BU_:  Airbag BAP_Tester ICAS1_Gateway ICAS1_KommunikationsServer LE1 LE2 Motor_BEV Schaltbetaetigung

BU_:  Airbag BAP_Tester ICAS1_Gateway ICAS1_KommunikationsServer LE1 LE2 Motor_BEV Schaltbetaetigung

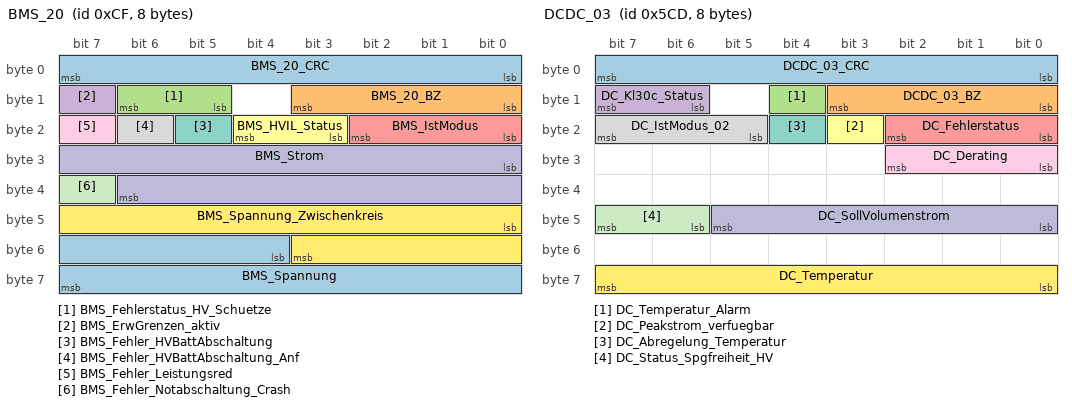
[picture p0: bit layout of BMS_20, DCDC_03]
BO_ 207 BMS_20: 8 ICAS1_Gateway
 SG_ BMS_20_CRC  : 0|8@1+ (1.000000,0.000000) [0.000000|255.000000] "" Motor_BEV
 SG_ BMS_20_BZ  : 8|4@1+ (1.000000,0.000000) [0.000000|15.000000] "" Motor_BEV
 SG_ BMS_Fehlerstatus_HV_Schuetze  : 13|2@1+ (1.000000,0.000000) [0.000000|3.000000] "" Motor_BEV
 SG_ BMS_ErwGrenzen_aktiv  : 15|1@1+ (1.000000,0.000000) [0.000000|1.000000] "" Motor_BEV
 SG_ BMS_IstModus  : 16|3@1+ (1.000000,0.000000) [0.000000|7.000000] "" LE1 LE2 Motor_BEV
 SG_ BMS_HVIL_Status  : 19|2@1+ (1.000000,0.000000) [0.000000|3.000000] "" Motor_BEV
 SG_ BMS_Fehler_HVBattAbschaltung  : 21|1@1+ (1.000000,0.000000) [0.000000|1.000000] "" Motor_BEV
 SG_ BMS_Fehler_HVBattAbschaltung_Anf  : 22|1@1+ (1.000000,0.000000) [0.000000|1.000000] "" Motor_BEV
 SG_ BMS_Fehler_Leistungsred  : 23|1@1+ (1.000000,0.000000) [0.000000|1.000000] "" Motor_BEV
 SG_ BMS_Strom  : 24|15@1+ (0.100000,-1630.000000) [-1630.000000|1630.000000] "Unit_Amper" Motor_BEV
 SG_ BMS_Fehler_Notabschaltung_Crash  : 39|1@1+ (1.000000,0.000000) [0.000000|1.000000] "" Vector__XXX
 SG_ BMS_Spannung_Zwischenkreis  : 40|12@1+ (0.500000,-1000.000000) [-1000.000000|1000.000000] "Unit_Volt" Motor_BEV
 SG_ BMS_Spannung  : 52|12@1+ (0.250000,0.000000) [0.000000|1000.000000] "Unit_Volt" Motor_BEV

BO_ 2463978704 BMS_21: 8 ICAS1_Gateway
 SG_ BMS_Max_Entladestrom  : 12|13@1+ (0.200000,0.000000) [0.000000|1630.000000] "Unit_Amper" Motor_BEV
 SG_ BMS_Max_Ladestrom  : 25|13@1+ (0.200000,0.000000) [0.000000|1630.000000] "Unit_Amper" Motor_BEV
 SG_ BMS_Max_Entladeleistung  : 38|13@1+ (100.000000,0.000000) [0.000000|818000.000000] "Unit_Watt" Motor_BEV
 SG_ BMS_Max_Ladeleistung  : 51|13@1+ (100.000000,0.000000) [0.000000|818000.000000] "Unit_Watt" Motor_BEV

BO_ 2463978705 BMS_22: 8 ICAS1_Gateway
 SG_ BMS_Status_EoHVL_Heizer  : 15|2@1+ (1.000000,0.000000) [0.000000|3.000000] "" Motor_BEV
 SG_ BMS_Ladezustand  : 17|11@1+ (0.050000,0.000000) [0.000000|100.000000] "Unit_PerCent" Motor_BEV
 SG_ BMS_PerfInd_Entladen  : 28|10@1+ (0.200000,0.000000) [0.000000|200.000000] "Unit_PerCent" Motor_BEV
 SG_ BMS_PerfInd_Laden  : 38|10@1+ (0.200000,0.000000) [0.000000|200.000000] "Unit_PerCent" Motor_BEV
 SG_ BMS_Nutzbare_EntladeEnergie  : 48|16@1+ (5.000000,0.000000) [0.000000|327400.000000] "Unit_WattHour" Motor_BEV

BO_ 2589283664 BMS_24: 8 ICAS1_Gateway
 SG_ BMS_Balancing_Aktiv  : 14|2@1+ (1.000000,0.000000) [0.000000|3.000000] "" Vector__XXX
 SG_ BMS_Ladevorgang_aktiv  : 16|1@1+ (1.000000,0.000000) [0.000000|1.000000] "" Vector__XXX
 SG_ BMS_RIso_Ext  : 17|12@1+ (5.000000,0.000000) [0.000000|20465.000000] "Unit_KiloOhm" Motor_BEV
 SG_ BMS_Min_Ladezustand  : 29|11@1+ (0.050000,0.000000) [0.000000|100.000000] "Unit_PerCent" Motor_BEV
 SG_ BMS_Max_Energie  : 40|13@1+ (40.000000,0.000000) [0.000000|327400.000000] "Unit_WattHour" Motor_BEV
 SG_ BMS_Max_Ladezustand  : 53|11@1+ (0.050000,0.000000) [0.000000|100.000000] "Unit_PerCent" Motor_BEV

BO_ 2589283665 BMS_25: 8 ICAS1_Gateway
 SG_ BMS_BattHeizung_VerbautStatus  : 13|1@1+ (1.000000,0.000000) [0.000000|1.000000] "" Motor_BEV
 SG_ BMS_Fehler_NTKreis  : 14|1@1+ (1.000000,0.000000) [0.000000|1.000000] "" Vector__XXX
 SG_ BMS_Temperierung_Anf  : 15|3@1+ (1.000000,0.000000) [0.000000|7.000000] "" Motor_BEV
 SG_ BMS_Status_Ventil1  : 18|3@1+ (1.000000,0.000000) [0.000000|7.000000] "" Motor_BEV
 SG_ BMS_Status_Ventil2  : 21|3@1+ (1.000000,0.000000) [0.000000|7.000000] "" Motor_BEV
 SG_ BMS_Pumpe1_Ansteuerung  : 24|4@1+ (10.000000,0.000000) [0.000000|100.000000] "Unit_PerCent" Motor_BEV
 SG_ BMS_Pumpe2_Ansteuerung  : 28|4@1+ (10.000000,0.000000) [0.000000|100.000000] "Unit_PerCent" Motor_BEV
 SG_ BMS_VorlaufTemperatur  : 32|8@1+ (0.500000,-40.000000) [-40.000000|86.000000] "Unit_DegreCelsi" Motor_BEV
 SG_ BMS_Temperatur  : 40|8@1+ (0.500000,-40.000000) [-40.000000|86.500000] "Unit_DegreCelsi" Motor_BEV
 SG_ BMS_SollVorlauftemperatur  : 48|8@1+ (0.500000,-40.000000) [-40.000000|86.500000] "Unit_DegreCelsi" Motor_BEV
 SG_ BMS_RuecklaufTemperatur  : 56|8@1+ (0.500000,-40.000000) [-40.000000|86.000000] "Unit_DegreCelsi" Motor_BEV

BO_ 2589283760 BMS_26: 8 ICAS1_Gateway
 SG_ BMS_Max_Spannung  : 20|10@1+ (1.000000,0.000000) [0.000000|1000.000000] "Unit_Volt" Motor_BEV
 SG_ BMS_Min_Spannung  : 30|10@1+ (1.000000,0.000000) [0.000000|1000.000000] "Unit_Volt" Motor_BEV
 SG_ BMS_Dauer_Entladeleistung  : 40|12@1+ (200.000000,0.000000) [0.000000|818000.000000] "Unit_Watt" Motor_BEV
 SG_ BMS_Dauer_Ladeleistung  : 52|12@1+ (200.000000,0.000000) [0.000000|818000.000000] "Unit_Watt" Motor_BEV

BO_ 2463978646 Charisma_11: 24 ICAS1_Gateway
 SG_ CHA_Ziel_FahrPr_AGA  : 0|4@1+ (1.000000,0.000000) [0.000000|15.000000] "" Vector__XXX
 SG_ CHA_Ziel_FahrPr_ESP  : 4|4@1+ (1.000000,0.000000) [0.000000|15.000000] "" Motor_BEV
 SG_ CHA_Ziel_FahrPr_Freilauf  : 8|4@1+ (1.000000,0.000000) [0.000000|15.000000] "" Vector__XXX
 SG_ CHA_Fahrer_Umschaltung  : 14|1@1+ (1.000000,0.000000) [0.000000|1.000000] "" Motor_BEV
 SG_ CHA_Fahrer_Umschaltung_BMA  : 15|1@1+ (1.000000,0.000000) [0.000000|1.000000] "" Vector__XXX
 SG_ CHA_Ziel_FahrPr_MO  : 16|4@1+ (1.000000,0.000000) [0.000000|15.000000] "" Motor_BEV
 SG_ CHA_Ziel_FahrPr_GE  : 20|4@1+ (1.000000,0.000000) [0.000000|15.000000] "" Vector__XXX
 SG_ CHA_Ziel_FahrPr_ALR  : 24|4@1+ (1.000000,0.000000) [0.000000|15.000000] "" Motor_BEV
 SG_ CHA_Ziel_FahrPr_MO_BZS  : 28|4@1+ (1.000000,0.000000) [0.000000|15.000000] "" Vector__XXX
 SG_ CHA_Ziel_FahrPr_DR  : 32|4@1+ (1.000000,0.000000) [0.000000|15.000000] "" Vector__XXX
 SG_ CHA_Ziel_FahrPr_VAQ  : 36|4@1+ (1.000000,0.000000) [0.000000|15.000000] "" Vector__XXX
 SG_ CHA_Ziel_FahrPr_AFS  : 40|4@1+ (1.000000,0.000000) [0.000000|15.000000] "" Vector__XXX
 SG_ CHA_Ziel_FahrPr_PreCrash  : 44|4@1+ (1.000000,0.000000) [0.000000|15.000000] "" Airbag
 SG_ CHA_Ziel_FahrPr_EPS  : 48|4@1+ (1.000000,0.000000) [0.000000|15.000000] "" Vector__XXX
 SG_ CHA_Ziel_FahrPr_ACC  : 52|4@1+ (1.000000,0.000000) [0.000000|15.000000] "" Vector__XXX
 SG_ CHA_Ziel_FahrPr_SAK  : 56|4@1+ (1.000000,0.000000) [0.000000|15.000000] "" Vector__XXX
 SG_ CHA_Ziel_FahrPr_MO_StSt  : 60|4@1+ (1.000000,0.000000) [0.000000|15.000000] "" Vector__XXX
 SG_ CHA_Ziel_FahrPr_EBKV  : 64|4@1+ (1.000000,0.000000) [0.000000|15.000000] "" Vector__XXX
 SG_ CHA_Ziel_FahrPr_IL  : 68|4@1+ (1.000000,0.000000) [0.000000|15.000000] "" Vector__XXX
 SG_ CHA_Current_Mode  : 72|4@1+ (1.000000,0.000000) [0.000000|15.000000] "" Vector__XXX
 SG_ CHA_Ziel_FahrPr_QS  : 80|4@1+ (1.000000,0.000000) [0.000000|15.000000] "" Vector__XXX
 SG_ CHA_Ziel_FahrPr_SCU  : 84|4@1+ (1.000000,0.000000) [0.000000|15.000000] "" Vector__XXX
 SG_ CHA_Ziel_FahrPr_HAL  : 88|4@1+ (1.000000,0.000000) [0.000000|15.000000] "" Vector__XXX
 SG_ CHA_Ziel_FahrPr_NR  : 92|4@1+ (1.000000,0.000000) [0.000000|15.000000] "" Vector__XXX
 SG_ CHA_Ziel_FahrPr_AV  : 96|4@1+ (1.000000,0.000000) [0.000000|15.000000] "" Vector__XXX
 SG_ CHA_Ziel_FahrPr_MXB  : 100|4@1+ (1.000000,0.000000) [0.000000|15.000000] "" Vector__XXX
 SG_ CHA_Ziel_FahrPr_AFR  : 104|4@1+ (1.000000,0.000000) [0.000000|15.000000] "" Vector__XXX
 SG_ CHA_Ziel_FahrPr_HDC  : 108|4@1+ (1.000000,0.000000) [0.000000|15.000000] "" Vector__XXX
 SG_ CHA_Ziel_FahrPr_EAR  : 112|4@1+ (1.000000,0.000000) [0.000000|15.000000] "" Vector__XXX
 SG_ CHA_Ziel_FahrPr_AEB  : 116|4@1+ (1.000000,0.000000) [0.000000|15.000000] "" Vector__XXX
 SG_ CHA_Ziel_FahrPr_FCWO  : 120|4@1+ (1.000000,0.000000) [0.000000|15.000000] "" Vector__XXX
 SG_ CHA_Ziel_FahrPr_FCWP  : 124|4@1+ (1.000000,0.000000) [0.000000|15.000000] "" Vector__XXX
 SG_ CHA_Ziel_FahrPr_ToS_laengs  : 144|4@1+ (1.000000,0.000000) [0.000000|15.000000] "" Vector__XXX
 SG_ CHA_Ziel_FahrPr_ToS_quer  : 148|4@1+ (1.000000,0.000000) [0.000000|15.000000] "" Vector__XXX
 SG_ CHA_Ziel_FahrPr_mFDR  : 152|4@1+ (1.000000,0.000000) [0.000000|15.000000] "" Vector__XXX
 SG_ CHA_Ziel_FahrPr_Reku_ZwGas  : 156|4@1+ (1.000000,0.000000) [0.000000|15.000000] "" Vector__XXX
 SG_ CHA_Ziel_FahrPr_MO_Freilauf  : 160|4@1+ (1.000000,0.000000) [0.000000|15.000000] "" Vector__XXX
 SG_ CHA_Ziel_FahrPr_BMS  : 164|4@1+ (1.000000,0.000000) [0.000000|15.000000] "" Vector__XXX
 SG_ CHA_Current_Mode_BMA  : 168|4@1+ (1.000000,0.000000) [0.000000|15.000000] "" Vector__XXX
 SG_ CHA_Ziel_FahrPr_PDC  : 172|4@1+ (1.000000,0.000000) [0.000000|15.000000] "" Vector__XXX
 SG_ CHA_Ziel_FahrPr_HHC  : 176|4@1+ (1.000000,0.000000) [0.000000|15.000000] "" Vector__XXX
 SG_ CHA_Ziel_FahrPr_EDS  : 180|4@1+ (1.000000,0.000000) [0.000000|15.000000] "" Vector__XXX
 SG_ CHA_Ziel_FahrPr_PACC  : 184|4@1+ (1.000000,0.000000) [0.000000|15.000000] "" Vector__XXX
 SG_ CHA_Ziel_FahrPr_AGK  : 188|4@1+ (1.000000,0.000000) [0.000000|15.000000] "" Vector__XXX

BO_ 514 Daempfer_03: 32 ICAS1_Gateway
 SG_ DR_Aufbaubeschleunigung_HR  : 12|10@1+ (0.032700,-15.696000) [-15.696000|15.696000] "Unit_MeterPerSeconSquar" Motor_BEV
 SG_ DR_Aufbaubeschleunigung_VR  : 22|10@1+ (0.032700,-15.696000) [-15.696000|15.696000] "Unit_MeterPerSeconSquar" Motor_BEV
 SG_ DR_Aufbaubeschleunigung_VL  : 32|10@1+ (0.032700,-15.696000) [-15.696000|15.696000] "Unit_MeterPerSeconSquar" Motor_BEV
 SG_ DR_Aufbaubeschleunigung_HL  : 42|10@1+ (0.032700,-15.696000) [-15.696000|15.696000] "Unit_MeterPerSeconSquar" Motor_BEV
 SG_ DR_Funktionsstatus  : 52|2@1+ (1.000000,0.000000) [0.000000|3.000000] "" Vector__XXX
 SG_ DR_Drehwinkelsensortausch_VL  : 72|2@1+ (1.000000,0.000000) [1.000000|3.000000] "" Vector__XXX
 SG_ DR_Drehwinkelsensortausch_VR  : 74|2@1+ (1.000000,0.000000) [1.000000|3.000000] "" Vector__XXX
 SG_ DR_Drehwinkelsensortausch_HL  : 76|2@1+ (1.000000,0.000000) [1.000000|3.000000] "" Vector__XXX
 SG_ DR_Drehwinkelsensortausch_HR  : 78|2@1+ (1.000000,0.000000) [1.000000|3.000000] "" Vector__XXX
 SG_ DR_Drehwinkel_VL  : 80|12@1+ (0.088000,0.000000) [0.000000|359.920000] "" Vector__XXX
 SG_ DR_Drehwinkel_VR  : 92|12@1+ (0.088000,0.000000) [0.000000|359.920000] "" Vector__XXX
 SG_ DR_Drehwinkel_HL  : 104|12@1+ (0.088000,0.000000) [0.000000|359.920000] "" Vector__XXX
 SG_ DR_Drehwinkel_HR  : 116|12@1+ (0.088000,0.000000) [0.000000|359.920000] "" Vector__XXX

BO_ 1485 DCDC_03: 8 ICAS1_Gateway
 SG_ DCDC_03_CRC  : 0|8@1+ (1.000000,0.000000) [0.000000|255.000000] "" Motor_BEV
 SG_ DCDC_03_BZ  : 8|4@1+ (1.000000,0.000000) [0.000000|15.000000] "" Motor_BEV
 SG_ DC_Temperatur_Alarm  : 12|1@1+ (1.000000,0.000000) [0.000000|1.000000] "" Vector__XXX
 SG_ DC_Kl30c_Status  : 14|2@1+ (1.000000,0.000000) [0.000000|3.000000] "" Motor_BEV
 SG_ DC_Fehlerstatus  : 16|3@1+ (1.000000,0.000000) [0.000000|7.000000] "" Vector__XXX
 SG_ DC_Peakstrom_verfuegbar  : 19|1@1+ (1.000000,0.000000) [0.000000|1.000000] "" Vector__XXX
 SG_ DC_Abregelung_Temperatur  : 20|1@1+ (1.000000,0.000000) [0.000000|1.000000] "" Vector__XXX
 SG_ DC_IstModus_02  : 21|3@1+ (1.000000,0.000000) [0.000000|7.000000] "" Vector__XXX
 SG_ DC_Derating  : 24|3@1+ (1.000000,0.000000) [0.000000|7.000000] "" Vector__XXX
 SG_ DC_SollVolumenstrom  : 40|6@1+ (0.500000,0.000000) [0.000000|30.500000] "Unit_LiterPerMinut" Motor_BEV
 SG_ DC_Status_Spgfreiheit_HV  : 46|2@1+ (1.000000,0.000000) [0.000000|3.000000] "" Vector__XXX
 SG_ DC_Temperatur  : 56|8@1+ (1.000000,-40.000000) [-40.000000|213.000000] "Unit_DegreCelsi" Motor_BEV

BO_ 247 DCDC_04: 8 ICAS1_Gateway
 SG_ DCDC_04_CRC  : 0|8@1+ (1.000000,0.000000) [0.000000|255.000000] "" Vector__XXX
 SG_ DCDC_04_BZ  : 8|4@1+ (1.000000,0.000000) [0.000000|15.000000] "" Vector__XXX
 SG_ DC_Vorladung_Status  : 34|1@1+ (1.000000,0.000000) [0.000000|1.000000] "" Motor_BEV
 SG_ DC_Fehler_extern  : 35|1@1+ (1.000000,0.000000) [0.000000|1.000000] "" Motor_BEV
 SG_ DC_Fehler_intern  : 36|1@1+ (1.000000,0.000000) [0.000000|1.000000] "" Motor_BEV
 SG_ DC_Status_Spgfreiheit  : 37|2@1+ (1.000000,0.000000) [0.000000|3.000000] "" Motor_BEV
 SG_ DC_Status_EoHVL  : 39|2@1+ (1.000000,0.000000) [0.000000|3.000000] "" Motor_BEV
 SG_ DC_IstModus_02  : 41|3@1+ (1.000000,0.000000) [0.000000|7.000000] "" Motor_BEV
 SG_ DC_IstStrom_HV  : 44|10@1+ (0.100000,-51.100000) [-51.100000|51.000000] "Unit_Amper" Motor_BEV
 SG_ DC_IstLeistung_HV  : 54|10@1+ (10.000000,-4000.000000) [-4000.000000|6210.000000] "Unit_Watt" Motor_BEV

BO_ 2617027088 DEV_Airbag_ASM_01: 8 Airbag
 SG_ DEV_Airbag_ASM_01_Data  : 0|64@1+ (1.000000,0.000000) [0.000000|18446744073709551616.000000] "" Vector__XXX

BO_ 2617027072 DEV_Airbag_Resp_00: 8 Airbag
 SG_ DEV_Airbag_Resp_00_Data  : 0|64@1+ (1.000000,0.000000) [0.000000|18446744073709551616.000000] "" Vector__XXX

BO_ 2617027073 DEV_Airbag_Resp_01: 8 Airbag
 SG_ DEV_Airbag_Resp_01_Data  : 0|64@1+ (1.000000,0.000000) [0.000000|18446744073709551616.000000] "" Vector__XXX

BO_ 2617027074 DEV_Airbag_Resp_02: 8 Airbag
 SG_ DEV_Airbag_Resp_02_Data  : 0|64@1+ (1.000000,0.000000) [0.000000|18446744073709551616.000000] "" Vector__XXX

BO_ 2617027075 DEV_Airbag_Resp_03: 8 Airbag
 SG_ DEV_Airbag_Resp_03_Data  : 0|64@1+ (1.000000,0.000000) [0.000000|18446744073709551616.000000] "" Vector__XXX

BO_ 2617027076 DEV_Airbag_Resp_04: 8 Airbag
 SG_ DEV_Airbag_Resp_04_Data  : 0|64@1+ (1.000000,0.000000) [0.000000|18446744073709551616.000000] "" Vector__XXX

BO_ 2617027077 DEV_Airbag_Resp_05: 8 Airbag
 SG_ DEV_Airbag_Resp_05_Data  : 0|64@1+ (1.000000,0.000000) [0.000000|18446744073709551616.000000] "" Vector__XXX

BO_ 2617027078 DEV_Airbag_Resp_06: 8 Airbag
 SG_ DEV_Airbag_Resp_06_Data  : 0|64@1+ (1.000000,0.000000) [0.000000|18446744073709551616.000000] "" Vector__XXX

BO_ 2617027079 DEV_Airbag_Resp_07: 8 Airbag
 SG_ DEV_Airbag_Resp_07_Data  : 0|64@1+ (1.000000,0.000000) [0.000000|18446744073709551616.000000] "" Vector__XXX

BO_ 2617027080 DEV_Airbag_Resp_08: 8 Airbag
 SG_ DEV_Airbag_Resp_08_Data  : 0|64@1+ (1.000000,0.000000) [0.000000|18446744073709551616.000000] "" Vector__XXX

BO_ 2617027081 DEV_Airbag_Resp_09: 8 Airbag
 SG_ DEV_Airbag_Resp_09_Data  : 0|64@1+ (1.000000,0.000000) [0.000000|18446744073709551616.000000] "" Vector__XXX

BO_ 2617027082 DEV_Airbag_Resp_10: 8 Airbag
 SG_ DEV_Airbag_Resp_10_Data  : 0|64@1+ (1.000000,0.000000) [0.000000|18446744073709551616.000000] "" Vector__XXX

BO_ 2617027083 DEV_Airbag_Resp_11: 8 Airbag
 SG_ DEV_Airbag_Resp_11_Data  : 0|64@1+ (1.000000,0.000000) [0.000000|18446744073709551616.000000] "" Vector__XXX

BO_ 2617154048 DEV_Waehlhebel_Resp_00: 8 Schaltbetaetigung
 SG_ DEV_Waehlhebel_Resp_00_Data  : 0|64@1+ (1.000000,0.000000) [0.000000|18446744073709551616.000000] "" Vector__XXX

BO_ 2617154049 DEV_Waehlhebel_Resp_01: 8 Schaltbetaetigung
 SG_ DEV_Waehlhebel_Resp_01_Data  : 0|64@1+ (1.000000,0.000000) [0.000000|18446744073709551616.000000] "" Vector__XXX

BO_ 2617154050 DEV_Waehlhebel_Resp_02: 8 Schaltbetaetigung
 SG_ DEV_Waehlhebel_Resp_02_Data  : 0|64@1+ (1.000000,0.000000) [0.000000|18446744073709551616.000000] "" Vector__XXX

BO_ 2617154051 DEV_Waehlhebel_Resp_03: 8 Schaltbetaetigung
 SG_ DEV_Waehlhebel_Resp_03_Data  : 0|64@1+ (1.000000,0.000000) [0.000000|18446744073709551616.000000] "" Vector__XXX

BO_ 2617154052 DEV_Waehlhebel_Resp_04: 8 Schaltbetaetigung
 SG_ DEV_Waehlhebel_Resp_04_Data  : 0|64@1+ (1.000000,0.000000) [0.000000|18446744073709551616.000000] "" Vector__XXX

BO_ 2617154053 DEV_Waehlhebel_Resp_05: 8 Schaltbetaetigung
 SG_ DEV_Waehlhebel_Resp_05_Data  : 0|64@1+ (1.000000,0.000000) [0.000000|18446744073709551616.000000] "" Vector__XXX

BO_ 2549876269 Diag_Waehlhebel_Req: 8 Motor_BEV
 SG_ Diag_Waehlhebel_Req_Data  : 0|64@1+ (1.000000,0.000000) [0.000000|18446744073709551616.000000] "" Schaltbetaetigung

BO_ 2550007341 Diag_Waehlhebel_Resp: 8 Schaltbetaetigung
 SG_ Diag_Waehlhebel_Resp_Data  : 0|64@1+ (1.000000,0.000000) [0.000000|18446744073709551616.000000] "" Motor_BEV

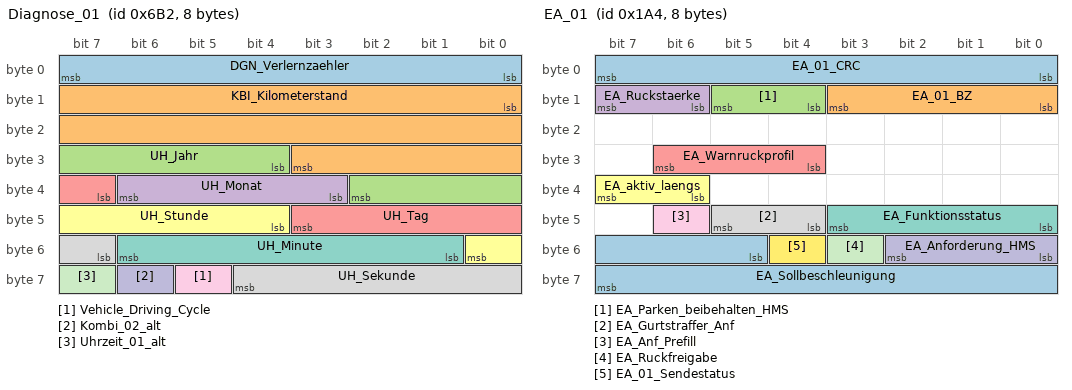
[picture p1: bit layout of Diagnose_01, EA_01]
BO_ 1714 Diagnose_01: 8 ICAS1_Gateway
 SG_ DGN_Verlernzaehler  : 0|8@1+ (1.000000,0.000000) [0.000000|254.000000] "" Airbag LE1 LE2 Motor_BEV
 SG_ KBI_Kilometerstand  : 8|20@1+ (1.000000,0.000000) [0.000000|1048573.000000] "Unit_KiloMeter" Airbag LE1 LE2 Motor_BEV
 SG_ UH_Jahr  : 28|7@1+ (1.000000,2000.000000) [2000.000000|2127.000000] "Unit_Year" Airbag LE1 LE2 Motor_BEV
 SG_ UH_Monat  : 35|4@1+ (1.000000,0.000000) [1.000000|12.000000] "Unit_Month" Airbag LE1 LE2 Motor_BEV
 SG_ UH_Tag  : 39|5@1+ (1.000000,0.000000) [1.000000|31.000000] "Unit_Day" Airbag LE1 LE2 Motor_BEV
 SG_ UH_Stunde  : 44|5@1+ (1.000000,0.000000) [0.000000|23.000000] "Unit_Hours" Airbag LE1 LE2 Motor_BEV
 SG_ UH_Minute  : 49|6@1+ (1.000000,0.000000) [0.000000|59.000000] "Unit_Minut" Airbag LE1 LE2 Motor_BEV
 SG_ UH_Sekunde  : 55|6@1+ (1.000000,0.000000) [0.000000|59.000000] "Unit_Secon" Airbag LE1 LE2 Motor_BEV
 SG_ Vehicle_Driving_Cycle  : 61|1@1+ (1.000000,0.000000) [0.000000|1.000000] "" Airbag
 SG_ Kombi_02_alt  : 62|1@1+ (1.000000,0.000000) [0.000000|1.000000] "" Vector__XXX
 SG_ Uhrzeit_01_alt  : 63|1@1+ (1.000000,0.000000) [0.000000|1.000000] "" Vector__XXX

BO_ 851 DiETa_01: 8 ICAS1_Gateway
 SG_ DiETas_01_CRC  : 0|8@1+ (1.000000,0.000000) [0.000000|255.000000] "" Airbag
 SG_ DiETas_01_BZ  : 8|4@1+ (1.000000,0.000000) [0.000000|15.000000] "" Airbag
 SG_ DiETa_Reserve_Byte2_4  : 12|1@1+ (1.000000,0.000000) [0.000000|1.000000] "" Vector__XXX
 SG_ DiETa_Status  : 13|2@1+ (1.000000,0.000000) [0.000000|3.000000] "" Airbag
 SG_ DiETa_ResponseError  : 15|1@1+ (1.000000,0.000000) [0.000000|1.000000] "" Vector__XXX
 SG_ DiETa_Car  : 16|2@1+ (1.000000,0.000000) [0.000000|3.000000] "" Vector__XXX
 SG_ DiETa_Klima  : 18|2@1+ (1.000000,0.000000) [0.000000|3.000000] "" Vector__XXX
 SG_ DiETa_Mode  : 20|2@1+ (1.000000,0.000000) [0.000000|3.000000] "" Vector__XXX
 SG_ DiETa_Parken  : 22|2@1+ (1.000000,0.000000) [0.000000|3.000000] "" Vector__XXX
 SG_ DiETa_FSH_Taste  : 24|2@1+ (1.000000,0.000000) [0.000000|3.000000] "" Vector__XXX
 SG_ DiETa_HSH_Taste  : 26|2@1+ (1.000000,0.000000) [0.000000|3.000000] "" Vector__XXX
 SG_ DiETa_Warnblink_Taste  : 28|2@1+ (1.000000,0.000000) [0.000000|3.000000] "" Vector__XXX
 SG_ DiETa_FAS_Stufe  : 30|2@1+ (1.000000,0.000000) [0.000000|3.000000] "" Vector__XXX
 SG_ DiETa_PAO_ON_Status  : 32|2@1+ (1.000000,0.000000) [0.000000|3.000000] "" Airbag
 SG_ DiETa_PAO_OFF_Status  : 34|2@1+ (1.000000,0.000000) [0.000000|3.000000] "" Airbag
 SG_ DiETa_Defrost_Taste  : 36|2@1+ (1.000000,0.000000) [0.000000|3.000000] "" Vector__XXX
 SG_ DiETa_Reserve_Byte5_6  : 38|2@1+ (1.000000,0.000000) [0.000000|3.000000] "" Vector__XXX
 SG_ DiETa_Lock_Unlock_Taste  : 40|3@1+ (1.000000,0.000000) [0.000000|7.000000] "" Vector__XXX
 SG_ DiETa_Mode_roh  : 43|1@1+ (1.000000,0.000000) [0.000000|1.000000] "" Vector__XXX
 SG_ DiETa_Reserve_Byte6_3  : 44|4@1+ (1.000000,0.000000) [0.000000|15.000000] "" Vector__XXX
 SG_ DiETa_Reserve_Byte7  : 48|8@1+ (1.000000,0.000000) [0.000000|255.000000] "" Vector__XXX
 SG_ DiETa_Reserve_Byte8  : 56|8@1+ (1.000000,0.000000) [0.000000|255.000000] "" Vector__XXX

BO_ 1520 Dimmung_01: 8 ICAS1_Gateway
 SG_ DI_KL_58xd  : 0|8@1+ (1.000000,0.000000) [0.000000|253.000000] "" Airbag Schaltbetaetigung
 SG_ DI_KL_58xs  : 8|7@1+ (1.000000,0.000000) [0.000000|100.000000] "Unit_PerCent" Airbag
 SG_ DI_Display_Nachtdesign  : 15|1@1+ (1.000000,0.000000) [0.000000|1.000000] "" Vector__XXX
 SG_ DI_KL_58xt  : 16|7@1+ (1.000000,0.000000) [0.000000|100.000000] "Unit_PerCent" Airbag Schaltbetaetigung
 SG_ DI_Fotosensor  : 24|16@1+ (1.000000,0.000000) [0.000000|65535.000000] "" Vector__XXX
 SG_ BCM1_Stellgroesse_Kl_58s  : 40|7@1+ (1.000000,0.000000) [0.000000|100.000000] "" Vector__XXX

BO_ 420 EA_01: 8 ICAS1_Gateway
 SG_ EA_01_CRC  : 0|8@1+ (1.000000,0.000000) [0.000000|255.000000] "" Motor_BEV
 SG_ EA_01_BZ  : 8|4@1+ (1.000000,0.000000) [0.000000|15.000000] "" Motor_BEV
 SG_ EA_Parken_beibehalten_HMS  : 12|2@1+ (1.000000,0.000000) [0.000000|3.000000] "" Vector__XXX
 SG_ EA_Ruckstaerke  : 14|2@1+ (1.000000,0.000000) [0.000000|3.000000] "" Vector__XXX
 SG_ EA_Warnruckprofil  : 28|3@1+ (1.000000,0.000000) [0.000000|7.000000] "" Vector__XXX
 SG_ EA_aktiv_laengs  : 38|2@1+ (1.000000,0.000000) [0.000000|3.000000] "" Motor_BEV
 SG_ EA_Funktionsstatus  : 40|4@1+ (1.000000,0.000000) [0.000000|15.000000] "" Motor_BEV
 SG_ EA_Gurtstraffer_Anf  : 44|2@1+ (1.000000,0.000000) [0.000000|3.000000] "" Airbag
 SG_ EA_Anf_Prefill  : 46|1@1+ (1.000000,0.000000) [0.000000|1.000000] "" Vector__XXX
 SG_ EA_Anforderung_HMS  : 48|3@1+ (1.000000,0.000000) [0.000000|7.000000] "" Vector__XXX
 SG_ EA_Ruckfreigabe  : 51|1@1+ (1.000000,0.000000) [0.000000|1.000000] "" Vector__XXX
 SG_ EA_01_Sendestatus  : 52|1@1+ (1.000000,0.000000) [0.000000|1.000000] "" Vector__XXX
 SG_ EA_Sollbeschleunigung  : 53|11@1+ (0.005000,-7.220000) [-7.220000|3.005000] "Unit_MeterPerSeconSquar" Motor_BEV

BO_ 374 EBKV_03: 8 ICAS1_Gateway
 SG_ EBKV_03_CRC  : 0|8@1+ (1.000000,0.000000) [0.000000|255.000000] "" Vector__XXX
 SG_ EBKV_03_BZ  : 8|4@1+ (1.000000,0.000000) [0.000000|15.000000] "" Vector__XXX
 SG_ EBKV_Activate_Fallback_ESP  : 12|1@1+ (1.000000,0.000000) [0.000000|1.000000] "" Vector__XXX
 SG_ EBKV_Restdruckabsenkung  : 13|3@1+ (1.000000,0.000000) [0.000000|7.000000] "" Vector__XXX
 SG_ EBKV_Status_02  : 16|4@1+ (1.000000,0.000000) [0.000000|15.000000] "" Vector__XXX
 SG_ EBKV_Diagnose  : 20|1@1+ (1.000000,0.000000) [0.000000|1.000000] "" Vector__XXX
 SG_ EBKV_Fahrer_bremst  : 21|1@1+ (1.000000,0.000000) [0.000000|1.000000] "" Motor_BEV
 SG_ EBKV_QBit_Fahrer_bremst  : 22|1@1+ (1.000000,0.000000) [0.000000|1.000000] "" Motor_BEV
 SG_ EBKV_Fahrer_bremst_deutlich  : 23|1@1+ (1.000000,0.000000) [0.000000|1.000000] "" Vector__XXX
 SG_ EBKV_OBD_Status  : 24|1@1+ (1.000000,0.000000) [0.000000|1.000000] "" Motor_BEV
 SG_ EBKV_VMM_Sek_Notstopp_Status  : 25|3@1+ (1.000000,0.000000) [0.000000|7.000000] "" Vector__XXX
 SG_ EBKV_Anforderung_HMS  : 28|3@1+ (1.000000,0.000000) [0.000000|7.000000] "" Vector__XXX
 SG_ SBS_Anforderung_GE  : 31|1@1+ (1.000000,0.000000) [0.000000|1.000000] "" Vector__XXX
 SG_ EPB_Status_ext  : 32|3@1+ (1.000000,0.000000) [0.000000|7.000000] "" Motor_BEV
 SG_ EBKV_Bremspedalweg  : 40|8@1+ (0.400000,-0.400000) [0.000000|101.200000] "Unit_PerCent" Motor_BEV
 SG_ EBKV_Kraftblending_Reserve  : 48|8@1+ (0.500000,0.000000) [0.000000|125.000000] "Unit_Bar" Vector__XXX
 SG_ EBKV_Aussteuerdruck  : 56|8@1+ (1.000000,0.000000) [0.000000|250.000000] "Unit_Bar" Vector__XXX

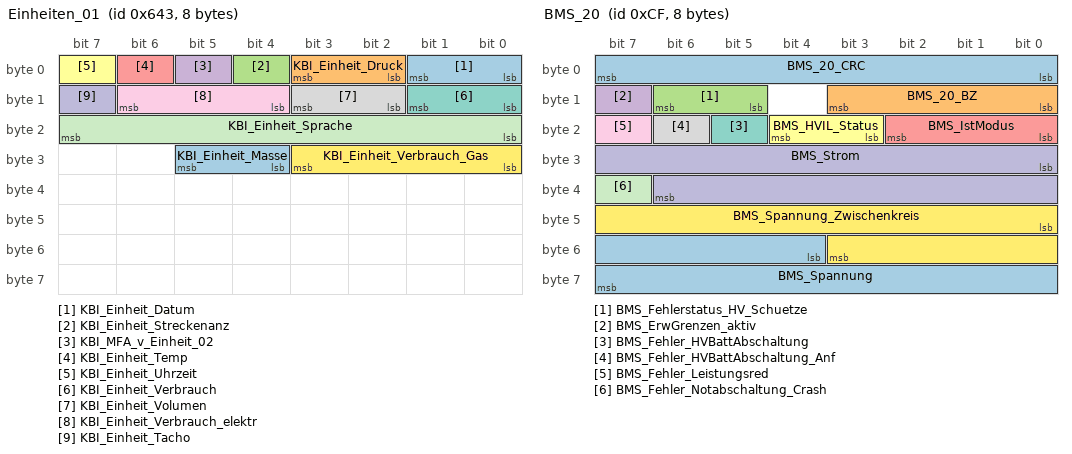
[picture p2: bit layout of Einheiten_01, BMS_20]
BO_ 1603 Einheiten_01: 8 ICAS1_KommunikationsServer
 SG_ KBI_Einheit_Datum  : 0|2@1+ (1.000000,0.000000) [0.000000|3.000000] "" Vector__XXX
 SG_ KBI_Einheit_Druck  : 2|2@1+ (1.000000,0.000000) [0.000000|3.000000] "" Vector__XXX
 SG_ KBI_Einheit_Streckenanz  : 4|1@1+ (1.000000,0.000000) [0.000000|1.000000] "" Vector__XXX
 SG_ KBI_MFA_v_Einheit_02  : 5|1@1+ (1.000000,0.000000) [0.000000|1.000000] "" Motor_BEV
 SG_ KBI_Einheit_Temp  : 6|1@1+ (1.000000,0.000000) [0.000000|1.000000] "" Vector__XXX
 SG_ KBI_Einheit_Uhrzeit  : 7|1@1+ (1.000000,0.000000) [0.000000|1.000000] "" Vector__XXX
 SG_ KBI_Einheit_Verbrauch  : 8|2@1+ (1.000000,0.000000) [0.000000|3.000000] "" Vector__XXX
 SG_ KBI_Einheit_Volumen  : 10|2@1+ (1.000000,0.000000) [0.000000|3.000000] "" Vector__XXX
 SG_ KBI_Einheit_Verbrauch_elektr  : 12|3@1+ (1.000000,0.000000) [0.000000|7.000000] "" Vector__XXX
 SG_ KBI_Einheit_Tacho  : 15|1@1+ (1.000000,0.000000) [0.000000|1.000000] "" Motor_BEV
 SG_ KBI_Einheit_Sprache  : 16|8@1+ (1.000000,0.000000) [0.000000|255.000000] "" Vector__XXX
 SG_ KBI_Einheit_Verbrauch_Gas  : 24|4@1+ (1.000000,0.000000) [0.000000|15.000000] "" Vector__XXX
 SG_ KBI_Einheit_Masse  : 28|2@1+ (1.000000,0.000000) [0.000000|3.000000] "" Vector__XXX

BU_:  Airbag BAP_Tester ICAS1_Gateway ICAS1_KommunikationsServer LE1 LE2 Motor_BEV Schaltbetaetigung

BO_ 207 BMS_20: 8 ICAS1_Gateway
 SG_ BMS_20_CRC  : 0|8@1+ (1.000000,0.000000) [0.000000|255.000000] "" Motor_BEV
 SG_ BMS_20_BZ  : 8|4@1+ (1.000000,0.000000) [0.000000|15.000000] "" Motor_BEV
 SG_ BMS_Fehlerstatus_HV_Schuetze  : 13|2@1+ (1.000000,0.000000) [0.000000|3.000000] "" Motor_BEV
 SG_ BMS_ErwGrenzen_aktiv  : 15|1@1+ (1.000000,0.000000) [0.000000|1.000000] "" Motor_BEV
 SG_ BMS_IstModus  : 16|3@1+ (1.000000,0.000000) [0.000000|7.000000] "" LE1 LE2 Motor_BEV
 SG_ BMS_HVIL_Status  : 19|2@1+ (1.000000,0.000000) [0.000000|3.000000] "" Motor_BEV
 SG_ BMS_Fehler_HVBattAbschaltung  : 21|1@1+ (1.000000,0.000000) [0.000000|1.000000] "" Motor_BEV
 SG_ BMS_Fehler_HVBattAbschaltung_Anf  : 22|1@1+ (1.000000,0.000000) [0.000000|1.000000] "" Motor_BEV
 SG_ BMS_Fehler_Leistungsred  : 23|1@1+ (1.000000,0.000000) [0.000000|1.000000] "" Motor_BEV
 SG_ BMS_Strom  : 24|15@1+ (0.100000,-1630.000000) [-1630.000000|1630.000000] "Unit_Amper" Motor_BEV
 SG_ BMS_Fehler_Notabschaltung_Crash  : 39|1@1+ (1.000000,0.000000) [0.000000|1.000000] "" Vector__XXX
 SG_ BMS_Spannung_Zwischenkreis  : 40|12@1+ (0.500000,-1000.000000) [-1000.000000|1000.000000] "Unit_Volt" Motor_BEV
 SG_ BMS_Spannung  : 52|12@1+ (0.250000,0.000000) [0.000000|1000.000000] "Unit_Volt" Motor_BEV

BO_ 2463978704 BMS_21: 8 ICAS1_Gateway
 SG_ BMS_Max_Entladestrom  : 12|13@1+ (0.200000,0.000000) [0.000000|1630.000000] "Unit_Amper" Motor_BEV
 SG_ BMS_Max_Ladestrom  : 25|13@1+ (0.200000,0.000000) [0.000000|1630.000000] "Unit_Amper" Motor_BEV
 SG_ BMS_Max_Entladeleistung  : 38|13@1+ (100.000000,0.000000) [0.000000|818000.000000] "Unit_Watt" Motor_BEV
 SG_ BMS_Max_Ladeleistung  : 51|13@1+ (100.000000,0.000000) [0.000000|818000.000000] "Unit_Watt" Motor_BEV

BO_ 2463978705 BMS_22: 8 ICAS1_Gateway
 SG_ BMS_Status_EoHVL_Heizer  : 15|2@1+ (1.000000,0.000000) [0.000000|3.000000] "" Motor_BEV
 SG_ BMS_Ladezustand  : 17|11@1+ (0.050000,0.000000) [0.000000|100.000000] "Unit_PerCent" Motor_BEV
 SG_ BMS_PerfInd_Entladen  : 28|10@1+ (0.200000,0.000000) [0.000000|200.000000] "Unit_PerCent" Motor_BEV
 SG_ BMS_PerfInd_Laden  : 38|10@1+ (0.200000,0.000000) [0.000000|200.000000] "Unit_PerCent" Motor_BEV
 SG_ BMS_Nutzbare_EntladeEnergie  : 48|16@1+ (5.000000,0.000000) [0.000000|327400.000000] "Unit_WattHour" Motor_BEV

BO_ 2589283664 BMS_24: 8 ICAS1_Gateway
 SG_ BMS_Balancing_Aktiv  : 14|2@1+ (1.000000,0.000000) [0.000000|3.000000] "" Vector__XXX
 SG_ BMS_Ladevorgang_aktiv  : 16|1@1+ (1.000000,0.000000) [0.000000|1.000000] "" Vector__XXX
 SG_ BMS_RIso_Ext  : 17|12@1+ (5.000000,0.000000) [0.000000|20465.000000] "Unit_KiloOhm" Motor_BEV
 SG_ BMS_Min_Ladezustand  : 29|11@1+ (0.050000,0.000000) [0.000000|100.000000] "Unit_PerCent" Motor_BEV
 SG_ BMS_Max_Energie  : 40|13@1+ (40.000000,0.000000) [0.000000|327400.000000] "Unit_WattHour" Motor_BEV
 SG_ BMS_Max_Ladezustand  : 53|11@1+ (0.050000,0.000000) [0.000000|100.000000] "Unit_PerCent" Motor_BEV

BO_ 2589283665 BMS_25: 8 ICAS1_Gateway
 SG_ BMS_BattHeizung_VerbautStatus  : 13|1@1+ (1.000000,0.000000) [0.000000|1.000000] "" Motor_BEV
 SG_ BMS_Fehler_NTKreis  : 14|1@1+ (1.000000,0.000000) [0.000000|1.000000] "" Vector__XXX
 SG_ BMS_Temperierung_Anf  : 15|3@1+ (1.000000,0.000000) [0.000000|7.000000] "" Motor_BEV
 SG_ BMS_Status_Ventil1  : 18|3@1+ (1.000000,0.000000) [0.000000|7.000000] "" Motor_BEV
 SG_ BMS_Status_Ventil2  : 21|3@1+ (1.000000,0.000000) [0.000000|7.000000] "" Motor_BEV
 SG_ BMS_Pumpe1_Ansteuerung  : 24|4@1+ (10.000000,0.000000) [0.000000|100.000000] "Unit_PerCent" Motor_BEV
 SG_ BMS_Pumpe2_Ansteuerung  : 28|4@1+ (10.000000,0.000000) [0.000000|100.000000] "Unit_PerCent" Motor_BEV
 SG_ BMS_VorlaufTemperatur  : 32|8@1+ (0.500000,-40.000000) [-40.000000|86.000000] "Unit_DegreCelsi" Motor_BEV
 SG_ BMS_Temperatur  : 40|8@1+ (0.500000,-40.000000) [-40.000000|86.500000] "Unit_DegreCelsi" Motor_BEV
 SG_ BMS_SollVorlauftemperatur  : 48|8@1+ (0.500000,-40.000000) [-40.000000|86.500000] "Unit_DegreCelsi" Motor_BEV
 SG_ BMS_RuecklaufTemperatur  : 56|8@1+ (0.500000,-40.000000) [-40.000000|86.000000] "Unit_DegreCelsi" Motor_BEV

BO_ 2589283760 BMS_26: 8 ICAS1_Gateway
 SG_ BMS_Max_Spannung  : 20|10@1+ (1.000000,0.000000) [0.000000|1000.000000] "Unit_Volt" Motor_BEV
 SG_ BMS_Min_Spannung  : 30|10@1+ (1.000000,0.000000) [0.000000|1000.000000] "Unit_Volt" Motor_BEV
 SG_ BMS_Dauer_Entladeleistung  : 40|12@1+ (200.000000,0.000000) [0.000000|818000.000000] "Unit_Watt" Motor_BEV
 SG_ BMS_Dauer_Ladeleistung  : 52|12@1+ (200.000000,0.000000) [0.000000|818000.000000] "Unit_Watt" Motor_BEV

BO_ 2463978646 Charisma_11: 24 ICAS1_Gateway
 SG_ CHA_Ziel_FahrPr_AGA  : 0|4@1+ (1.000000,0.000000) [0.000000|15.000000] "" Vector__XXX
 SG_ CHA_Ziel_FahrPr_ESP  : 4|4@1+ (1.000000,0.000000) [0.000000|15.000000] "" Motor_BEV
 SG_ CHA_Ziel_FahrPr_Freilauf  : 8|4@1+ (1.000000,0.000000) [0.000000|15.000000] "" Vector__XXX
 SG_ CHA_Fahrer_Umschaltung  : 14|1@1+ (1.000000,0.000000) [0.000000|1.000000] "" Motor_BEV
 SG_ CHA_Fahrer_Umschaltung_BMA  : 15|1@1+ (1.000000,0.000000) [0.000000|1.000000] "" Vector__XXX
 SG_ CHA_Ziel_FahrPr_MO  : 16|4@1+ (1.000000,0.000000) [0.000000|15.000000] "" Motor_BEV
 SG_ CHA_Ziel_FahrPr_GE  : 20|4@1+ (1.000000,0.000000) [0.000000|15.000000] "" Vector__XXX
 SG_ CHA_Ziel_FahrPr_ALR  : 24|4@1+ (1.000000,0.000000) [0.000000|15.000000] "" Motor_BEV
 SG_ CHA_Ziel_FahrPr_MO_BZS  : 28|4@1+ (1.000000,0.000000) [0.000000|15.000000] "" Vector__XXX
 SG_ CHA_Ziel_FahrPr_DR  : 32|4@1+ (1.000000,0.000000) [0.000000|15.000000] "" Vector__XXX
 SG_ CHA_Ziel_FahrPr_VAQ  : 36|4@1+ (1.000000,0.000000) [0.000000|15.000000] "" Vector__XXX
 SG_ CHA_Ziel_FahrPr_AFS  : 40|4@1+ (1.000000,0.000000) [0.000000|15.000000] "" Vector__XXX
 SG_ CHA_Ziel_FahrPr_PreCrash  : 44|4@1+ (1.000000,0.000000) [0.000000|15.000000] "" Airbag
 SG_ CHA_Ziel_FahrPr_EPS  : 48|4@1+ (1.000000,0.000000) [0.000000|15.000000] "" Vector__XXX
 SG_ CHA_Ziel_FahrPr_ACC  : 52|4@1+ (1.000000,0.000000) [0.000000|15.000000] "" Vector__XXX
 SG_ CHA_Ziel_FahrPr_SAK  : 56|4@1+ (1.000000,0.000000) [0.000000|15.000000] "" Vector__XXX
 SG_ CHA_Ziel_FahrPr_MO_StSt  : 60|4@1+ (1.000000,0.000000) [0.000000|15.000000] "" Vector__XXX
 SG_ CHA_Ziel_FahrPr_EBKV  : 64|4@1+ (1.000000,0.000000) [0.000000|15.000000] "" Vector__XXX
 SG_ CHA_Ziel_FahrPr_IL  : 68|4@1+ (1.000000,0.000000) [0.000000|15.000000] "" Vector__XXX
 SG_ CHA_Current_Mode  : 72|4@1+ (1.000000,0.000000) [0.000000|15.000000] "" Vector__XXX
 SG_ CHA_Ziel_FahrPr_QS  : 80|4@1+ (1.000000,0.000000) [0.000000|15.000000] "" Vector__XXX
 SG_ CHA_Ziel_FahrPr_SCU  : 84|4@1+ (1.000000,0.000000) [0.000000|15.000000] "" Vector__XXX
 SG_ CHA_Ziel_FahrPr_HAL  : 88|4@1+ (1.000000,0.000000) [0.000000|15.000000] "" Vector__XXX
 SG_ CHA_Ziel_FahrPr_NR  : 92|4@1+ (1.000000,0.000000) [0.000000|15.000000] "" Vector__XXX
 SG_ CHA_Ziel_FahrPr_AV  : 96|4@1+ (1.000000,0.000000) [0.000000|15.000000] "" Vector__XXX
 SG_ CHA_Ziel_FahrPr_MXB  : 100|4@1+ (1.000000,0.000000) [0.000000|15.000000] "" Vector__XXX
 SG_ CHA_Ziel_FahrPr_AFR  : 104|4@1+ (1.000000,0.000000) [0.000000|15.000000] "" Vector__XXX
 SG_ CHA_Ziel_FahrPr_HDC  : 108|4@1+ (1.000000,0.000000) [0.000000|15.000000] "" Vector__XXX
 SG_ CHA_Ziel_FahrPr_EAR  : 112|4@1+ (1.000000,0.000000) [0.000000|15.000000] "" Vector__XXX
 SG_ CHA_Ziel_FahrPr_AEB  : 116|4@1+ (1.000000,0.000000) [0.000000|15.000000] "" Vector__XXX
 SG_ CHA_Ziel_FahrPr_FCWO  : 120|4@1+ (1.000000,0.000000) [0.000000|15.000000] "" Vector__XXX
 SG_ CHA_Ziel_FahrPr_FCWP  : 124|4@1+ (1.000000,0.000000) [0.000000|15.000000] "" Vector__XXX
 SG_ CHA_Ziel_FahrPr_ToS_laengs  : 144|4@1+ (1.000000,0.000000) [0.000000|15.000000] "" Vector__XXX
 SG_ CHA_Ziel_FahrPr_ToS_quer  : 148|4@1+ (1.000000,0.000000) [0.000000|15.000000] "" Vector__XXX
 SG_ CHA_Ziel_FahrPr_mFDR  : 152|4@1+ (1.000000,0.000000) [0.000000|15.000000] "" Vector__XXX
 SG_ CHA_Ziel_FahrPr_Reku_ZwGas  : 156|4@1+ (1.000000,0.000000) [0.000000|15.000000] "" Vector__XXX
 SG_ CHA_Ziel_FahrPr_MO_Freilauf  : 160|4@1+ (1.000000,0.000000) [0.000000|15.000000] "" Vector__XXX
 SG_ CHA_Ziel_FahrPr_BMS  : 164|4@1+ (1.000000,0.000000) [0.000000|15.000000] "" Vector__XXX
 SG_ CHA_Current_Mode_BMA  : 168|4@1+ (1.000000,0.000000) [0.000000|15.000000] "" Vector__XXX
 SG_ CHA_Ziel_FahrPr_PDC  : 172|4@1+ (1.000000,0.000000) [0.000000|15.000000] "" Vector__XXX
 SG_ CHA_Ziel_FahrPr_HHC  : 176|4@1+ (1.000000,0.000000) [0.000000|15.000000] "" Vector__XXX
 SG_ CHA_Ziel_FahrPr_EDS  : 180|4@1+ (1.000000,0.000000) [0.000000|15.000000] "" Vector__XXX
 SG_ CHA_Ziel_FahrPr_PACC  : 184|4@1+ (1.000000,0.000000) [0.000000|15.000000] "" Vector__XXX
 SG_ CHA_Ziel_FahrPr_AGK  : 188|4@1+ (1.000000,0.000000) [0.000000|15.000000] "" Vector__XXX

BO_ 514 Daempfer_03: 32 ICAS1_Gateway
 SG_ DR_Aufbaubeschleunigung_HR  : 12|10@1+ (0.032700,-15.696000) [-15.696000|15.696000] "Unit_MeterPerSeconSquar" Motor_BEV
 SG_ DR_Aufbaubeschleunigung_VR  : 22|10@1+ (0.032700,-15.696000) [-15.696000|15.696000] "Unit_MeterPerSeconSquar" Motor_BEV
 SG_ DR_Aufbaubeschleunigung_VL  : 32|10@1+ (0.032700,-15.696000) [-15.696000|15.696000] "Unit_MeterPerSeconSquar" Motor_BEV
 SG_ DR_Aufbaubeschleunigung_HL  : 42|10@1+ (0.032700,-15.696000) [-15.696000|15.696000] "Unit_MeterPerSeconSquar" Motor_BEV
 SG_ DR_Funktionsstatus  : 52|2@1+ (1.000000,0.000000) [0.000000|3.000000] "" Vector__XXX
 SG_ DR_Drehwinkelsensortausch_VL  : 72|2@1+ (1.000000,0.000000) [1.000000|3.000000] "" Vector__XXX
 SG_ DR_Drehwinkelsensortausch_VR  : 74|2@1+ (1.000000,0.000000) [1.000000|3.000000] "" Vector__XXX
 SG_ DR_Drehwinkelsensortausch_HL  : 76|2@1+ (1.000000,0.000000) [1.000000|3.000000] "" Vector__XXX
 SG_ DR_Drehwinkelsensortausch_HR  : 78|2@1+ (1.000000,0.000000) [1.000000|3.000000] "" Vector__XXX
 SG_ DR_Drehwinkel_VL  : 80|12@1+ (0.088000,0.000000) [0.000000|359.920000] "" Vector__XXX
 SG_ DR_Drehwinkel_VR  : 92|12@1+ (0.088000,0.000000) [0.000000|359.920000] "" Vector__XXX
 SG_ DR_Drehwinkel_HL  : 104|12@1+ (0.088000,0.000000) [0.000000|359.920000] "" Vector__XXX
 SG_ DR_Drehwinkel_HR  : 116|12@1+ (0.088000,0.000000) [0.000000|359.920000] "" Vector__XXX

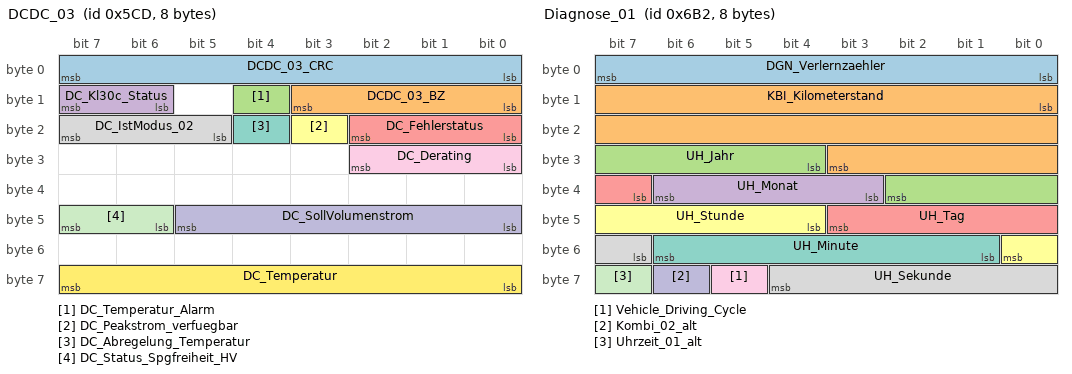
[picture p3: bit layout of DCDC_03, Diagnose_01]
BO_ 1485 DCDC_03: 8 ICAS1_Gateway
 SG_ DCDC_03_CRC  : 0|8@1+ (1.000000,0.000000) [0.000000|255.000000] "" Motor_BEV
 SG_ DCDC_03_BZ  : 8|4@1+ (1.000000,0.000000) [0.000000|15.000000] "" Motor_BEV
 SG_ DC_Temperatur_Alarm  : 12|1@1+ (1.000000,0.000000) [0.000000|1.000000] "" Vector__XXX
 SG_ DC_Kl30c_Status  : 14|2@1+ (1.000000,0.000000) [0.000000|3.000000] "" Motor_BEV
 SG_ DC_Fehlerstatus  : 16|3@1+ (1.000000,0.000000) [0.000000|7.000000] "" Vector__XXX
 SG_ DC_Peakstrom_verfuegbar  : 19|1@1+ (1.000000,0.000000) [0.000000|1.000000] "" Vector__XXX
 SG_ DC_Abregelung_Temperatur  : 20|1@1+ (1.000000,0.000000) [0.000000|1.000000] "" Vector__XXX
 SG_ DC_IstModus_02  : 21|3@1+ (1.000000,0.000000) [0.000000|7.000000] "" Vector__XXX
 SG_ DC_Derating  : 24|3@1+ (1.000000,0.000000) [0.000000|7.000000] "" Vector__XXX
 SG_ DC_SollVolumenstrom  : 40|6@1+ (0.500000,0.000000) [0.000000|30.500000] "Unit_LiterPerMinut" Motor_BEV
 SG_ DC_Status_Spgfreiheit_HV  : 46|2@1+ (1.000000,0.000000) [0.000000|3.000000] "" Vector__XXX
 SG_ DC_Temperatur  : 56|8@1+ (1.000000,-40.000000) [-40.000000|213.000000] "Unit_DegreCelsi" Motor_BEV

BO_ 247 DCDC_04: 8 ICAS1_Gateway
 SG_ DCDC_04_CRC  : 0|8@1+ (1.000000,0.000000) [0.000000|255.000000] "" Vector__XXX
 SG_ DCDC_04_BZ  : 8|4@1+ (1.000000,0.000000) [0.000000|15.000000] "" Vector__XXX
 SG_ DC_Vorladung_Status  : 34|1@1+ (1.000000,0.000000) [0.000000|1.000000] "" Motor_BEV
 SG_ DC_Fehler_extern  : 35|1@1+ (1.000000,0.000000) [0.000000|1.000000] "" Motor_BEV
 SG_ DC_Fehler_intern  : 36|1@1+ (1.000000,0.000000) [0.000000|1.000000] "" Motor_BEV
 SG_ DC_Status_Spgfreiheit  : 37|2@1+ (1.000000,0.000000) [0.000000|3.000000] "" Motor_BEV
 SG_ DC_Status_EoHVL  : 39|2@1+ (1.000000,0.000000) [0.000000|3.000000] "" Motor_BEV
 SG_ DC_IstModus_02  : 41|3@1+ (1.000000,0.000000) [0.000000|7.000000] "" Motor_BEV
 SG_ DC_IstStrom_HV  : 44|10@1+ (0.100000,-51.100000) [-51.100000|51.000000] "Unit_Amper" Motor_BEV
 SG_ DC_IstLeistung_HV  : 54|10@1+ (10.000000,-4000.000000) [-4000.000000|6210.000000] "Unit_Watt" Motor_BEV

BO_ 2617027088 DEV_Airbag_ASM_01: 8 Airbag
 SG_ DEV_Airbag_ASM_01_Data  : 0|64@1+ (1.000000,0.000000) [0.000000|18446744073709551616.000000] "" Vector__XXX

BO_ 2617027072 DEV_Airbag_Resp_00: 8 Airbag
 SG_ DEV_Airbag_Resp_00_Data  : 0|64@1+ (1.000000,0.000000) [0.000000|18446744073709551616.000000] "" Vector__XXX

BO_ 2617027073 DEV_Airbag_Resp_01: 8 Airbag
 SG_ DEV_Airbag_Resp_01_Data  : 0|64@1+ (1.000000,0.000000) [0.000000|18446744073709551616.000000] "" Vector__XXX

BO_ 2617027074 DEV_Airbag_Resp_02: 8 Airbag
 SG_ DEV_Airbag_Resp_02_Data  : 0|64@1+ (1.000000,0.000000) [0.000000|18446744073709551616.000000] "" Vector__XXX

BO_ 2617027075 DEV_Airbag_Resp_03: 8 Airbag
 SG_ DEV_Airbag_Resp_03_Data  : 0|64@1+ (1.000000,0.000000) [0.000000|18446744073709551616.000000] "" Vector__XXX

BO_ 2617027076 DEV_Airbag_Resp_04: 8 Airbag
 SG_ DEV_Airbag_Resp_04_Data  : 0|64@1+ (1.000000,0.000000) [0.000000|18446744073709551616.000000] "" Vector__XXX

BO_ 2617027077 DEV_Airbag_Resp_05: 8 Airbag
 SG_ DEV_Airbag_Resp_05_Data  : 0|64@1+ (1.000000,0.000000) [0.000000|18446744073709551616.000000] "" Vector__XXX

BO_ 2617027078 DEV_Airbag_Resp_06: 8 Airbag
 SG_ DEV_Airbag_Resp_06_Data  : 0|64@1+ (1.000000,0.000000) [0.000000|18446744073709551616.000000] "" Vector__XXX

BO_ 2617027079 DEV_Airbag_Resp_07: 8 Airbag
 SG_ DEV_Airbag_Resp_07_Data  : 0|64@1+ (1.000000,0.000000) [0.000000|18446744073709551616.000000] "" Vector__XXX

BO_ 2617027080 DEV_Airbag_Resp_08: 8 Airbag
 SG_ DEV_Airbag_Resp_08_Data  : 0|64@1+ (1.000000,0.000000) [0.000000|18446744073709551616.000000] "" Vector__XXX

BO_ 2617027081 DEV_Airbag_Resp_09: 8 Airbag
 SG_ DEV_Airbag_Resp_09_Data  : 0|64@1+ (1.000000,0.000000) [0.000000|18446744073709551616.000000] "" Vector__XXX

BO_ 2617027082 DEV_Airbag_Resp_10: 8 Airbag
 SG_ DEV_Airbag_Resp_10_Data  : 0|64@1+ (1.000000,0.000000) [0.000000|18446744073709551616.000000] "" Vector__XXX

BO_ 2617027083 DEV_Airbag_Resp_11: 8 Airbag
 SG_ DEV_Airbag_Resp_11_Data  : 0|64@1+ (1.000000,0.000000) [0.000000|18446744073709551616.000000] "" Vector__XXX

BO_ 2617154048 DEV_Waehlhebel_Resp_00: 8 Schaltbetaetigung
 SG_ DEV_Waehlhebel_Resp_00_Data  : 0|64@1+ (1.000000,0.000000) [0.000000|18446744073709551616.000000] "" Vector__XXX

BO_ 2617154049 DEV_Waehlhebel_Resp_01: 8 Schaltbetaetigung
 SG_ DEV_Waehlhebel_Resp_01_Data  : 0|64@1+ (1.000000,0.000000) [0.000000|18446744073709551616.000000] "" Vector__XXX

BO_ 2617154050 DEV_Waehlhebel_Resp_02: 8 Schaltbetaetigung
 SG_ DEV_Waehlhebel_Resp_02_Data  : 0|64@1+ (1.000000,0.000000) [0.000000|18446744073709551616.000000] "" Vector__XXX

BO_ 2617154051 DEV_Waehlhebel_Resp_03: 8 Schaltbetaetigung
 SG_ DEV_Waehlhebel_Resp_03_Data  : 0|64@1+ (1.000000,0.000000) [0.000000|18446744073709551616.000000] "" Vector__XXX

BO_ 2617154052 DEV_Waehlhebel_Resp_04: 8 Schaltbetaetigung
 SG_ DEV_Waehlhebel_Resp_04_Data  : 0|64@1+ (1.000000,0.000000) [0.000000|18446744073709551616.000000] "" Vector__XXX

BO_ 2617154053 DEV_Waehlhebel_Resp_05: 8 Schaltbetaetigung
 SG_ DEV_Waehlhebel_Resp_05_Data  : 0|64@1+ (1.000000,0.000000) [0.000000|18446744073709551616.000000] "" Vector__XXX

BO_ 2549876269 Diag_Waehlhebel_Req: 8 Motor_BEV
 SG_ Diag_Waehlhebel_Req_Data  : 0|64@1+ (1.000000,0.000000) [0.000000|18446744073709551616.000000] "" Schaltbetaetigung

BO_ 2550007341 Diag_Waehlhebel_Resp: 8 Schaltbetaetigung
 SG_ Diag_Waehlhebel_Resp_Data  : 0|64@1+ (1.000000,0.000000) [0.000000|18446744073709551616.000000] "" Motor_BEV

BO_ 1714 Diagnose_01: 8 ICAS1_Gateway
 SG_ DGN_Verlernzaehler  : 0|8@1+ (1.000000,0.000000) [0.000000|254.000000] "" Airbag LE1 LE2 Motor_BEV
 SG_ KBI_Kilometerstand  : 8|20@1+ (1.000000,0.000000) [0.000000|1048573.000000] "Unit_KiloMeter" Airbag LE1 LE2 Motor_BEV
 SG_ UH_Jahr  : 28|7@1+ (1.000000,2000.000000) [2000.000000|2127.000000] "Unit_Year" Airbag LE1 LE2 Motor_BEV
 SG_ UH_Monat  : 35|4@1+ (1.000000,0.000000) [1.000000|12.000000] "Unit_Month" Airbag LE1 LE2 Motor_BEV
 SG_ UH_Tag  : 39|5@1+ (1.000000,0.000000) [1.000000|31.000000] "Unit_Day" Airbag LE1 LE2 Motor_BEV
 SG_ UH_Stunde  : 44|5@1+ (1.000000,0.000000) [0.000000|23.000000] "Unit_Hours" Airbag LE1 LE2 Motor_BEV
 SG_ UH_Minute  : 49|6@1+ (1.000000,0.000000) [0.000000|59.000000] "Unit_Minut" Airbag LE1 LE2 Motor_BEV
 SG_ UH_Sekunde  : 55|6@1+ (1.000000,0.000000) [0.000000|59.000000] "Unit_Secon" Airbag LE1 LE2 Motor_BEV
 SG_ Vehicle_Driving_Cycle  : 61|1@1+ (1.000000,0.000000) [0.000000|1.000000] "" Airbag
 SG_ Kombi_02_alt  : 62|1@1+ (1.000000,0.000000) [0.000000|1.000000] "" Vector__XXX
 SG_ Uhrzeit_01_alt  : 63|1@1+ (1.000000,0.000000) [0.000000|1.000000] "" Vector__XXX

BO_ 851 DiETa_01: 8 ICAS1_Gateway
 SG_ DiETas_01_CRC  : 0|8@1+ (1.000000,0.000000) [0.000000|255.000000] "" Airbag
 SG_ DiETas_01_BZ  : 8|4@1+ (1.000000,0.000000) [0.000000|15.000000] "" Airbag
 SG_ DiETa_Reserve_Byte2_4  : 12|1@1+ (1.000000,0.000000) [0.000000|1.000000] "" Vector__XXX
 SG_ DiETa_Status  : 13|2@1+ (1.000000,0.000000) [0.000000|3.000000] "" Airbag
 SG_ DiETa_ResponseError  : 15|1@1+ (1.000000,0.000000) [0.000000|1.000000] "" Vector__XXX
 SG_ DiETa_Car  : 16|2@1+ (1.000000,0.000000) [0.000000|3.000000] "" Vector__XXX
 SG_ DiETa_Klima  : 18|2@1+ (1.000000,0.000000) [0.000000|3.000000] "" Vector__XXX
 SG_ DiETa_Mode  : 20|2@1+ (1.000000,0.000000) [0.000000|3.000000] "" Vector__XXX
 SG_ DiETa_Parken  : 22|2@1+ (1.000000,0.000000) [0.000000|3.000000] "" Vector__XXX
 SG_ DiETa_FSH_Taste  : 24|2@1+ (1.000000,0.000000) [0.000000|3.000000] "" Vector__XXX
 SG_ DiETa_HSH_Taste  : 26|2@1+ (1.000000,0.000000) [0.000000|3.000000] "" Vector__XXX
 SG_ DiETa_Warnblink_Taste  : 28|2@1+ (1.000000,0.000000) [0.000000|3.000000] "" Vector__XXX
 SG_ DiETa_FAS_Stufe  : 30|2@1+ (1.000000,0.000000) [0.000000|3.000000] "" Vector__XXX
 SG_ DiETa_PAO_ON_Status  : 32|2@1+ (1.000000,0.000000) [0.000000|3.000000] "" Airbag
 SG_ DiETa_PAO_OFF_Status  : 34|2@1+ (1.000000,0.000000) [0.000000|3.000000] "" Airbag
 SG_ DiETa_Defrost_Taste  : 36|2@1+ (1.000000,0.000000) [0.000000|3.000000] "" Vector__XXX
 SG_ DiETa_Reserve_Byte5_6  : 38|2@1+ (1.000000,0.000000) [0.000000|3.000000] "" Vector__XXX
 SG_ DiETa_Lock_Unlock_Taste  : 40|3@1+ (1.000000,0.000000) [0.000000|7.000000] "" Vector__XXX
 SG_ DiETa_Mode_roh  : 43|1@1+ (1.000000,0.000000) [0.000000|1.000000] "" Vector__XXX
 SG_ DiETa_Reserve_Byte6_3  : 44|4@1+ (1.000000,0.000000) [0.000000|15.000000] "" Vector__XXX
 SG_ DiETa_Reserve_Byte7  : 48|8@1+ (1.000000,0.000000) [0.000000|255.000000] "" Vector__XXX
 SG_ DiETa_Reserve_Byte8  : 56|8@1+ (1.000000,0.000000) [0.000000|255.000000] "" Vector__XXX

BO_ 1520 Dimmung_01: 8 ICAS1_Gateway
 SG_ DI_KL_58xd  : 0|8@1+ (1.000000,0.000000) [0.000000|253.000000] "" Airbag Schaltbetaetigung
 SG_ DI_KL_58xs  : 8|7@1+ (1.000000,0.000000) [0.000000|100.000000] "Unit_PerCent" Airbag
 SG_ DI_Display_Nachtdesign  : 15|1@1+ (1.000000,0.000000) [0.000000|1.000000] "" Vector__XXX
 SG_ DI_KL_58xt  : 16|7@1+ (1.000000,0.000000) [0.000000|100.000000] "Unit_PerCent" Airbag Schaltbetaetigung
 SG_ DI_Fotosensor  : 24|16@1+ (1.000000,0.000000) [0.000000|65535.000000] "" Vector__XXX
 SG_ BCM1_Stellgroesse_Kl_58s  : 40|7@1+ (1.000000,0.000000) [0.000000|100.000000] "" Vector__XXX

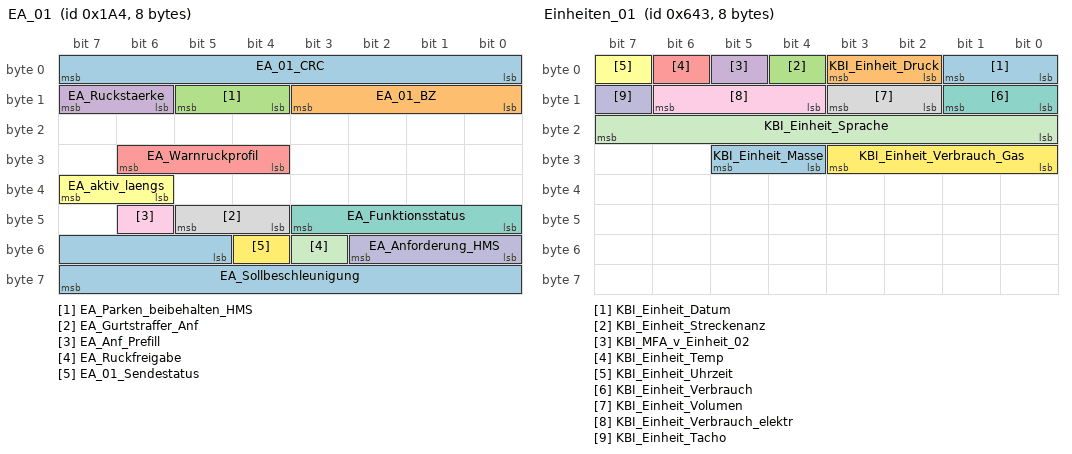
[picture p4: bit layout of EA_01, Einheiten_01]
BO_ 420 EA_01: 8 ICAS1_Gateway
 SG_ EA_01_CRC  : 0|8@1+ (1.000000,0.000000) [0.000000|255.000000] "" Motor_BEV
 SG_ EA_01_BZ  : 8|4@1+ (1.000000,0.000000) [0.000000|15.000000] "" Motor_BEV
 SG_ EA_Parken_beibehalten_HMS  : 12|2@1+ (1.000000,0.000000) [0.000000|3.000000] "" Vector__XXX
 SG_ EA_Ruckstaerke  : 14|2@1+ (1.000000,0.000000) [0.000000|3.000000] "" Vector__XXX
 SG_ EA_Warnruckprofil  : 28|3@1+ (1.000000,0.000000) [0.000000|7.000000] "" Vector__XXX
 SG_ EA_aktiv_laengs  : 38|2@1+ (1.000000,0.000000) [0.000000|3.000000] "" Motor_BEV
 SG_ EA_Funktionsstatus  : 40|4@1+ (1.000000,0.000000) [0.000000|15.000000] "" Motor_BEV
 SG_ EA_Gurtstraffer_Anf  : 44|2@1+ (1.000000,0.000000) [0.000000|3.000000] "" Airbag
 SG_ EA_Anf_Prefill  : 46|1@1+ (1.000000,0.000000) [0.000000|1.000000] "" Vector__XXX
 SG_ EA_Anforderung_HMS  : 48|3@1+ (1.000000,0.000000) [0.000000|7.000000] "" Vector__XXX
 SG_ EA_Ruckfreigabe  : 51|1@1+ (1.000000,0.000000) [0.000000|1.000000] "" Vector__XXX
 SG_ EA_01_Sendestatus  : 52|1@1+ (1.000000,0.000000) [0.000000|1.000000] "" Vector__XXX
 SG_ EA_Sollbeschleunigung  : 53|11@1+ (0.005000,-7.220000) [-7.220000|3.005000] "Unit_MeterPerSeconSquar" Motor_BEV

BO_ 374 EBKV_03: 8 ICAS1_Gateway
 SG_ EBKV_03_CRC  : 0|8@1+ (1.000000,0.000000) [0.000000|255.000000] "" Vector__XXX
 SG_ EBKV_03_BZ  : 8|4@1+ (1.000000,0.000000) [0.000000|15.000000] "" Vector__XXX
 SG_ EBKV_Activate_Fallback_ESP  : 12|1@1+ (1.000000,0.000000) [0.000000|1.000000] "" Vector__XXX
 SG_ EBKV_Restdruckabsenkung  : 13|3@1+ (1.000000,0.000000) [0.000000|7.000000] "" Vector__XXX
 SG_ EBKV_Status_02  : 16|4@1+ (1.000000,0.000000) [0.000000|15.000000] "" Vector__XXX
 SG_ EBKV_Diagnose  : 20|1@1+ (1.000000,0.000000) [0.000000|1.000000] "" Vector__XXX
 SG_ EBKV_Fahrer_bremst  : 21|1@1+ (1.000000,0.000000) [0.000000|1.000000] "" Motor_BEV
 SG_ EBKV_QBit_Fahrer_bremst  : 22|1@1+ (1.000000,0.000000) [0.000000|1.000000] "" Motor_BEV
 SG_ EBKV_Fahrer_bremst_deutlich  : 23|1@1+ (1.000000,0.000000) [0.000000|1.000000] "" Vector__XXX
 SG_ EBKV_OBD_Status  : 24|1@1+ (1.000000,0.000000) [0.000000|1.000000] "" Motor_BEV
 SG_ EBKV_VMM_Sek_Notstopp_Status  : 25|3@1+ (1.000000,0.000000) [0.000000|7.000000] "" Vector__XXX
 SG_ EBKV_Anforderung_HMS  : 28|3@1+ (1.000000,0.000000) [0.000000|7.000000] "" Vector__XXX
 SG_ SBS_Anforderung_GE  : 31|1@1+ (1.000000,0.000000) [0.000000|1.000000] "" Vector__XXX
 SG_ EPB_Status_ext  : 32|3@1+ (1.000000,0.000000) [0.000000|7.000000] "" Motor_BEV
 SG_ EBKV_Bremspedalweg  : 40|8@1+ (0.400000,-0.400000) [0.000000|101.200000] "Unit_PerCent" Motor_BEV
 SG_ EBKV_Kraftblending_Reserve  : 48|8@1+ (0.500000,0.000000) [0.000000|125.000000] "Unit_Bar" Vector__XXX
 SG_ EBKV_Aussteuerdruck  : 56|8@1+ (1.000000,0.000000) [0.000000|250.000000] "Unit_Bar" Vector__XXX

BO_ 1603 Einheiten_01: 8 ICAS1_KommunikationsServer
 SG_ KBI_Einheit_Datum  : 0|2@1+ (1.000000,0.000000) [0.000000|3.000000] "" Vector__XXX
 SG_ KBI_Einheit_Druck  : 2|2@1+ (1.000000,0.000000) [0.000000|3.000000] "" Vector__XXX
 SG_ KBI_Einheit_Streckenanz  : 4|1@1+ (1.000000,0.000000) [0.000000|1.000000] "" Vector__XXX
 SG_ KBI_MFA_v_Einheit_02  : 5|1@1+ (1.000000,0.000000) [0.000000|1.000000] "" Motor_BEV
 SG_ KBI_Einheit_Temp  : 6|1@1+ (1.000000,0.000000) [0.000000|1.000000] "" Vector__XXX
 SG_ KBI_Einheit_Uhrzeit  : 7|1@1+ (1.000000,0.000000) [0.000000|1.000000] "" Vector__XXX
 SG_ KBI_Einheit_Verbrauch  : 8|2@1+ (1.000000,0.000000) [0.000000|3.000000] "" Vector__XXX
 SG_ KBI_Einheit_Volumen  : 10|2@1+ (1.000000,0.000000) [0.000000|3.000000] "" Vector__XXX
 SG_ KBI_Einheit_Verbrauch_elektr  : 12|3@1+ (1.000000,0.000000) [0.000000|7.000000] "" Vector__XXX
 SG_ KBI_Einheit_Tacho  : 15|1@1+ (1.000000,0.000000) [0.000000|1.000000] "" Motor_BEV
 SG_ KBI_Einheit_Sprache  : 16|8@1+ (1.000000,0.000000) [0.000000|255.000000] "" Vector__XXX
 SG_ KBI_Einheit_Verbrauch_Gas  : 24|4@1+ (1.000000,0.000000) [0.000000|15.000000] "" Vector__XXX
 SG_ KBI_Einheit_Masse  : 28|2@1+ (1.000000,0.000000) [0.000000|3.000000] "" Vector__XXX

BU_:  Airbag BAP_Tester ICAS1_Gateway ICAS1_KommunikationsServer LE1 LE2 Motor_BEV Schaltbetaetigung

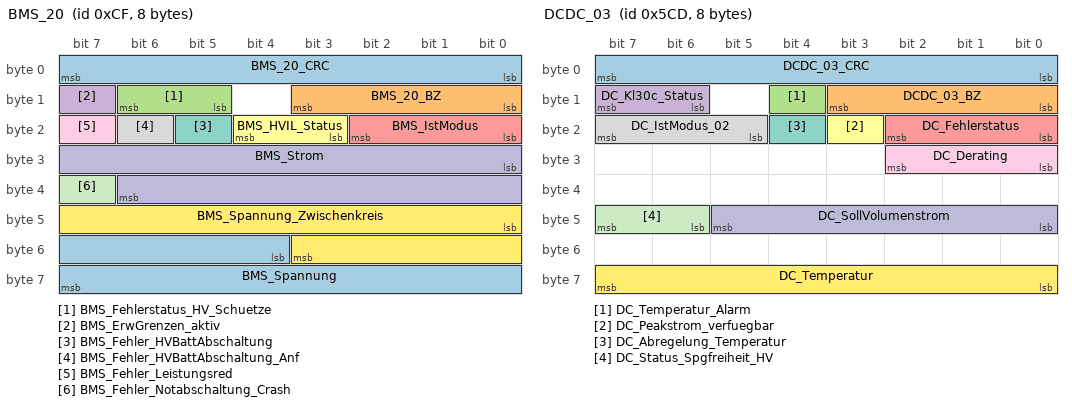
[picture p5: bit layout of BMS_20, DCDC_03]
BO_ 207 BMS_20: 8 ICAS1_Gateway
 SG_ BMS_20_CRC  : 0|8@1+ (1.000000,0.000000) [0.000000|255.000000] "" Motor_BEV
 SG_ BMS_20_BZ  : 8|4@1+ (1.000000,0.000000) [0.000000|15.000000] "" Motor_BEV
 SG_ BMS_Fehlerstatus_HV_Schuetze  : 13|2@1+ (1.000000,0.000000) [0.000000|3.000000] "" Motor_BEV
 SG_ BMS_ErwGrenzen_aktiv  : 15|1@1+ (1.000000,0.000000) [0.000000|1.000000] "" Motor_BEV
 SG_ BMS_IstModus  : 16|3@1+ (1.000000,0.000000) [0.000000|7.000000] "" LE1 LE2 Motor_BEV
 SG_ BMS_HVIL_Status  : 19|2@1+ (1.000000,0.000000) [0.000000|3.000000] "" Motor_BEV
 SG_ BMS_Fehler_HVBattAbschaltung  : 21|1@1+ (1.000000,0.000000) [0.000000|1.000000] "" Motor_BEV
 SG_ BMS_Fehler_HVBattAbschaltung_Anf  : 22|1@1+ (1.000000,0.000000) [0.000000|1.000000] "" Motor_BEV
 SG_ BMS_Fehler_Leistungsred  : 23|1@1+ (1.000000,0.000000) [0.000000|1.000000] "" Motor_BEV
 SG_ BMS_Strom  : 24|15@1+ (0.100000,-1630.000000) [-1630.000000|1630.000000] "Unit_Amper" Motor_BEV
 SG_ BMS_Fehler_Notabschaltung_Crash  : 39|1@1+ (1.000000,0.000000) [0.000000|1.000000] "" Vector__XXX
 SG_ BMS_Spannung_Zwischenkreis  : 40|12@1+ (0.500000,-1000.000000) [-1000.000000|1000.000000] "Unit_Volt" Motor_BEV
 SG_ BMS_Spannung  : 52|12@1+ (0.250000,0.000000) [0.000000|1000.000000] "Unit_Volt" Motor_BEV

BO_ 2463978704 BMS_21: 8 ICAS1_Gateway
 SG_ BMS_Max_Entladestrom  : 12|13@1+ (0.200000,0.000000) [0.000000|1630.000000] "Unit_Amper" Motor_BEV
 SG_ BMS_Max_Ladestrom  : 25|13@1+ (0.200000,0.000000) [0.000000|1630.000000] "Unit_Amper" Motor_BEV
 SG_ BMS_Max_Entladeleistung  : 38|13@1+ (100.000000,0.000000) [0.000000|818000.000000] "Unit_Watt" Motor_BEV
 SG_ BMS_Max_Ladeleistung  : 51|13@1+ (100.000000,0.000000) [0.000000|818000.000000] "Unit_Watt" Motor_BEV

BO_ 2463978705 BMS_22: 8 ICAS1_Gateway
 SG_ BMS_Status_EoHVL_Heizer  : 15|2@1+ (1.000000,0.000000) [0.000000|3.000000] "" Motor_BEV
 SG_ BMS_Ladezustand  : 17|11@1+ (0.050000,0.000000) [0.000000|100.000000] "Unit_PerCent" Motor_BEV
 SG_ BMS_PerfInd_Entladen  : 28|10@1+ (0.200000,0.000000) [0.000000|200.000000] "Unit_PerCent" Motor_BEV
 SG_ BMS_PerfInd_Laden  : 38|10@1+ (0.200000,0.000000) [0.000000|200.000000] "Unit_PerCent" Motor_BEV
 SG_ BMS_Nutzbare_EntladeEnergie  : 48|16@1+ (5.000000,0.000000) [0.000000|327400.000000] "Unit_WattHour" Motor_BEV

BO_ 2589283664 BMS_24: 8 ICAS1_Gateway
 SG_ BMS_Balancing_Aktiv  : 14|2@1+ (1.000000,0.000000) [0.000000|3.000000] "" Vector__XXX
 SG_ BMS_Ladevorgang_aktiv  : 16|1@1+ (1.000000,0.000000) [0.000000|1.000000] "" Vector__XXX
 SG_ BMS_RIso_Ext  : 17|12@1+ (5.000000,0.000000) [0.000000|20465.000000] "Unit_KiloOhm" Motor_BEV
 SG_ BMS_Min_Ladezustand  : 29|11@1+ (0.050000,0.000000) [0.000000|100.000000] "Unit_PerCent" Motor_BEV
 SG_ BMS_Max_Energie  : 40|13@1+ (40.000000,0.000000) [0.000000|327400.000000] "Unit_WattHour" Motor_BEV
 SG_ BMS_Max_Ladezustand  : 53|11@1+ (0.050000,0.000000) [0.000000|100.000000] "Unit_PerCent" Motor_BEV

BO_ 2589283665 BMS_25: 8 ICAS1_Gateway
 SG_ BMS_BattHeizung_VerbautStatus  : 13|1@1+ (1.000000,0.000000) [0.000000|1.000000] "" Motor_BEV
 SG_ BMS_Fehler_NTKreis  : 14|1@1+ (1.000000,0.000000) [0.000000|1.000000] "" Vector__XXX
 SG_ BMS_Temperierung_Anf  : 15|3@1+ (1.000000,0.000000) [0.000000|7.000000] "" Motor_BEV
 SG_ BMS_Status_Ventil1  : 18|3@1+ (1.000000,0.000000) [0.000000|7.000000] "" Motor_BEV
 SG_ BMS_Status_Ventil2  : 21|3@1+ (1.000000,0.000000) [0.000000|7.000000] "" Motor_BEV
 SG_ BMS_Pumpe1_Ansteuerung  : 24|4@1+ (10.000000,0.000000) [0.000000|100.000000] "Unit_PerCent" Motor_BEV
 SG_ BMS_Pumpe2_Ansteuerung  : 28|4@1+ (10.000000,0.000000) [0.000000|100.000000] "Unit_PerCent" Motor_BEV
 SG_ BMS_VorlaufTemperatur  : 32|8@1+ (0.500000,-40.000000) [-40.000000|86.000000] "Unit_DegreCelsi" Motor_BEV
 SG_ BMS_Temperatur  : 40|8@1+ (0.500000,-40.000000) [-40.000000|86.500000] "Unit_DegreCelsi" Motor_BEV
 SG_ BMS_SollVorlauftemperatur  : 48|8@1+ (0.500000,-40.000000) [-40.000000|86.500000] "Unit_DegreCelsi" Motor_BEV
 SG_ BMS_RuecklaufTemperatur  : 56|8@1+ (0.500000,-40.000000) [-40.000000|86.000000] "Unit_DegreCelsi" Motor_BEV

BO_ 2589283760 BMS_26: 8 ICAS1_Gateway
 SG_ BMS_Max_Spannung  : 20|10@1+ (1.000000,0.000000) [0.000000|1000.000000] "Unit_Volt" Motor_BEV
 SG_ BMS_Min_Spannung  : 30|10@1+ (1.000000,0.000000) [0.000000|1000.000000] "Unit_Volt" Motor_BEV
 SG_ BMS_Dauer_Entladeleistung  : 40|12@1+ (200.000000,0.000000) [0.000000|818000.000000] "Unit_Watt" Motor_BEV
 SG_ BMS_Dauer_Ladeleistung  : 52|12@1+ (200.000000,0.000000) [0.000000|818000.000000] "Unit_Watt" Motor_BEV

BO_ 2463978646 Charisma_11: 24 ICAS1_Gateway
 SG_ CHA_Ziel_FahrPr_AGA  : 0|4@1+ (1.000000,0.000000) [0.000000|15.000000] "" Vector__XXX
 SG_ CHA_Ziel_FahrPr_ESP  : 4|4@1+ (1.000000,0.000000) [0.000000|15.000000] "" Motor_BEV
 SG_ CHA_Ziel_FahrPr_Freilauf  : 8|4@1+ (1.000000,0.000000) [0.000000|15.000000] "" Vector__XXX
 SG_ CHA_Fahrer_Umschaltung  : 14|1@1+ (1.000000,0.000000) [0.000000|1.000000] "" Motor_BEV
 SG_ CHA_Fahrer_Umschaltung_BMA  : 15|1@1+ (1.000000,0.000000) [0.000000|1.000000] "" Vector__XXX
 SG_ CHA_Ziel_FahrPr_MO  : 16|4@1+ (1.000000,0.000000) [0.000000|15.000000] "" Motor_BEV
 SG_ CHA_Ziel_FahrPr_GE  : 20|4@1+ (1.000000,0.000000) [0.000000|15.000000] "" Vector__XXX
 SG_ CHA_Ziel_FahrPr_ALR  : 24|4@1+ (1.000000,0.000000) [0.000000|15.000000] "" Motor_BEV
 SG_ CHA_Ziel_FahrPr_MO_BZS  : 28|4@1+ (1.000000,0.000000) [0.000000|15.000000] "" Vector__XXX
 SG_ CHA_Ziel_FahrPr_DR  : 32|4@1+ (1.000000,0.000000) [0.000000|15.000000] "" Vector__XXX
 SG_ CHA_Ziel_FahrPr_VAQ  : 36|4@1+ (1.000000,0.000000) [0.000000|15.000000] "" Vector__XXX
 SG_ CHA_Ziel_FahrPr_AFS  : 40|4@1+ (1.000000,0.000000) [0.000000|15.000000] "" Vector__XXX
 SG_ CHA_Ziel_FahrPr_PreCrash  : 44|4@1+ (1.000000,0.000000) [0.000000|15.000000] "" Airbag
 SG_ CHA_Ziel_FahrPr_EPS  : 48|4@1+ (1.000000,0.000000) [0.000000|15.000000] "" Vector__XXX
 SG_ CHA_Ziel_FahrPr_ACC  : 52|4@1+ (1.000000,0.000000) [0.000000|15.000000] "" Vector__XXX
 SG_ CHA_Ziel_FahrPr_SAK  : 56|4@1+ (1.000000,0.000000) [0.000000|15.000000] "" Vector__XXX
 SG_ CHA_Ziel_FahrPr_MO_StSt  : 60|4@1+ (1.000000,0.000000) [0.000000|15.000000] "" Vector__XXX
 SG_ CHA_Ziel_FahrPr_EBKV  : 64|4@1+ (1.000000,0.000000) [0.000000|15.000000] "" Vector__XXX
 SG_ CHA_Ziel_FahrPr_IL  : 68|4@1+ (1.000000,0.000000) [0.000000|15.000000] "" Vector__XXX
 SG_ CHA_Current_Mode  : 72|4@1+ (1.000000,0.000000) [0.000000|15.000000] "" Vector__XXX
 SG_ CHA_Ziel_FahrPr_QS  : 80|4@1+ (1.000000,0.000000) [0.000000|15.000000] "" Vector__XXX
 SG_ CHA_Ziel_FahrPr_SCU  : 84|4@1+ (1.000000,0.000000) [0.000000|15.000000] "" Vector__XXX
 SG_ CHA_Ziel_FahrPr_HAL  : 88|4@1+ (1.000000,0.000000) [0.000000|15.000000] "" Vector__XXX
 SG_ CHA_Ziel_FahrPr_NR  : 92|4@1+ (1.000000,0.000000) [0.000000|15.000000] "" Vector__XXX
 SG_ CHA_Ziel_FahrPr_AV  : 96|4@1+ (1.000000,0.000000) [0.000000|15.000000] "" Vector__XXX
 SG_ CHA_Ziel_FahrPr_MXB  : 100|4@1+ (1.000000,0.000000) [0.000000|15.000000] "" Vector__XXX
 SG_ CHA_Ziel_FahrPr_AFR  : 104|4@1+ (1.000000,0.000000) [0.000000|15.000000] "" Vector__XXX
 SG_ CHA_Ziel_FahrPr_HDC  : 108|4@1+ (1.000000,0.000000) [0.000000|15.000000] "" Vector__XXX
 SG_ CHA_Ziel_FahrPr_EAR  : 112|4@1+ (1.000000,0.000000) [0.000000|15.000000] "" Vector__XXX
 SG_ CHA_Ziel_FahrPr_AEB  : 116|4@1+ (1.000000,0.000000) [0.000000|15.000000] "" Vector__XXX
 SG_ CHA_Ziel_FahrPr_FCWO  : 120|4@1+ (1.000000,0.000000) [0.000000|15.000000] "" Vector__XXX
 SG_ CHA_Ziel_FahrPr_FCWP  : 124|4@1+ (1.000000,0.000000) [0.000000|15.000000] "" Vector__XXX
 SG_ CHA_Ziel_FahrPr_ToS_laengs  : 144|4@1+ (1.000000,0.000000) [0.000000|15.000000] "" Vector__XXX
 SG_ CHA_Ziel_FahrPr_ToS_quer  : 148|4@1+ (1.000000,0.000000) [0.000000|15.000000] "" Vector__XXX
 SG_ CHA_Ziel_FahrPr_mFDR  : 152|4@1+ (1.000000,0.000000) [0.000000|15.000000] "" Vector__XXX
 SG_ CHA_Ziel_FahrPr_Reku_ZwGas  : 156|4@1+ (1.000000,0.000000) [0.000000|15.000000] "" Vector__XXX
 SG_ CHA_Ziel_FahrPr_MO_Freilauf  : 160|4@1+ (1.000000,0.000000) [0.000000|15.000000] "" Vector__XXX
 SG_ CHA_Ziel_FahrPr_BMS  : 164|4@1+ (1.000000,0.000000) [0.000000|15.000000] "" Vector__XXX
 SG_ CHA_Current_Mode_BMA  : 168|4@1+ (1.000000,0.000000) [0.000000|15.000000] "" Vector__XXX
 SG_ CHA_Ziel_FahrPr_PDC  : 172|4@1+ (1.000000,0.000000) [0.000000|15.000000] "" Vector__XXX
 SG_ CHA_Ziel_FahrPr_HHC  : 176|4@1+ (1.000000,0.000000) [0.000000|15.000000] "" Vector__XXX
 SG_ CHA_Ziel_FahrPr_EDS  : 180|4@1+ (1.000000,0.000000) [0.000000|15.000000] "" Vector__XXX
 SG_ CHA_Ziel_FahrPr_PACC  : 184|4@1+ (1.000000,0.000000) [0.000000|15.000000] "" Vector__XXX
 SG_ CHA_Ziel_FahrPr_AGK  : 188|4@1+ (1.000000,0.000000) [0.000000|15.000000] "" Vector__XXX

BO_ 514 Daempfer_03: 32 ICAS1_Gateway
 SG_ DR_Aufbaubeschleunigung_HR  : 12|10@1+ (0.032700,-15.696000) [-15.696000|15.696000] "Unit_MeterPerSeconSquar" Motor_BEV
 SG_ DR_Aufbaubeschleunigung_VR  : 22|10@1+ (0.032700,-15.696000) [-15.696000|15.696000] "Unit_MeterPerSeconSquar" Motor_BEV
 SG_ DR_Aufbaubeschleunigung_VL  : 32|10@1+ (0.032700,-15.696000) [-15.696000|15.696000] "Unit_MeterPerSeconSquar" Motor_BEV
 SG_ DR_Aufbaubeschleunigung_HL  : 42|10@1+ (0.032700,-15.696000) [-15.696000|15.696000] "Unit_MeterPerSeconSquar" Motor_BEV
 SG_ DR_Funktionsstatus  : 52|2@1+ (1.000000,0.000000) [0.000000|3.000000] "" Vector__XXX
 SG_ DR_Drehwinkelsensortausch_VL  : 72|2@1+ (1.000000,0.000000) [1.000000|3.000000] "" Vector__XXX
 SG_ DR_Drehwinkelsensortausch_VR  : 74|2@1+ (1.000000,0.000000) [1.000000|3.000000] "" Vector__XXX
 SG_ DR_Drehwinkelsensortausch_HL  : 76|2@1+ (1.000000,0.000000) [1.000000|3.000000] "" Vector__XXX
 SG_ DR_Drehwinkelsensortausch_HR  : 78|2@1+ (1.000000,0.000000) [1.000000|3.000000] "" Vector__XXX
 SG_ DR_Drehwinkel_VL  : 80|12@1+ (0.088000,0.000000) [0.000000|359.920000] "" Vector__XXX
 SG_ DR_Drehwinkel_VR  : 92|12@1+ (0.088000,0.000000) [0.000000|359.920000] "" Vector__XXX
 SG_ DR_Drehwinkel_HL  : 104|12@1+ (0.088000,0.000000) [0.000000|359.920000] "" Vector__XXX
 SG_ DR_Drehwinkel_HR  : 116|12@1+ (0.088000,0.000000) [0.000000|359.920000] "" Vector__XXX

BO_ 1485 DCDC_03: 8 ICAS1_Gateway
 SG_ DCDC_03_CRC  : 0|8@1+ (1.000000,0.000000) [0.000000|255.000000] "" Motor_BEV
 SG_ DCDC_03_BZ  : 8|4@1+ (1.000000,0.000000) [0.000000|15.000000] "" Motor_BEV
 SG_ DC_Temperatur_Alarm  : 12|1@1+ (1.000000,0.000000) [0.000000|1.000000] "" Vector__XXX
 SG_ DC_Kl30c_Status  : 14|2@1+ (1.000000,0.000000) [0.000000|3.000000] "" Motor_BEV
 SG_ DC_Fehlerstatus  : 16|3@1+ (1.000000,0.000000) [0.000000|7.000000] "" Vector__XXX
 SG_ DC_Peakstrom_verfuegbar  : 19|1@1+ (1.000000,0.000000) [0.000000|1.000000] "" Vector__XXX
 SG_ DC_Abregelung_Temperatur  : 20|1@1+ (1.000000,0.000000) [0.000000|1.000000] "" Vector__XXX
 SG_ DC_IstModus_02  : 21|3@1+ (1.000000,0.000000) [0.000000|7.000000] "" Vector__XXX
 SG_ DC_Derating  : 24|3@1+ (1.000000,0.000000) [0.000000|7.000000] "" Vector__XXX
 SG_ DC_SollVolumenstrom  : 40|6@1+ (0.500000,0.000000) [0.000000|30.500000] "Unit_LiterPerMinut" Motor_BEV
 SG_ DC_Status_Spgfreiheit_HV  : 46|2@1+ (1.000000,0.000000) [0.000000|3.000000] "" Vector__XXX
 SG_ DC_Temperatur  : 56|8@1+ (1.000000,-40.000000) [-40.000000|213.000000] "Unit_DegreCelsi" Motor_BEV

BO_ 247 DCDC_04: 8 ICAS1_Gateway
 SG_ DCDC_04_CRC  : 0|8@1+ (1.000000,0.000000) [0.000000|255.000000] "" Vector__XXX
 SG_ DCDC_04_BZ  : 8|4@1+ (1.000000,0.000000) [0.000000|15.000000] "" Vector__XXX
 SG_ DC_Vorladung_Status  : 34|1@1+ (1.000000,0.000000) [0.000000|1.000000] "" Motor_BEV
 SG_ DC_Fehler_extern  : 35|1@1+ (1.000000,0.000000) [0.000000|1.000000] "" Motor_BEV
 SG_ DC_Fehler_intern  : 36|1@1+ (1.000000,0.000000) [0.000000|1.000000] "" Motor_BEV
 SG_ DC_Status_Spgfreiheit  : 37|2@1+ (1.000000,0.000000) [0.000000|3.000000] "" Motor_BEV
 SG_ DC_Status_EoHVL  : 39|2@1+ (1.000000,0.000000) [0.000000|3.000000] "" Motor_BEV
 SG_ DC_IstModus_02  : 41|3@1+ (1.000000,0.000000) [0.000000|7.000000] "" Motor_BEV
 SG_ DC_IstStrom_HV  : 44|10@1+ (0.100000,-51.100000) [-51.100000|51.000000] "Unit_Amper" Motor_BEV
 SG_ DC_IstLeistung_HV  : 54|10@1+ (10.000000,-4000.000000) [-4000.000000|6210.000000] "Unit_Watt" Motor_BEV

BO_ 2617027088 DEV_Airbag_ASM_01: 8 Airbag
 SG_ DEV_Airbag_ASM_01_Data  : 0|64@1+ (1.000000,0.000000) [0.000000|18446744073709551616.000000] "" Vector__XXX

BO_ 2617027072 DEV_Airbag_Resp_00: 8 Airbag
 SG_ DEV_Airbag_Resp_00_Data  : 0|64@1+ (1.000000,0.000000) [0.000000|18446744073709551616.000000] "" Vector__XXX

BO_ 2617027073 DEV_Airbag_Resp_01: 8 Airbag
 SG_ DEV_Airbag_Resp_01_Data  : 0|64@1+ (1.000000,0.000000) [0.000000|18446744073709551616.000000] "" Vector__XXX

BO_ 2617027074 DEV_Airbag_Resp_02: 8 Airbag
 SG_ DEV_Airbag_Resp_02_Data  : 0|64@1+ (1.000000,0.000000) [0.000000|18446744073709551616.000000] "" Vector__XXX

BO_ 2617027075 DEV_Airbag_Resp_03: 8 Airbag
 SG_ DEV_Airbag_Resp_03_Data  : 0|64@1+ (1.000000,0.000000) [0.000000|18446744073709551616.000000] "" Vector__XXX

BO_ 2617027076 DEV_Airbag_Resp_04: 8 Airbag
 SG_ DEV_Airbag_Resp_04_Data  : 0|64@1+ (1.000000,0.000000) [0.000000|18446744073709551616.000000] "" Vector__XXX

BO_ 2617027077 DEV_Airbag_Resp_05: 8 Airbag
 SG_ DEV_Airbag_Resp_05_Data  : 0|64@1+ (1.000000,0.000000) [0.000000|18446744073709551616.000000] "" Vector__XXX

BO_ 2617027078 DEV_Airbag_Resp_06: 8 Airbag
 SG_ DEV_Airbag_Resp_06_Data  : 0|64@1+ (1.000000,0.000000) [0.000000|18446744073709551616.000000] "" Vector__XXX

BO_ 2617027079 DEV_Airbag_Resp_07: 8 Airbag
 SG_ DEV_Airbag_Resp_07_Data  : 0|64@1+ (1.000000,0.000000) [0.000000|18446744073709551616.000000] "" Vector__XXX

BO_ 2617027080 DEV_Airbag_Resp_08: 8 Airbag
 SG_ DEV_Airbag_Resp_08_Data  : 0|64@1+ (1.000000,0.000000) [0.000000|18446744073709551616.000000] "" Vector__XXX

BO_ 2617027081 DEV_Airbag_Resp_09: 8 Airbag
 SG_ DEV_Airbag_Resp_09_Data  : 0|64@1+ (1.000000,0.000000) [0.000000|18446744073709551616.000000] "" Vector__XXX

BO_ 2617027082 DEV_Airbag_Resp_10: 8 Airbag
 SG_ DEV_Airbag_Resp_10_Data  : 0|64@1+ (1.000000,0.000000) [0.000000|18446744073709551616.000000] "" Vector__XXX

BO_ 2617027083 DEV_Airbag_Resp_11: 8 Airbag
 SG_ DEV_Airbag_Resp_11_Data  : 0|64@1+ (1.000000,0.000000) [0.000000|18446744073709551616.000000] "" Vector__XXX

BO_ 2617154048 DEV_Waehlhebel_Resp_00: 8 Schaltbetaetigung
 SG_ DEV_Waehlhebel_Resp_00_Data  : 0|64@1+ (1.000000,0.000000) [0.000000|18446744073709551616.000000] "" Vector__XXX

BO_ 2617154049 DEV_Waehlhebel_Resp_01: 8 Schaltbetaetigung
 SG_ DEV_Waehlhebel_Resp_01_Data  : 0|64@1+ (1.000000,0.000000) [0.000000|18446744073709551616.000000] "" Vector__XXX

BO_ 2617154050 DEV_Waehlhebel_Resp_02: 8 Schaltbetaetigung
 SG_ DEV_Waehlhebel_Resp_02_Data  : 0|64@1+ (1.000000,0.000000) [0.000000|18446744073709551616.000000] "" Vector__XXX

BO_ 2617154051 DEV_Waehlhebel_Resp_03: 8 Schaltbetaetigung
 SG_ DEV_Waehlhebel_Resp_03_Data  : 0|64@1+ (1.000000,0.000000) [0.000000|18446744073709551616.000000] "" Vector__XXX

BO_ 2617154052 DEV_Waehlhebel_Resp_04: 8 Schaltbetaetigung
 SG_ DEV_Waehlhebel_Resp_04_Data  : 0|64@1+ (1.000000,0.000000) [0.000000|18446744073709551616.000000] "" Vector__XXX

BO_ 2617154053 DEV_Waehlhebel_Resp_05: 8 Schaltbetaetigung
 SG_ DEV_Waehlhebel_Resp_05_Data  : 0|64@1+ (1.000000,0.000000) [0.000000|18446744073709551616.000000] "" Vector__XXX

BO_ 2549876269 Diag_Waehlhebel_Req: 8 Motor_BEV
 SG_ Diag_Waehlhebel_Req_Data  : 0|64@1+ (1.000000,0.000000) [0.000000|18446744073709551616.000000] "" Schaltbetaetigung

BO_ 2550007341 Diag_Waehlhebel_Resp: 8 Schaltbetaetigung
 SG_ Diag_Waehlhebel_Resp_Data  : 0|64@1+ (1.000000,0.000000) [0.000000|18446744073709551616.000000] "" Motor_BEV

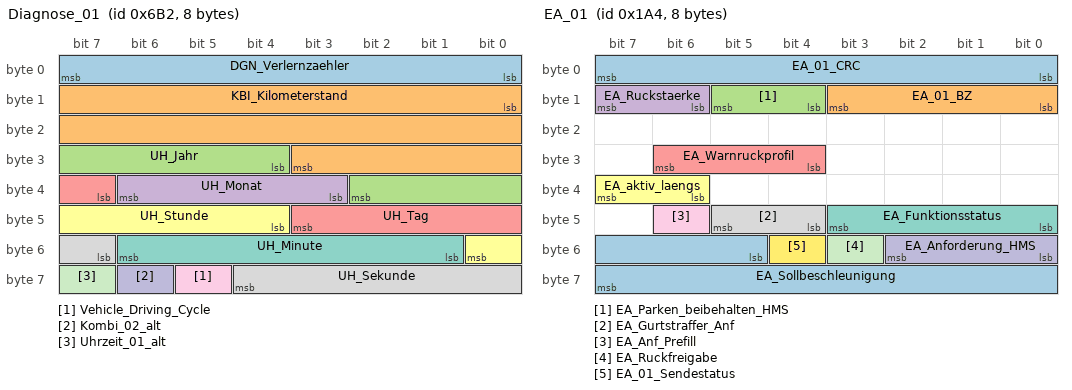
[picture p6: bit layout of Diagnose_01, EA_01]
BO_ 1714 Diagnose_01: 8 ICAS1_Gateway
 SG_ DGN_Verlernzaehler  : 0|8@1+ (1.000000,0.000000) [0.000000|254.000000] "" Airbag LE1 LE2 Motor_BEV
 SG_ KBI_Kilometerstand  : 8|20@1+ (1.000000,0.000000) [0.000000|1048573.000000] "Unit_KiloMeter" Airbag LE1 LE2 Motor_BEV
 SG_ UH_Jahr  : 28|7@1+ (1.000000,2000.000000) [2000.000000|2127.000000] "Unit_Year" Airbag LE1 LE2 Motor_BEV
 SG_ UH_Monat  : 35|4@1+ (1.000000,0.000000) [1.000000|12.000000] "Unit_Month" Airbag LE1 LE2 Motor_BEV
 SG_ UH_Tag  : 39|5@1+ (1.000000,0.000000) [1.000000|31.000000] "Unit_Day" Airbag LE1 LE2 Motor_BEV
 SG_ UH_Stunde  : 44|5@1+ (1.000000,0.000000) [0.000000|23.000000] "Unit_Hours" Airbag LE1 LE2 Motor_BEV
 SG_ UH_Minute  : 49|6@1+ (1.000000,0.000000) [0.000000|59.000000] "Unit_Minut" Airbag LE1 LE2 Motor_BEV
 SG_ UH_Sekunde  : 55|6@1+ (1.000000,0.000000) [0.000000|59.000000] "Unit_Secon" Airbag LE1 LE2 Motor_BEV
 SG_ Vehicle_Driving_Cycle  : 61|1@1+ (1.000000,0.000000) [0.000000|1.000000] "" Airbag
 SG_ Kombi_02_alt  : 62|1@1+ (1.000000,0.000000) [0.000000|1.000000] "" Vector__XXX
 SG_ Uhrzeit_01_alt  : 63|1@1+ (1.000000,0.000000) [0.000000|1.000000] "" Vector__XXX

BO_ 851 DiETa_01: 8 ICAS1_Gateway
 SG_ DiETas_01_CRC  : 0|8@1+ (1.000000,0.000000) [0.000000|255.000000] "" Airbag
 SG_ DiETas_01_BZ  : 8|4@1+ (1.000000,0.000000) [0.000000|15.000000] "" Airbag
 SG_ DiETa_Reserve_Byte2_4  : 12|1@1+ (1.000000,0.000000) [0.000000|1.000000] "" Vector__XXX
 SG_ DiETa_Status  : 13|2@1+ (1.000000,0.000000) [0.000000|3.000000] "" Airbag
 SG_ DiETa_ResponseError  : 15|1@1+ (1.000000,0.000000) [0.000000|1.000000] "" Vector__XXX
 SG_ DiETa_Car  : 16|2@1+ (1.000000,0.000000) [0.000000|3.000000] "" Vector__XXX
 SG_ DiETa_Klima  : 18|2@1+ (1.000000,0.000000) [0.000000|3.000000] "" Vector__XXX
 SG_ DiETa_Mode  : 20|2@1+ (1.000000,0.000000) [0.000000|3.000000] "" Vector__XXX
 SG_ DiETa_Parken  : 22|2@1+ (1.000000,0.000000) [0.000000|3.000000] "" Vector__XXX
 SG_ DiETa_FSH_Taste  : 24|2@1+ (1.000000,0.000000) [0.000000|3.000000] "" Vector__XXX
 SG_ DiETa_HSH_Taste  : 26|2@1+ (1.000000,0.000000) [0.000000|3.000000] "" Vector__XXX
 SG_ DiETa_Warnblink_Taste  : 28|2@1+ (1.000000,0.000000) [0.000000|3.000000] "" Vector__XXX
 SG_ DiETa_FAS_Stufe  : 30|2@1+ (1.000000,0.000000) [0.000000|3.000000] "" Vector__XXX
 SG_ DiETa_PAO_ON_Status  : 32|2@1+ (1.000000,0.000000) [0.000000|3.000000] "" Airbag
 SG_ DiETa_PAO_OFF_Status  : 34|2@1+ (1.000000,0.000000) [0.000000|3.000000] "" Airbag
 SG_ DiETa_Defrost_Taste  : 36|2@1+ (1.000000,0.000000) [0.000000|3.000000] "" Vector__XXX
 SG_ DiETa_Reserve_Byte5_6  : 38|2@1+ (1.000000,0.000000) [0.000000|3.000000] "" Vector__XXX
 SG_ DiETa_Lock_Unlock_Taste  : 40|3@1+ (1.000000,0.000000) [0.000000|7.000000] "" Vector__XXX
 SG_ DiETa_Mode_roh  : 43|1@1+ (1.000000,0.000000) [0.000000|1.000000] "" Vector__XXX
 SG_ DiETa_Reserve_Byte6_3  : 44|4@1+ (1.000000,0.000000) [0.000000|15.000000] "" Vector__XXX
 SG_ DiETa_Reserve_Byte7  : 48|8@1+ (1.000000,0.000000) [0.000000|255.000000] "" Vector__XXX
 SG_ DiETa_Reserve_Byte8  : 56|8@1+ (1.000000,0.000000) [0.000000|255.000000] "" Vector__XXX

BO_ 1520 Dimmung_01: 8 ICAS1_Gateway
 SG_ DI_KL_58xd  : 0|8@1+ (1.000000,0.000000) [0.000000|253.000000] "" Airbag Schaltbetaetigung
 SG_ DI_KL_58xs  : 8|7@1+ (1.000000,0.000000) [0.000000|100.000000] "Unit_PerCent" Airbag
 SG_ DI_Display_Nachtdesign  : 15|1@1+ (1.000000,0.000000) [0.000000|1.000000] "" Vector__XXX
 SG_ DI_KL_58xt  : 16|7@1+ (1.000000,0.000000) [0.000000|100.000000] "Unit_PerCent" Airbag Schaltbetaetigung
 SG_ DI_Fotosensor  : 24|16@1+ (1.000000,0.000000) [0.000000|65535.000000] "" Vector__XXX
 SG_ BCM1_Stellgroesse_Kl_58s  : 40|7@1+ (1.000000,0.000000) [0.000000|100.000000] "" Vector__XXX

BO_ 420 EA_01: 8 ICAS1_Gateway
 SG_ EA_01_CRC  : 0|8@1+ (1.000000,0.000000) [0.000000|255.000000] "" Motor_BEV
 SG_ EA_01_BZ  : 8|4@1+ (1.000000,0.000000) [0.000000|15.000000] "" Motor_BEV
 SG_ EA_Parken_beibehalten_HMS  : 12|2@1+ (1.000000,0.000000) [0.000000|3.000000] "" Vector__XXX
 SG_ EA_Ruckstaerke  : 14|2@1+ (1.000000,0.000000) [0.000000|3.000000] "" Vector__XXX
 SG_ EA_Warnruckprofil  : 28|3@1+ (1.000000,0.000000) [0.000000|7.000000] "" Vector__XXX
 SG_ EA_aktiv_laengs  : 38|2@1+ (1.000000,0.000000) [0.000000|3.000000] "" Motor_BEV
 SG_ EA_Funktionsstatus  : 40|4@1+ (1.000000,0.000000) [0.000000|15.000000] "" Motor_BEV
 SG_ EA_Gurtstraffer_Anf  : 44|2@1+ (1.000000,0.000000) [0.000000|3.000000] "" Airbag
 SG_ EA_Anf_Prefill  : 46|1@1+ (1.000000,0.000000) [0.000000|1.000000] "" Vector__XXX
 SG_ EA_Anforderung_HMS  : 48|3@1+ (1.000000,0.000000) [0.000000|7.000000] "" Vector__XXX
 SG_ EA_Ruckfreigabe  : 51|1@1+ (1.000000,0.000000) [0.000000|1.000000] "" Vector__XXX
 SG_ EA_01_Sendestatus  : 52|1@1+ (1.000000,0.000000) [0.000000|1.000000] "" Vector__XXX
 SG_ EA_Sollbeschleunigung  : 53|11@1+ (0.005000,-7.220000) [-7.220000|3.005000] "Unit_MeterPerSeconSquar" Motor_BEV

BO_ 374 EBKV_03: 8 ICAS1_Gateway
 SG_ EBKV_03_CRC  : 0|8@1+ (1.000000,0.000000) [0.000000|255.000000] "" Vector__XXX
 SG_ EBKV_03_BZ  : 8|4@1+ (1.000000,0.000000) [0.000000|15.000000] "" Vector__XXX
 SG_ EBKV_Activate_Fallback_ESP  : 12|1@1+ (1.000000,0.000000) [0.000000|1.000000] "" Vector__XXX
 SG_ EBKV_Restdruckabsenkung  : 13|3@1+ (1.000000,0.000000) [0.000000|7.000000] "" Vector__XXX
 SG_ EBKV_Status_02  : 16|4@1+ (1.000000,0.000000) [0.000000|15.000000] "" Vector__XXX
 SG_ EBKV_Diagnose  : 20|1@1+ (1.000000,0.000000) [0.000000|1.000000] "" Vector__XXX
 SG_ EBKV_Fahrer_bremst  : 21|1@1+ (1.000000,0.000000) [0.000000|1.000000] "" Motor_BEV
 SG_ EBKV_QBit_Fahrer_bremst  : 22|1@1+ (1.000000,0.000000) [0.000000|1.000000] "" Motor_BEV
 SG_ EBKV_Fahrer_bremst_deutlich  : 23|1@1+ (1.000000,0.000000) [0.000000|1.000000] "" Vector__XXX
 SG_ EBKV_OBD_Status  : 24|1@1+ (1.000000,0.000000) [0.000000|1.000000] "" Motor_BEV
 SG_ EBKV_VMM_Sek_Notstopp_Status  : 25|3@1+ (1.000000,0.000000) [0.000000|7.000000] "" Vector__XXX
 SG_ EBKV_Anforderung_HMS  : 28|3@1+ (1.000000,0.000000) [0.000000|7.000000] "" Vector__XXX
 SG_ SBS_Anforderung_GE  : 31|1@1+ (1.000000,0.000000) [0.000000|1.000000] "" Vector__XXX
 SG_ EPB_Status_ext  : 32|3@1+ (1.000000,0.000000) [0.000000|7.000000] "" Motor_BEV
 SG_ EBKV_Bremspedalweg  : 40|8@1+ (0.400000,-0.400000) [0.000000|101.200000] "Unit_PerCent" Motor_BEV
 SG_ EBKV_Kraftblending_Reserve  : 48|8@1+ (0.500000,0.000000) [0.000000|125.000000] "Unit_Bar" Vector__XXX
 SG_ EBKV_Aussteuerdruck  : 56|8@1+ (1.000000,0.000000) [0.000000|250.000000] "Unit_Bar" Vector__XXX

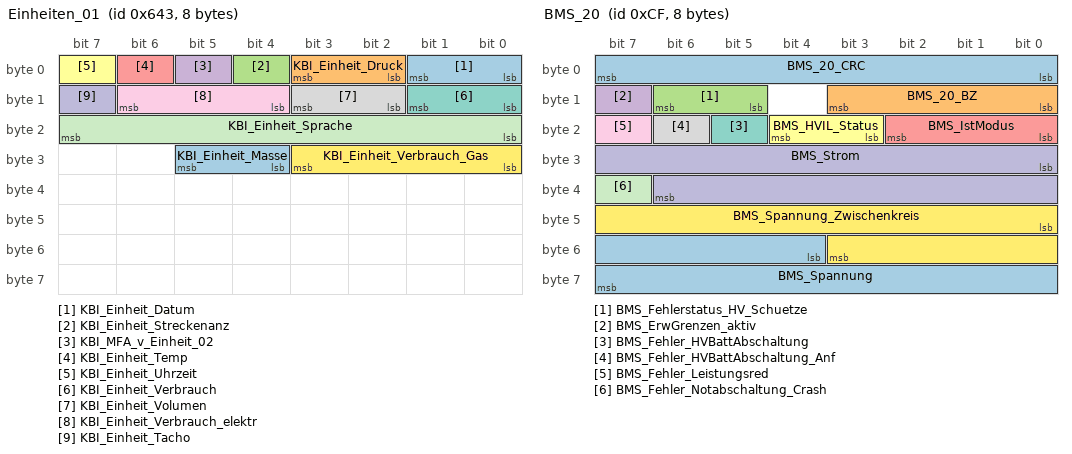
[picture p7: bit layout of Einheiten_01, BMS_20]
BO_ 1603 Einheiten_01: 8 ICAS1_KommunikationsServer
 SG_ KBI_Einheit_Datum  : 0|2@1+ (1.000000,0.000000) [0.000000|3.000000] "" Vector__XXX
 SG_ KBI_Einheit_Druck  : 2|2@1+ (1.000000,0.000000) [0.000000|3.000000] "" Vector__XXX
 SG_ KBI_Einheit_Streckenanz  : 4|1@1+ (1.000000,0.000000) [0.000000|1.000000] "" Vector__XXX
 SG_ KBI_MFA_v_Einheit_02  : 5|1@1+ (1.000000,0.000000) [0.000000|1.000000] "" Motor_BEV
 SG_ KBI_Einheit_Temp  : 6|1@1+ (1.000000,0.000000) [0.000000|1.000000] "" Vector__XXX
 SG_ KBI_Einheit_Uhrzeit  : 7|1@1+ (1.000000,0.000000) [0.000000|1.000000] "" Vector__XXX
 SG_ KBI_Einheit_Verbrauch  : 8|2@1+ (1.000000,0.000000) [0.000000|3.000000] "" Vector__XXX
 SG_ KBI_Einheit_Volumen  : 10|2@1+ (1.000000,0.000000) [0.000000|3.000000] "" Vector__XXX
 SG_ KBI_Einheit_Verbrauch_elektr  : 12|3@1+ (1.000000,0.000000) [0.000000|7.000000] "" Vector__XXX
 SG_ KBI_Einheit_Tacho  : 15|1@1+ (1.000000,0.000000) [0.000000|1.000000] "" Motor_BEV
 SG_ KBI_Einheit_Sprache  : 16|8@1+ (1.000000,0.000000) [0.000000|255.000000] "" Vector__XXX
 SG_ KBI_Einheit_Verbrauch_Gas  : 24|4@1+ (1.000000,0.000000) [0.000000|15.000000] "" Vector__XXX
 SG_ KBI_Einheit_Masse  : 28|2@1+ (1.000000,0.000000) [0.000000|3.000000] "" Vector__XXX

BU_:  Airbag BAP_Tester ICAS1_Gateway ICAS1_KommunikationsServer LE1 LE2 Motor_BEV Schaltbetaetigung

BO_ 207 BMS_20: 8 ICAS1_Gateway
 SG_ BMS_20_CRC  : 0|8@1+ (1.000000,0.000000) [0.000000|255.000000] "" Motor_BEV
 SG_ BMS_20_BZ  : 8|4@1+ (1.000000,0.000000) [0.000000|15.000000] "" Motor_BEV
 SG_ BMS_Fehlerstatus_HV_Schuetze  : 13|2@1+ (1.000000,0.000000) [0.000000|3.000000] "" Motor_BEV
 SG_ BMS_ErwGrenzen_aktiv  : 15|1@1+ (1.000000,0.000000) [0.000000|1.000000] "" Motor_BEV
 SG_ BMS_IstModus  : 16|3@1+ (1.000000,0.000000) [0.000000|7.000000] "" LE1 LE2 Motor_BEV
 SG_ BMS_HVIL_Status  : 19|2@1+ (1.000000,0.000000) [0.000000|3.000000] "" Motor_BEV
 SG_ BMS_Fehler_HVBattAbschaltung  : 21|1@1+ (1.000000,0.000000) [0.000000|1.000000] "" Motor_BEV
 SG_ BMS_Fehler_HVBattAbschaltung_Anf  : 22|1@1+ (1.000000,0.000000) [0.000000|1.000000] "" Motor_BEV
 SG_ BMS_Fehler_Leistungsred  : 23|1@1+ (1.000000,0.000000) [0.000000|1.000000] "" Motor_BEV
 SG_ BMS_Strom  : 24|15@1+ (0.100000,-1630.000000) [-1630.000000|1630.000000] "Unit_Amper" Motor_BEV
 SG_ BMS_Fehler_Notabschaltung_Crash  : 39|1@1+ (1.000000,0.000000) [0.000000|1.000000] "" Vector__XXX
 SG_ BMS_Spannung_Zwischenkreis  : 40|12@1+ (0.500000,-1000.000000) [-1000.000000|1000.000000] "Unit_Volt" Motor_BEV
 SG_ BMS_Spannung  : 52|12@1+ (0.250000,0.000000) [0.000000|1000.000000] "Unit_Volt" Motor_BEV

BO_ 2463978704 BMS_21: 8 ICAS1_Gateway
 SG_ BMS_Max_Entladestrom  : 12|13@1+ (0.200000,0.000000) [0.000000|1630.000000] "Unit_Amper" Motor_BEV
 SG_ BMS_Max_Ladestrom  : 25|13@1+ (0.200000,0.000000) [0.000000|1630.000000] "Unit_Amper" Motor_BEV
 SG_ BMS_Max_Entladeleistung  : 38|13@1+ (100.000000,0.000000) [0.000000|818000.000000] "Unit_Watt" Motor_BEV
 SG_ BMS_Max_Ladeleistung  : 51|13@1+ (100.000000,0.000000) [0.000000|818000.000000] "Unit_Watt" Motor_BEV

BO_ 2463978705 BMS_22: 8 ICAS1_Gateway
 SG_ BMS_Status_EoHVL_Heizer  : 15|2@1+ (1.000000,0.000000) [0.000000|3.000000] "" Motor_BEV
 SG_ BMS_Ladezustand  : 17|11@1+ (0.050000,0.000000) [0.000000|100.000000] "Unit_PerCent" Motor_BEV
 SG_ BMS_PerfInd_Entladen  : 28|10@1+ (0.200000,0.000000) [0.000000|200.000000] "Unit_PerCent" Motor_BEV
 SG_ BMS_PerfInd_Laden  : 38|10@1+ (0.200000,0.000000) [0.000000|200.000000] "Unit_PerCent" Motor_BEV
 SG_ BMS_Nutzbare_EntladeEnergie  : 48|16@1+ (5.000000,0.000000) [0.000000|327400.000000] "Unit_WattHour" Motor_BEV

BO_ 2589283664 BMS_24: 8 ICAS1_Gateway
 SG_ BMS_Balancing_Aktiv  : 14|2@1+ (1.000000,0.000000) [0.000000|3.000000] "" Vector__XXX
 SG_ BMS_Ladevorgang_aktiv  : 16|1@1+ (1.000000,0.000000) [0.000000|1.000000] "" Vector__XXX
 SG_ BMS_RIso_Ext  : 17|12@1+ (5.000000,0.000000) [0.000000|20465.000000] "Unit_KiloOhm" Motor_BEV
 SG_ BMS_Min_Ladezustand  : 29|11@1+ (0.050000,0.000000) [0.000000|100.000000] "Unit_PerCent" Motor_BEV
 SG_ BMS_Max_Energie  : 40|13@1+ (40.000000,0.000000) [0.000000|327400.000000] "Unit_WattHour" Motor_BEV
 SG_ BMS_Max_Ladezustand  : 53|11@1+ (0.050000,0.000000) [0.000000|100.000000] "Unit_PerCent" Motor_BEV

BO_ 2589283665 BMS_25: 8 ICAS1_Gateway
 SG_ BMS_BattHeizung_VerbautStatus  : 13|1@1+ (1.000000,0.000000) [0.000000|1.000000] "" Motor_BEV
 SG_ BMS_Fehler_NTKreis  : 14|1@1+ (1.000000,0.000000) [0.000000|1.000000] "" Vector__XXX
 SG_ BMS_Temperierung_Anf  : 15|3@1+ (1.000000,0.000000) [0.000000|7.000000] "" Motor_BEV
 SG_ BMS_Status_Ventil1  : 18|3@1+ (1.000000,0.000000) [0.000000|7.000000] "" Motor_BEV
 SG_ BMS_Status_Ventil2  : 21|3@1+ (1.000000,0.000000) [0.000000|7.000000] "" Motor_BEV
 SG_ BMS_Pumpe1_Ansteuerung  : 24|4@1+ (10.000000,0.000000) [0.000000|100.000000] "Unit_PerCent" Motor_BEV
 SG_ BMS_Pumpe2_Ansteuerung  : 28|4@1+ (10.000000,0.000000) [0.000000|100.000000] "Unit_PerCent" Motor_BEV
 SG_ BMS_VorlaufTemperatur  : 32|8@1+ (0.500000,-40.000000) [-40.000000|86.000000] "Unit_DegreCelsi" Motor_BEV
 SG_ BMS_Temperatur  : 40|8@1+ (0.500000,-40.000000) [-40.000000|86.500000] "Unit_DegreCelsi" Motor_BEV
 SG_ BMS_SollVorlauftemperatur  : 48|8@1+ (0.500000,-40.000000) [-40.000000|86.500000] "Unit_DegreCelsi" Motor_BEV
 SG_ BMS_RuecklaufTemperatur  : 56|8@1+ (0.500000,-40.000000) [-40.000000|86.000000] "Unit_DegreCelsi" Motor_BEV

BO_ 2589283760 BMS_26: 8 ICAS1_Gateway
 SG_ BMS_Max_Spannung  : 20|10@1+ (1.000000,0.000000) [0.000000|1000.000000] "Unit_Volt" Motor_BEV
 SG_ BMS_Min_Spannung  : 30|10@1+ (1.000000,0.000000) [0.000000|1000.000000] "Unit_Volt" Motor_BEV
 SG_ BMS_Dauer_Entladeleistung  : 40|12@1+ (200.000000,0.000000) [0.000000|818000.000000] "Unit_Watt" Motor_BEV
 SG_ BMS_Dauer_Ladeleistung  : 52|12@1+ (200.000000,0.000000) [0.000000|818000.000000] "Unit_Watt" Motor_BEV

BO_ 2463978646 Charisma_11: 24 ICAS1_Gateway
 SG_ CHA_Ziel_FahrPr_AGA  : 0|4@1+ (1.000000,0.000000) [0.000000|15.000000] "" Vector__XXX
 SG_ CHA_Ziel_FahrPr_ESP  : 4|4@1+ (1.000000,0.000000) [0.000000|15.000000] "" Motor_BEV
 SG_ CHA_Ziel_FahrPr_Freilauf  : 8|4@1+ (1.000000,0.000000) [0.000000|15.000000] "" Vector__XXX
 SG_ CHA_Fahrer_Umschaltung  : 14|1@1+ (1.000000,0.000000) [0.000000|1.000000] "" Motor_BEV
 SG_ CHA_Fahrer_Umschaltung_BMA  : 15|1@1+ (1.000000,0.000000) [0.000000|1.000000] "" Vector__XXX
 SG_ CHA_Ziel_FahrPr_MO  : 16|4@1+ (1.000000,0.000000) [0.000000|15.000000] "" Motor_BEV
 SG_ CHA_Ziel_FahrPr_GE  : 20|4@1+ (1.000000,0.000000) [0.000000|15.000000] "" Vector__XXX
 SG_ CHA_Ziel_FahrPr_ALR  : 24|4@1+ (1.000000,0.000000) [0.000000|15.000000] "" Motor_BEV
 SG_ CHA_Ziel_FahrPr_MO_BZS  : 28|4@1+ (1.000000,0.000000) [0.000000|15.000000] "" Vector__XXX
 SG_ CHA_Ziel_FahrPr_DR  : 32|4@1+ (1.000000,0.000000) [0.000000|15.000000] "" Vector__XXX
 SG_ CHA_Ziel_FahrPr_VAQ  : 36|4@1+ (1.000000,0.000000) [0.000000|15.000000] "" Vector__XXX
 SG_ CHA_Ziel_FahrPr_AFS  : 40|4@1+ (1.000000,0.000000) [0.000000|15.000000] "" Vector__XXX
 SG_ CHA_Ziel_FahrPr_PreCrash  : 44|4@1+ (1.000000,0.000000) [0.000000|15.000000] "" Airbag
 SG_ CHA_Ziel_FahrPr_EPS  : 48|4@1+ (1.000000,0.000000) [0.000000|15.000000] "" Vector__XXX
 SG_ CHA_Ziel_FahrPr_ACC  : 52|4@1+ (1.000000,0.000000) [0.000000|15.000000] "" Vector__XXX
 SG_ CHA_Ziel_FahrPr_SAK  : 56|4@1+ (1.000000,0.000000) [0.000000|15.000000] "" Vector__XXX
 SG_ CHA_Ziel_FahrPr_MO_StSt  : 60|4@1+ (1.000000,0.000000) [0.000000|15.000000] "" Vector__XXX
 SG_ CHA_Ziel_FahrPr_EBKV  : 64|4@1+ (1.000000,0.000000) [0.000000|15.000000] "" Vector__XXX
 SG_ CHA_Ziel_FahrPr_IL  : 68|4@1+ (1.000000,0.000000) [0.000000|15.000000] "" Vector__XXX
 SG_ CHA_Current_Mode  : 72|4@1+ (1.000000,0.000000) [0.000000|15.000000] "" Vector__XXX
 SG_ CHA_Ziel_FahrPr_QS  : 80|4@1+ (1.000000,0.000000) [0.000000|15.000000] "" Vector__XXX
 SG_ CHA_Ziel_FahrPr_SCU  : 84|4@1+ (1.000000,0.000000) [0.000000|15.000000] "" Vector__XXX
 SG_ CHA_Ziel_FahrPr_HAL  : 88|4@1+ (1.000000,0.000000) [0.000000|15.000000] "" Vector__XXX
 SG_ CHA_Ziel_FahrPr_NR  : 92|4@1+ (1.000000,0.000000) [0.000000|15.000000] "" Vector__XXX
 SG_ CHA_Ziel_FahrPr_AV  : 96|4@1+ (1.000000,0.000000) [0.000000|15.000000] "" Vector__XXX
 SG_ CHA_Ziel_FahrPr_MXB  : 100|4@1+ (1.000000,0.000000) [0.000000|15.000000] "" Vector__XXX
 SG_ CHA_Ziel_FahrPr_AFR  : 104|4@1+ (1.000000,0.000000) [0.000000|15.000000] "" Vector__XXX
 SG_ CHA_Ziel_FahrPr_HDC  : 108|4@1+ (1.000000,0.000000) [0.000000|15.000000] "" Vector__XXX
 SG_ CHA_Ziel_FahrPr_EAR  : 112|4@1+ (1.000000,0.000000) [0.000000|15.000000] "" Vector__XXX
 SG_ CHA_Ziel_FahrPr_AEB  : 116|4@1+ (1.000000,0.000000) [0.000000|15.000000] "" Vector__XXX
 SG_ CHA_Ziel_FahrPr_FCWO  : 120|4@1+ (1.000000,0.000000) [0.000000|15.000000] "" Vector__XXX
 SG_ CHA_Ziel_FahrPr_FCWP  : 124|4@1+ (1.000000,0.000000) [0.000000|15.000000] "" Vector__XXX
 SG_ CHA_Ziel_FahrPr_ToS_laengs  : 144|4@1+ (1.000000,0.000000) [0.000000|15.000000] "" Vector__XXX
 SG_ CHA_Ziel_FahrPr_ToS_quer  : 148|4@1+ (1.000000,0.000000) [0.000000|15.000000] "" Vector__XXX
 SG_ CHA_Ziel_FahrPr_mFDR  : 152|4@1+ (1.000000,0.000000) [0.000000|15.000000] "" Vector__XXX
 SG_ CHA_Ziel_FahrPr_Reku_ZwGas  : 156|4@1+ (1.000000,0.000000) [0.000000|15.000000] "" Vector__XXX
 SG_ CHA_Ziel_FahrPr_MO_Freilauf  : 160|4@1+ (1.000000,0.000000) [0.000000|15.000000] "" Vector__XXX
 SG_ CHA_Ziel_FahrPr_BMS  : 164|4@1+ (1.000000,0.000000) [0.000000|15.000000] "" Vector__XXX
 SG_ CHA_Current_Mode_BMA  : 168|4@1+ (1.000000,0.000000) [0.000000|15.000000] "" Vector__XXX
 SG_ CHA_Ziel_FahrPr_PDC  : 172|4@1+ (1.000000,0.000000) [0.000000|15.000000] "" Vector__XXX
 SG_ CHA_Ziel_FahrPr_HHC  : 176|4@1+ (1.000000,0.000000) [0.000000|15.000000] "" Vector__XXX
 SG_ CHA_Ziel_FahrPr_EDS  : 180|4@1+ (1.000000,0.000000) [0.000000|15.000000] "" Vector__XXX
 SG_ CHA_Ziel_FahrPr_PACC  : 184|4@1+ (1.000000,0.000000) [0.000000|15.000000] "" Vector__XXX
 SG_ CHA_Ziel_FahrPr_AGK  : 188|4@1+ (1.000000,0.000000) [0.000000|15.000000] "" Vector__XXX

BO_ 514 Daempfer_03: 32 ICAS1_Gateway
 SG_ DR_Aufbaubeschleunigung_HR  : 12|10@1+ (0.032700,-15.696000) [-15.696000|15.696000] "Unit_MeterPerSeconSquar" Motor_BEV
 SG_ DR_Aufbaubeschleunigung_VR  : 22|10@1+ (0.032700,-15.696000) [-15.696000|15.696000] "Unit_MeterPerSeconSquar" Motor_BEV
 SG_ DR_Aufbaubeschleunigung_VL  : 32|10@1+ (0.032700,-15.696000) [-15.696000|15.696000] "Unit_MeterPerSeconSquar" Motor_BEV
 SG_ DR_Aufbaubeschleunigung_HL  : 42|10@1+ (0.032700,-15.696000) [-15.696000|15.696000] "Unit_MeterPerSeconSquar" Motor_BEV
 SG_ DR_Funktionsstatus  : 52|2@1+ (1.000000,0.000000) [0.000000|3.000000] "" Vector__XXX
 SG_ DR_Drehwinkelsensortausch_VL  : 72|2@1+ (1.000000,0.000000) [1.000000|3.000000] "" Vector__XXX
 SG_ DR_Drehwinkelsensortausch_VR  : 74|2@1+ (1.000000,0.000000) [1.000000|3.000000] "" Vector__XXX
 SG_ DR_Drehwinkelsensortausch_HL  : 76|2@1+ (1.000000,0.000000) [1.000000|3.000000] "" Vector__XXX
 SG_ DR_Drehwinkelsensortausch_HR  : 78|2@1+ (1.000000,0.000000) [1.000000|3.000000] "" Vector__XXX
 SG_ DR_Drehwinkel_VL  : 80|12@1+ (0.088000,0.000000) [0.000000|359.920000] "" Vector__XXX
 SG_ DR_Drehwinkel_VR  : 92|12@1+ (0.088000,0.000000) [0.000000|359.920000] "" Vector__XXX
 SG_ DR_Drehwinkel_HL  : 104|12@1+ (0.088000,0.000000) [0.000000|359.920000] "" Vector__XXX
 SG_ DR_Drehwinkel_HR  : 116|12@1+ (0.088000,0.000000) [0.000000|359.920000] "" Vector__XXX

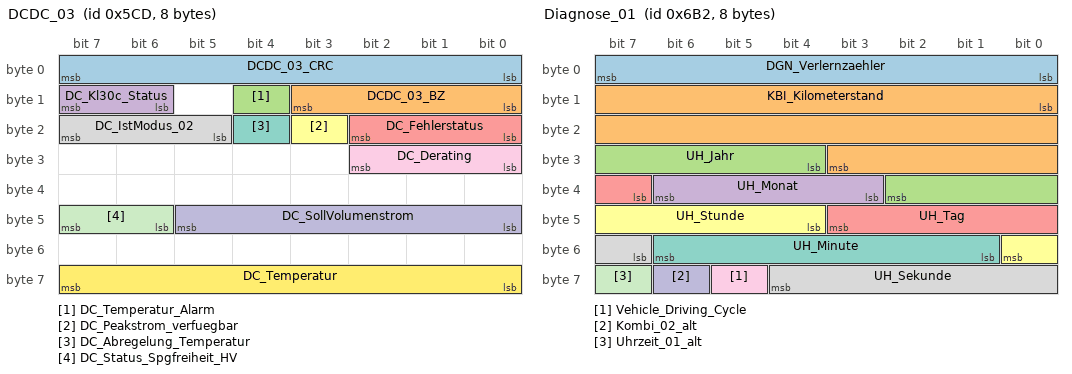
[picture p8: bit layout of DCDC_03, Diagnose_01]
BO_ 1485 DCDC_03: 8 ICAS1_Gateway
 SG_ DCDC_03_CRC  : 0|8@1+ (1.000000,0.000000) [0.000000|255.000000] "" Motor_BEV
 SG_ DCDC_03_BZ  : 8|4@1+ (1.000000,0.000000) [0.000000|15.000000] "" Motor_BEV
 SG_ DC_Temperatur_Alarm  : 12|1@1+ (1.000000,0.000000) [0.000000|1.000000] "" Vector__XXX
 SG_ DC_Kl30c_Status  : 14|2@1+ (1.000000,0.000000) [0.000000|3.000000] "" Motor_BEV
 SG_ DC_Fehlerstatus  : 16|3@1+ (1.000000,0.000000) [0.000000|7.000000] "" Vector__XXX
 SG_ DC_Peakstrom_verfuegbar  : 19|1@1+ (1.000000,0.000000) [0.000000|1.000000] "" Vector__XXX
 SG_ DC_Abregelung_Temperatur  : 20|1@1+ (1.000000,0.000000) [0.000000|1.000000] "" Vector__XXX
 SG_ DC_IstModus_02  : 21|3@1+ (1.000000,0.000000) [0.000000|7.000000] "" Vector__XXX
 SG_ DC_Derating  : 24|3@1+ (1.000000,0.000000) [0.000000|7.000000] "" Vector__XXX
 SG_ DC_SollVolumenstrom  : 40|6@1+ (0.500000,0.000000) [0.000000|30.500000] "Unit_LiterPerMinut" Motor_BEV
 SG_ DC_Status_Spgfreiheit_HV  : 46|2@1+ (1.000000,0.000000) [0.000000|3.000000] "" Vector__XXX
 SG_ DC_Temperatur  : 56|8@1+ (1.000000,-40.000000) [-40.000000|213.000000] "Unit_DegreCelsi" Motor_BEV

BO_ 247 DCDC_04: 8 ICAS1_Gateway
 SG_ DCDC_04_CRC  : 0|8@1+ (1.000000,0.000000) [0.000000|255.000000] "" Vector__XXX
 SG_ DCDC_04_BZ  : 8|4@1+ (1.000000,0.000000) [0.000000|15.000000] "" Vector__XXX
 SG_ DC_Vorladung_Status  : 34|1@1+ (1.000000,0.000000) [0.000000|1.000000] "" Motor_BEV
 SG_ DC_Fehler_extern  : 35|1@1+ (1.000000,0.000000) [0.000000|1.000000] "" Motor_BEV
 SG_ DC_Fehler_intern  : 36|1@1+ (1.000000,0.000000) [0.000000|1.000000] "" Motor_BEV
 SG_ DC_Status_Spgfreiheit  : 37|2@1+ (1.000000,0.000000) [0.000000|3.000000] "" Motor_BEV
 SG_ DC_Status_EoHVL  : 39|2@1+ (1.000000,0.000000) [0.000000|3.000000] "" Motor_BEV
 SG_ DC_IstModus_02  : 41|3@1+ (1.000000,0.000000) [0.000000|7.000000] "" Motor_BEV
 SG_ DC_IstStrom_HV  : 44|10@1+ (0.100000,-51.100000) [-51.100000|51.000000] "Unit_Amper" Motor_BEV
 SG_ DC_IstLeistung_HV  : 54|10@1+ (10.000000,-4000.000000) [-4000.000000|6210.000000] "Unit_Watt" Motor_BEV

BO_ 2617027088 DEV_Airbag_ASM_01: 8 Airbag
 SG_ DEV_Airbag_ASM_01_Data  : 0|64@1+ (1.000000,0.000000) [0.000000|18446744073709551616.000000] "" Vector__XXX

BO_ 2617027072 DEV_Airbag_Resp_00: 8 Airbag
 SG_ DEV_Airbag_Resp_00_Data  : 0|64@1+ (1.000000,0.000000) [0.000000|18446744073709551616.000000] "" Vector__XXX

BO_ 2617027073 DEV_Airbag_Resp_01: 8 Airbag
 SG_ DEV_Airbag_Resp_01_Data  : 0|64@1+ (1.000000,0.000000) [0.000000|18446744073709551616.000000] "" Vector__XXX

BO_ 2617027074 DEV_Airbag_Resp_02: 8 Airbag
 SG_ DEV_Airbag_Resp_02_Data  : 0|64@1+ (1.000000,0.000000) [0.000000|18446744073709551616.000000] "" Vector__XXX

BO_ 2617027075 DEV_Airbag_Resp_03: 8 Airbag
 SG_ DEV_Airbag_Resp_03_Data  : 0|64@1+ (1.000000,0.000000) [0.000000|18446744073709551616.000000] "" Vector__XXX

BO_ 2617027076 DEV_Airbag_Resp_04: 8 Airbag
 SG_ DEV_Airbag_Resp_04_Data  : 0|64@1+ (1.000000,0.000000) [0.000000|18446744073709551616.000000] "" Vector__XXX

BO_ 2617027077 DEV_Airbag_Resp_05: 8 Airbag
 SG_ DEV_Airbag_Resp_05_Data  : 0|64@1+ (1.000000,0.000000) [0.000000|18446744073709551616.000000] "" Vector__XXX

BO_ 2617027078 DEV_Airbag_Resp_06: 8 Airbag
 SG_ DEV_Airbag_Resp_06_Data  : 0|64@1+ (1.000000,0.000000) [0.000000|18446744073709551616.000000] "" Vector__XXX

BO_ 2617027079 DEV_Airbag_Resp_07: 8 Airbag
 SG_ DEV_Airbag_Resp_07_Data  : 0|64@1+ (1.000000,0.000000) [0.000000|18446744073709551616.000000] "" Vector__XXX

BO_ 2617027080 DEV_Airbag_Resp_08: 8 Airbag
 SG_ DEV_Airbag_Resp_08_Data  : 0|64@1+ (1.000000,0.000000) [0.000000|18446744073709551616.000000] "" Vector__XXX

BO_ 2617027081 DEV_Airbag_Resp_09: 8 Airbag
 SG_ DEV_Airbag_Resp_09_Data  : 0|64@1+ (1.000000,0.000000) [0.000000|18446744073709551616.000000] "" Vector__XXX

BO_ 2617027082 DEV_Airbag_Resp_10: 8 Airbag
 SG_ DEV_Airbag_Resp_10_Data  : 0|64@1+ (1.000000,0.000000) [0.000000|18446744073709551616.000000] "" Vector__XXX

BO_ 2617027083 DEV_Airbag_Resp_11: 8 Airbag
 SG_ DEV_Airbag_Resp_11_Data  : 0|64@1+ (1.000000,0.000000) [0.000000|18446744073709551616.000000] "" Vector__XXX

BO_ 2617154048 DEV_Waehlhebel_Resp_00: 8 Schaltbetaetigung
 SG_ DEV_Waehlhebel_Resp_00_Data  : 0|64@1+ (1.000000,0.000000) [0.000000|18446744073709551616.000000] "" Vector__XXX

BO_ 2617154049 DEV_Waehlhebel_Resp_01: 8 Schaltbetaetigung
 SG_ DEV_Waehlhebel_Resp_01_Data  : 0|64@1+ (1.000000,0.000000) [0.000000|18446744073709551616.000000] "" Vector__XXX

BO_ 2617154050 DEV_Waehlhebel_Resp_02: 8 Schaltbetaetigung
 SG_ DEV_Waehlhebel_Resp_02_Data  : 0|64@1+ (1.000000,0.000000) [0.000000|18446744073709551616.000000] "" Vector__XXX

BO_ 2617154051 DEV_Waehlhebel_Resp_03: 8 Schaltbetaetigung
 SG_ DEV_Waehlhebel_Resp_03_Data  : 0|64@1+ (1.000000,0.000000) [0.000000|18446744073709551616.000000] "" Vector__XXX

BO_ 2617154052 DEV_Waehlhebel_Resp_04: 8 Schaltbetaetigung
 SG_ DEV_Waehlhebel_Resp_04_Data  : 0|64@1+ (1.000000,0.000000) [0.000000|18446744073709551616.000000] "" Vector__XXX

BO_ 2617154053 DEV_Waehlhebel_Resp_05: 8 Schaltbetaetigung
 SG_ DEV_Waehlhebel_Resp_05_Data  : 0|64@1+ (1.000000,0.000000) [0.000000|18446744073709551616.000000] "" Vector__XXX

BO_ 2549876269 Diag_Waehlhebel_Req: 8 Motor_BEV
 SG_ Diag_Waehlhebel_Req_Data  : 0|64@1+ (1.000000,0.000000) [0.000000|18446744073709551616.000000] "" Schaltbetaetigung

BO_ 2550007341 Diag_Waehlhebel_Resp: 8 Schaltbetaetigung
 SG_ Diag_Waehlhebel_Resp_Data  : 0|64@1+ (1.000000,0.000000) [0.000000|18446744073709551616.000000] "" Motor_BEV

BO_ 1714 Diagnose_01: 8 ICAS1_Gateway
 SG_ DGN_Verlernzaehler  : 0|8@1+ (1.000000,0.000000) [0.000000|254.000000] "" Airbag LE1 LE2 Motor_BEV
 SG_ KBI_Kilometerstand  : 8|20@1+ (1.000000,0.000000) [0.000000|1048573.000000] "Unit_KiloMeter" Airbag LE1 LE2 Motor_BEV
 SG_ UH_Jahr  : 28|7@1+ (1.000000,2000.000000) [2000.000000|2127.000000] "Unit_Year" Airbag LE1 LE2 Motor_BEV
 SG_ UH_Monat  : 35|4@1+ (1.000000,0.000000) [1.000000|12.000000] "Unit_Month" Airbag LE1 LE2 Motor_BEV
 SG_ UH_Tag  : 39|5@1+ (1.000000,0.000000) [1.000000|31.000000] "Unit_Day" Airbag LE1 LE2 Motor_BEV
 SG_ UH_Stunde  : 44|5@1+ (1.000000,0.000000) [0.000000|23.000000] "Unit_Hours" Airbag LE1 LE2 Motor_BEV
 SG_ UH_Minute  : 49|6@1+ (1.000000,0.000000) [0.000000|59.000000] "Unit_Minut" Airbag LE1 LE2 Motor_BEV
 SG_ UH_Sekunde  : 55|6@1+ (1.000000,0.000000) [0.000000|59.000000] "Unit_Secon" Airbag LE1 LE2 Motor_BEV
 SG_ Vehicle_Driving_Cycle  : 61|1@1+ (1.000000,0.000000) [0.000000|1.000000] "" Airbag
 SG_ Kombi_02_alt  : 62|1@1+ (1.000000,0.000000) [0.000000|1.000000] "" Vector__XXX
 SG_ Uhrzeit_01_alt  : 63|1@1+ (1.000000,0.000000) [0.000000|1.000000] "" Vector__XXX

BO_ 851 DiETa_01: 8 ICAS1_Gateway
 SG_ DiETas_01_CRC  : 0|8@1+ (1.000000,0.000000) [0.000000|255.000000] "" Airbag
 SG_ DiETas_01_BZ  : 8|4@1+ (1.000000,0.000000) [0.000000|15.000000] "" Airbag
 SG_ DiETa_Reserve_Byte2_4  : 12|1@1+ (1.000000,0.000000) [0.000000|1.000000] "" Vector__XXX
 SG_ DiETa_Status  : 13|2@1+ (1.000000,0.000000) [0.000000|3.000000] "" Airbag
 SG_ DiETa_ResponseError  : 15|1@1+ (1.000000,0.000000) [0.000000|1.000000] "" Vector__XXX
 SG_ DiETa_Car  : 16|2@1+ (1.000000,0.000000) [0.000000|3.000000] "" Vector__XXX
 SG_ DiETa_Klima  : 18|2@1+ (1.000000,0.000000) [0.000000|3.000000] "" Vector__XXX
 SG_ DiETa_Mode  : 20|2@1+ (1.000000,0.000000) [0.000000|3.000000] "" Vector__XXX
 SG_ DiETa_Parken  : 22|2@1+ (1.000000,0.000000) [0.000000|3.000000] "" Vector__XXX
 SG_ DiETa_FSH_Taste  : 24|2@1+ (1.000000,0.000000) [0.000000|3.000000] "" Vector__XXX
 SG_ DiETa_HSH_Taste  : 26|2@1+ (1.000000,0.000000) [0.000000|3.000000] "" Vector__XXX
 SG_ DiETa_Warnblink_Taste  : 28|2@1+ (1.000000,0.000000) [0.000000|3.000000] "" Vector__XXX
 SG_ DiETa_FAS_Stufe  : 30|2@1+ (1.000000,0.000000) [0.000000|3.000000] "" Vector__XXX
 SG_ DiETa_PAO_ON_Status  : 32|2@1+ (1.000000,0.000000) [0.000000|3.000000] "" Airbag
 SG_ DiETa_PAO_OFF_Status  : 34|2@1+ (1.000000,0.000000) [0.000000|3.000000] "" Airbag
 SG_ DiETa_Defrost_Taste  : 36|2@1+ (1.000000,0.000000) [0.000000|3.000000] "" Vector__XXX
 SG_ DiETa_Reserve_Byte5_6  : 38|2@1+ (1.000000,0.000000) [0.000000|3.000000] "" Vector__XXX
 SG_ DiETa_Lock_Unlock_Taste  : 40|3@1+ (1.000000,0.000000) [0.000000|7.000000] "" Vector__XXX
 SG_ DiETa_Mode_roh  : 43|1@1+ (1.000000,0.000000) [0.000000|1.000000] "" Vector__XXX
 SG_ DiETa_Reserve_Byte6_3  : 44|4@1+ (1.000000,0.000000) [0.000000|15.000000] "" Vector__XXX
 SG_ DiETa_Reserve_Byte7  : 48|8@1+ (1.000000,0.000000) [0.000000|255.000000] "" Vector__XXX
 SG_ DiETa_Reserve_Byte8  : 56|8@1+ (1.000000,0.000000) [0.000000|255.000000] "" Vector__XXX

BO_ 1520 Dimmung_01: 8 ICAS1_Gateway
 SG_ DI_KL_58xd  : 0|8@1+ (1.000000,0.000000) [0.000000|253.000000] "" Airbag Schaltbetaetigung
 SG_ DI_KL_58xs  : 8|7@1+ (1.000000,0.000000) [0.000000|100.000000] "Unit_PerCent" Airbag
 SG_ DI_Display_Nachtdesign  : 15|1@1+ (1.000000,0.000000) [0.000000|1.000000] "" Vector__XXX
 SG_ DI_KL_58xt  : 16|7@1+ (1.000000,0.000000) [0.000000|100.000000] "Unit_PerCent" Airbag Schaltbetaetigung
 SG_ DI_Fotosensor  : 24|16@1+ (1.000000,0.000000) [0.000000|65535.000000] "" Vector__XXX
 SG_ BCM1_Stellgroesse_Kl_58s  : 40|7@1+ (1.000000,0.000000) [0.000000|100.000000] "" Vector__XXX

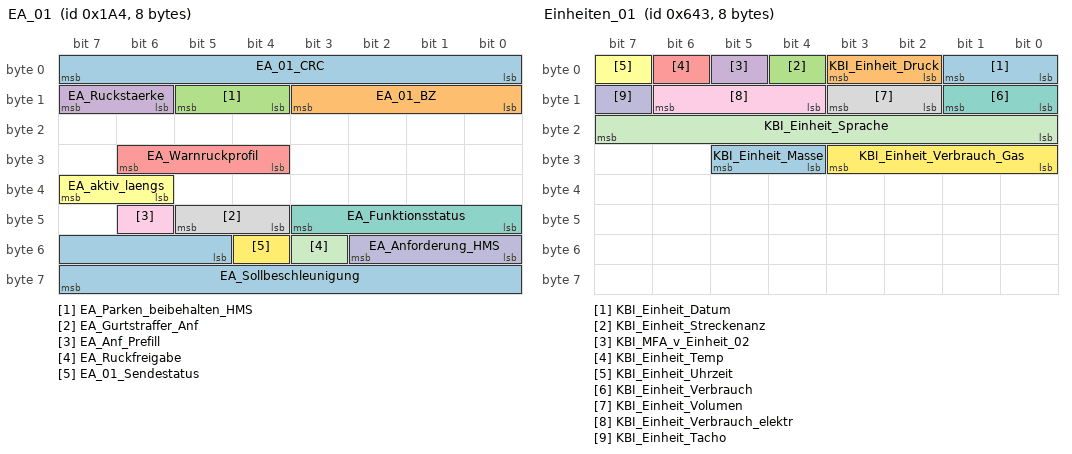
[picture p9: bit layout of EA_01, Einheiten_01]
BO_ 420 EA_01: 8 ICAS1_Gateway
 SG_ EA_01_CRC  : 0|8@1+ (1.000000,0.000000) [0.000000|255.000000] "" Motor_BEV
 SG_ EA_01_BZ  : 8|4@1+ (1.000000,0.000000) [0.000000|15.000000] "" Motor_BEV
 SG_ EA_Parken_beibehalten_HMS  : 12|2@1+ (1.000000,0.000000) [0.000000|3.000000] "" Vector__XXX
 SG_ EA_Ruckstaerke  : 14|2@1+ (1.000000,0.000000) [0.000000|3.000000] "" Vector__XXX
 SG_ EA_Warnruckprofil  : 28|3@1+ (1.000000,0.000000) [0.000000|7.000000] "" Vector__XXX
 SG_ EA_aktiv_laengs  : 38|2@1+ (1.000000,0.000000) [0.000000|3.000000] "" Motor_BEV
 SG_ EA_Funktionsstatus  : 40|4@1+ (1.000000,0.000000) [0.000000|15.000000] "" Motor_BEV
 SG_ EA_Gurtstraffer_Anf  : 44|2@1+ (1.000000,0.000000) [0.000000|3.000000] "" Airbag
 SG_ EA_Anf_Prefill  : 46|1@1+ (1.000000,0.000000) [0.000000|1.000000] "" Vector__XXX
 SG_ EA_Anforderung_HMS  : 48|3@1+ (1.000000,0.000000) [0.000000|7.000000] "" Vector__XXX
 SG_ EA_Ruckfreigabe  : 51|1@1+ (1.000000,0.000000) [0.000000|1.000000] "" Vector__XXX
 SG_ EA_01_Sendestatus  : 52|1@1+ (1.000000,0.000000) [0.000000|1.000000] "" Vector__XXX
 SG_ EA_Sollbeschleunigung  : 53|11@1+ (0.005000,-7.220000) [-7.220000|3.005000] "Unit_MeterPerSeconSquar" Motor_BEV

BO_ 374 EBKV_03: 8 ICAS1_Gateway
 SG_ EBKV_03_CRC  : 0|8@1+ (1.000000,0.000000) [0.000000|255.000000] "" Vector__XXX
 SG_ EBKV_03_BZ  : 8|4@1+ (1.000000,0.000000) [0.000000|15.000000] "" Vector__XXX
 SG_ EBKV_Activate_Fallback_ESP  : 12|1@1+ (1.000000,0.000000) [0.000000|1.000000] "" Vector__XXX
 SG_ EBKV_Restdruckabsenkung  : 13|3@1+ (1.000000,0.000000) [0.000000|7.000000] "" Vector__XXX
 SG_ EBKV_Status_02  : 16|4@1+ (1.000000,0.000000) [0.000000|15.000000] "" Vector__XXX
 SG_ EBKV_Diagnose  : 20|1@1+ (1.000000,0.000000) [0.000000|1.000000] "" Vector__XXX
 SG_ EBKV_Fahrer_bremst  : 21|1@1+ (1.000000,0.000000) [0.000000|1.000000] "" Motor_BEV
 SG_ EBKV_QBit_Fahrer_bremst  : 22|1@1+ (1.000000,0.000000) [0.000000|1.000000] "" Motor_BEV
 SG_ EBKV_Fahrer_bremst_deutlich  : 23|1@1+ (1.000000,0.000000) [0.000000|1.000000] "" Vector__XXX
 SG_ EBKV_OBD_Status  : 24|1@1+ (1.000000,0.000000) [0.000000|1.000000] "" Motor_BEV
 SG_ EBKV_VMM_Sek_Notstopp_Status  : 25|3@1+ (1.000000,0.000000) [0.000000|7.000000] "" Vector__XXX
 SG_ EBKV_Anforderung_HMS  : 28|3@1+ (1.000000,0.000000) [0.000000|7.000000] "" Vector__XXX
 SG_ SBS_Anforderung_GE  : 31|1@1+ (1.000000,0.000000) [0.000000|1.000000] "" Vector__XXX
 SG_ EPB_Status_ext  : 32|3@1+ (1.000000,0.000000) [0.000000|7.000000] "" Motor_BEV
 SG_ EBKV_Bremspedalweg  : 40|8@1+ (0.400000,-0.400000) [0.000000|101.200000] "Unit_PerCent" Motor_BEV
 SG_ EBKV_Kraftblending_Reserve  : 48|8@1+ (0.500000,0.000000) [0.000000|125.000000] "Unit_Bar" Vector__XXX
 SG_ EBKV_Aussteuerdruck  : 56|8@1+ (1.000000,0.000000) [0.000000|250.000000] "Unit_Bar" Vector__XXX

BO_ 1603 Einheiten_01: 8 ICAS1_KommunikationsServer
 SG_ KBI_Einheit_Datum  : 0|2@1+ (1.000000,0.000000) [0.000000|3.000000] "" Vector__XXX
 SG_ KBI_Einheit_Druck  : 2|2@1+ (1.000000,0.000000) [0.000000|3.000000] "" Vector__XXX
 SG_ KBI_Einheit_Streckenanz  : 4|1@1+ (1.000000,0.000000) [0.000000|1.000000] "" Vector__XXX
 SG_ KBI_MFA_v_Einheit_02  : 5|1@1+ (1.000000,0.000000) [0.000000|1.000000] "" Motor_BEV
 SG_ KBI_Einheit_Temp  : 6|1@1+ (1.000000,0.000000) [0.000000|1.000000] "" Vector__XXX
 SG_ KBI_Einheit_Uhrzeit  : 7|1@1+ (1.000000,0.000000) [0.000000|1.000000] "" Vector__XXX
 SG_ KBI_Einheit_Verbrauch  : 8|2@1+ (1.000000,0.000000) [0.000000|3.000000] "" Vector__XXX
 SG_ KBI_Einheit_Volumen  : 10|2@1+ (1.000000,0.000000) [0.000000|3.000000] "" Vector__XXX
 SG_ KBI_Einheit_Verbrauch_elektr  : 12|3@1+ (1.000000,0.000000) [0.000000|7.000000] "" Vector__XXX
 SG_ KBI_Einheit_Tacho  : 15|1@1+ (1.000000,0.000000) [0.000000|1.000000] "" Motor_BEV
 SG_ KBI_Einheit_Sprache  : 16|8@1+ (1.000000,0.000000) [0.000000|255.000000] "" Vector__XXX
 SG_ KBI_Einheit_Verbrauch_Gas  : 24|4@1+ (1.000000,0.000000) [0.000000|15.000000] "" Vector__XXX
 SG_ KBI_Einheit_Masse  : 28|2@1+ (1.000000,0.000000) [0.000000|3.000000] "" Vector__XXX

BU_:  Airbag BAP_Tester ICAS1_Gateway ICAS1_KommunikationsServer LE1 LE2 Motor_BEV Schaltbetaetigung

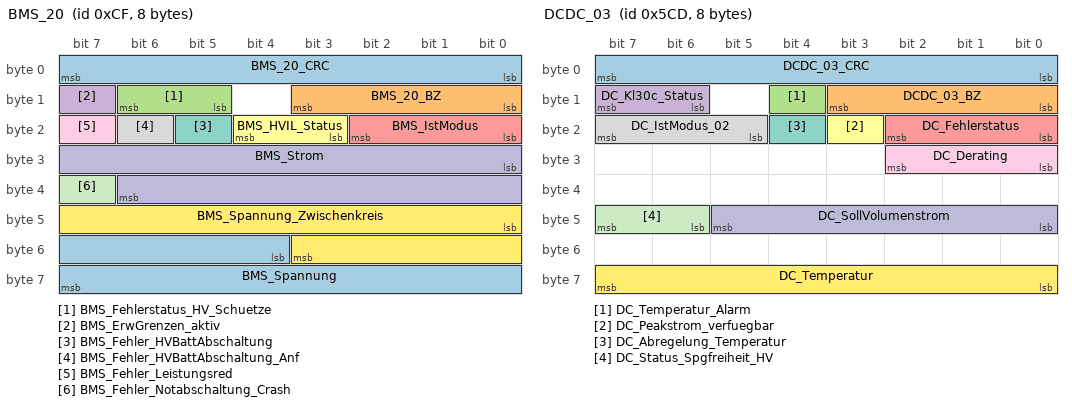
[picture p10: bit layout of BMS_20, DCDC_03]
BO_ 207 BMS_20: 8 ICAS1_Gateway
 SG_ BMS_20_CRC  : 0|8@1+ (1.000000,0.000000) [0.000000|255.000000] "" Motor_BEV
 SG_ BMS_20_BZ  : 8|4@1+ (1.000000,0.000000) [0.000000|15.000000] "" Motor_BEV
 SG_ BMS_Fehlerstatus_HV_Schuetze  : 13|2@1+ (1.000000,0.000000) [0.000000|3.000000] "" Motor_BEV
 SG_ BMS_ErwGrenzen_aktiv  : 15|1@1+ (1.000000,0.000000) [0.000000|1.000000] "" Motor_BEV
 SG_ BMS_IstModus  : 16|3@1+ (1.000000,0.000000) [0.000000|7.000000] "" LE1 LE2 Motor_BEV
 SG_ BMS_HVIL_Status  : 19|2@1+ (1.000000,0.000000) [0.000000|3.000000] "" Motor_BEV
 SG_ BMS_Fehler_HVBattAbschaltung  : 21|1@1+ (1.000000,0.000000) [0.000000|1.000000] "" Motor_BEV
 SG_ BMS_Fehler_HVBattAbschaltung_Anf  : 22|1@1+ (1.000000,0.000000) [0.000000|1.000000] "" Motor_BEV
 SG_ BMS_Fehler_Leistungsred  : 23|1@1+ (1.000000,0.000000) [0.000000|1.000000] "" Motor_BEV
 SG_ BMS_Strom  : 24|15@1+ (0.100000,-1630.000000) [-1630.000000|1630.000000] "Unit_Amper" Motor_BEV
 SG_ BMS_Fehler_Notabschaltung_Crash  : 39|1@1+ (1.000000,0.000000) [0.000000|1.000000] "" Vector__XXX
 SG_ BMS_Spannung_Zwischenkreis  : 40|12@1+ (0.500000,-1000.000000) [-1000.000000|1000.000000] "Unit_Volt" Motor_BEV
 SG_ BMS_Spannung  : 52|12@1+ (0.250000,0.000000) [0.000000|1000.000000] "Unit_Volt" Motor_BEV

BO_ 2463978704 BMS_21: 8 ICAS1_Gateway
 SG_ BMS_Max_Entladestrom  : 12|13@1+ (0.200000,0.000000) [0.000000|1630.000000] "Unit_Amper" Motor_BEV
 SG_ BMS_Max_Ladestrom  : 25|13@1+ (0.200000,0.000000) [0.000000|1630.000000] "Unit_Amper" Motor_BEV
 SG_ BMS_Max_Entladeleistung  : 38|13@1+ (100.000000,0.000000) [0.000000|818000.000000] "Unit_Watt" Motor_BEV
 SG_ BMS_Max_Ladeleistung  : 51|13@1+ (100.000000,0.000000) [0.000000|818000.000000] "Unit_Watt" Motor_BEV

BO_ 2463978705 BMS_22: 8 ICAS1_Gateway
 SG_ BMS_Status_EoHVL_Heizer  : 15|2@1+ (1.000000,0.000000) [0.000000|3.000000] "" Motor_BEV
 SG_ BMS_Ladezustand  : 17|11@1+ (0.050000,0.000000) [0.000000|100.000000] "Unit_PerCent" Motor_BEV
 SG_ BMS_PerfInd_Entladen  : 28|10@1+ (0.200000,0.000000) [0.000000|200.000000] "Unit_PerCent" Motor_BEV
 SG_ BMS_PerfInd_Laden  : 38|10@1+ (0.200000,0.000000) [0.000000|200.000000] "Unit_PerCent" Motor_BEV
 SG_ BMS_Nutzbare_EntladeEnergie  : 48|16@1+ (5.000000,0.000000) [0.000000|327400.000000] "Unit_WattHour" Motor_BEV

BO_ 2589283664 BMS_24: 8 ICAS1_Gateway
 SG_ BMS_Balancing_Aktiv  : 14|2@1+ (1.000000,0.000000) [0.000000|3.000000] "" Vector__XXX
 SG_ BMS_Ladevorgang_aktiv  : 16|1@1+ (1.000000,0.000000) [0.000000|1.000000] "" Vector__XXX
 SG_ BMS_RIso_Ext  : 17|12@1+ (5.000000,0.000000) [0.000000|20465.000000] "Unit_KiloOhm" Motor_BEV
 SG_ BMS_Min_Ladezustand  : 29|11@1+ (0.050000,0.000000) [0.000000|100.000000] "Unit_PerCent" Motor_BEV
 SG_ BMS_Max_Energie  : 40|13@1+ (40.000000,0.000000) [0.000000|327400.000000] "Unit_WattHour" Motor_BEV
 SG_ BMS_Max_Ladezustand  : 53|11@1+ (0.050000,0.000000) [0.000000|100.000000] "Unit_PerCent" Motor_BEV

BO_ 2589283665 BMS_25: 8 ICAS1_Gateway
 SG_ BMS_BattHeizung_VerbautStatus  : 13|1@1+ (1.000000,0.000000) [0.000000|1.000000] "" Motor_BEV
 SG_ BMS_Fehler_NTKreis  : 14|1@1+ (1.000000,0.000000) [0.000000|1.000000] "" Vector__XXX
 SG_ BMS_Temperierung_Anf  : 15|3@1+ (1.000000,0.000000) [0.000000|7.000000] "" Motor_BEV
 SG_ BMS_Status_Ventil1  : 18|3@1+ (1.000000,0.000000) [0.000000|7.000000] "" Motor_BEV
 SG_ BMS_Status_Ventil2  : 21|3@1+ (1.000000,0.000000) [0.000000|7.000000] "" Motor_BEV
 SG_ BMS_Pumpe1_Ansteuerung  : 24|4@1+ (10.000000,0.000000) [0.000000|100.000000] "Unit_PerCent" Motor_BEV
 SG_ BMS_Pumpe2_Ansteuerung  : 28|4@1+ (10.000000,0.000000) [0.000000|100.000000] "Unit_PerCent" Motor_BEV
 SG_ BMS_VorlaufTemperatur  : 32|8@1+ (0.500000,-40.000000) [-40.000000|86.000000] "Unit_DegreCelsi" Motor_BEV
 SG_ BMS_Temperatur  : 40|8@1+ (0.500000,-40.000000) [-40.000000|86.500000] "Unit_DegreCelsi" Motor_BEV
 SG_ BMS_SollVorlauftemperatur  : 48|8@1+ (0.500000,-40.000000) [-40.000000|86.500000] "Unit_DegreCelsi" Motor_BEV
 SG_ BMS_RuecklaufTemperatur  : 56|8@1+ (0.500000,-40.000000) [-40.000000|86.000000] "Unit_DegreCelsi" Motor_BEV

BO_ 2589283760 BMS_26: 8 ICAS1_Gateway
 SG_ BMS_Max_Spannung  : 20|10@1+ (1.000000,0.000000) [0.000000|1000.000000] "Unit_Volt" Motor_BEV
 SG_ BMS_Min_Spannung  : 30|10@1+ (1.000000,0.000000) [0.000000|1000.000000] "Unit_Volt" Motor_BEV
 SG_ BMS_Dauer_Entladeleistung  : 40|12@1+ (200.000000,0.000000) [0.000000|818000.000000] "Unit_Watt" Motor_BEV
 SG_ BMS_Dauer_Ladeleistung  : 52|12@1+ (200.000000,0.000000) [0.000000|818000.000000] "Unit_Watt" Motor_BEV

BO_ 2463978646 Charisma_11: 24 ICAS1_Gateway
 SG_ CHA_Ziel_FahrPr_AGA  : 0|4@1+ (1.000000,0.000000) [0.000000|15.000000] "" Vector__XXX
 SG_ CHA_Ziel_FahrPr_ESP  : 4|4@1+ (1.000000,0.000000) [0.000000|15.000000] "" Motor_BEV
 SG_ CHA_Ziel_FahrPr_Freilauf  : 8|4@1+ (1.000000,0.000000) [0.000000|15.000000] "" Vector__XXX
 SG_ CHA_Fahrer_Umschaltung  : 14|1@1+ (1.000000,0.000000) [0.000000|1.000000] "" Motor_BEV
 SG_ CHA_Fahrer_Umschaltung_BMA  : 15|1@1+ (1.000000,0.000000) [0.000000|1.000000] "" Vector__XXX
 SG_ CHA_Ziel_FahrPr_MO  : 16|4@1+ (1.000000,0.000000) [0.000000|15.000000] "" Motor_BEV
 SG_ CHA_Ziel_FahrPr_GE  : 20|4@1+ (1.000000,0.000000) [0.000000|15.000000] "" Vector__XXX
 SG_ CHA_Ziel_FahrPr_ALR  : 24|4@1+ (1.000000,0.000000) [0.000000|15.000000] "" Motor_BEV
 SG_ CHA_Ziel_FahrPr_MO_BZS  : 28|4@1+ (1.000000,0.000000) [0.000000|15.000000] "" Vector__XXX
 SG_ CHA_Ziel_FahrPr_DR  : 32|4@1+ (1.000000,0.000000) [0.000000|15.000000] "" Vector__XXX
 SG_ CHA_Ziel_FahrPr_VAQ  : 36|4@1+ (1.000000,0.000000) [0.000000|15.000000] "" Vector__XXX
 SG_ CHA_Ziel_FahrPr_AFS  : 40|4@1+ (1.000000,0.000000) [0.000000|15.000000] "" Vector__XXX
 SG_ CHA_Ziel_FahrPr_PreCrash  : 44|4@1+ (1.000000,0.000000) [0.000000|15.000000] "" Airbag
 SG_ CHA_Ziel_FahrPr_EPS  : 48|4@1+ (1.000000,0.000000) [0.000000|15.000000] "" Vector__XXX
 SG_ CHA_Ziel_FahrPr_ACC  : 52|4@1+ (1.000000,0.000000) [0.000000|15.000000] "" Vector__XXX
 SG_ CHA_Ziel_FahrPr_SAK  : 56|4@1+ (1.000000,0.000000) [0.000000|15.000000] "" Vector__XXX
 SG_ CHA_Ziel_FahrPr_MO_StSt  : 60|4@1+ (1.000000,0.000000) [0.000000|15.000000] "" Vector__XXX
 SG_ CHA_Ziel_FahrPr_EBKV  : 64|4@1+ (1.000000,0.000000) [0.000000|15.000000] "" Vector__XXX
 SG_ CHA_Ziel_FahrPr_IL  : 68|4@1+ (1.000000,0.000000) [0.000000|15.000000] "" Vector__XXX
 SG_ CHA_Current_Mode  : 72|4@1+ (1.000000,0.000000) [0.000000|15.000000] "" Vector__XXX
 SG_ CHA_Ziel_FahrPr_QS  : 80|4@1+ (1.000000,0.000000) [0.000000|15.000000] "" Vector__XXX
 SG_ CHA_Ziel_FahrPr_SCU  : 84|4@1+ (1.000000,0.000000) [0.000000|15.000000] "" Vector__XXX
 SG_ CHA_Ziel_FahrPr_HAL  : 88|4@1+ (1.000000,0.000000) [0.000000|15.000000] "" Vector__XXX
 SG_ CHA_Ziel_FahrPr_NR  : 92|4@1+ (1.000000,0.000000) [0.000000|15.000000] "" Vector__XXX
 SG_ CHA_Ziel_FahrPr_AV  : 96|4@1+ (1.000000,0.000000) [0.000000|15.000000] "" Vector__XXX
 SG_ CHA_Ziel_FahrPr_MXB  : 100|4@1+ (1.000000,0.000000) [0.000000|15.000000] "" Vector__XXX
 SG_ CHA_Ziel_FahrPr_AFR  : 104|4@1+ (1.000000,0.000000) [0.000000|15.000000] "" Vector__XXX
 SG_ CHA_Ziel_FahrPr_HDC  : 108|4@1+ (1.000000,0.000000) [0.000000|15.000000] "" Vector__XXX
 SG_ CHA_Ziel_FahrPr_EAR  : 112|4@1+ (1.000000,0.000000) [0.000000|15.000000] "" Vector__XXX
 SG_ CHA_Ziel_FahrPr_AEB  : 116|4@1+ (1.000000,0.000000) [0.000000|15.000000] "" Vector__XXX
 SG_ CHA_Ziel_FahrPr_FCWO  : 120|4@1+ (1.000000,0.000000) [0.000000|15.000000] "" Vector__XXX
 SG_ CHA_Ziel_FahrPr_FCWP  : 124|4@1+ (1.000000,0.000000) [0.000000|15.000000] "" Vector__XXX
 SG_ CHA_Ziel_FahrPr_ToS_laengs  : 144|4@1+ (1.000000,0.000000) [0.000000|15.000000] "" Vector__XXX
 SG_ CHA_Ziel_FahrPr_ToS_quer  : 148|4@1+ (1.000000,0.000000) [0.000000|15.000000] "" Vector__XXX
 SG_ CHA_Ziel_FahrPr_mFDR  : 152|4@1+ (1.000000,0.000000) [0.000000|15.000000] "" Vector__XXX
 SG_ CHA_Ziel_FahrPr_Reku_ZwGas  : 156|4@1+ (1.000000,0.000000) [0.000000|15.000000] "" Vector__XXX
 SG_ CHA_Ziel_FahrPr_MO_Freilauf  : 160|4@1+ (1.000000,0.000000) [0.000000|15.000000] "" Vector__XXX
 SG_ CHA_Ziel_FahrPr_BMS  : 164|4@1+ (1.000000,0.000000) [0.000000|15.000000] "" Vector__XXX
 SG_ CHA_Current_Mode_BMA  : 168|4@1+ (1.000000,0.000000) [0.000000|15.000000] "" Vector__XXX
 SG_ CHA_Ziel_FahrPr_PDC  : 172|4@1+ (1.000000,0.000000) [0.000000|15.000000] "" Vector__XXX
 SG_ CHA_Ziel_FahrPr_HHC  : 176|4@1+ (1.000000,0.000000) [0.000000|15.000000] "" Vector__XXX
 SG_ CHA_Ziel_FahrPr_EDS  : 180|4@1+ (1.000000,0.000000) [0.000000|15.000000] "" Vector__XXX
 SG_ CHA_Ziel_FahrPr_PACC  : 184|4@1+ (1.000000,0.000000) [0.000000|15.000000] "" Vector__XXX
 SG_ CHA_Ziel_FahrPr_AGK  : 188|4@1+ (1.000000,0.000000) [0.000000|15.000000] "" Vector__XXX

BO_ 514 Daempfer_03: 32 ICAS1_Gateway
 SG_ DR_Aufbaubeschleunigung_HR  : 12|10@1+ (0.032700,-15.696000) [-15.696000|15.696000] "Unit_MeterPerSeconSquar" Motor_BEV
 SG_ DR_Aufbaubeschleunigung_VR  : 22|10@1+ (0.032700,-15.696000) [-15.696000|15.696000] "Unit_MeterPerSeconSquar" Motor_BEV
 SG_ DR_Aufbaubeschleunigung_VL  : 32|10@1+ (0.032700,-15.696000) [-15.696000|15.696000] "Unit_MeterPerSeconSquar" Motor_BEV
 SG_ DR_Aufbaubeschleunigung_HL  : 42|10@1+ (0.032700,-15.696000) [-15.696000|15.696000] "Unit_MeterPerSeconSquar" Motor_BEV
 SG_ DR_Funktionsstatus  : 52|2@1+ (1.000000,0.000000) [0.000000|3.000000] "" Vector__XXX
 SG_ DR_Drehwinkelsensortausch_VL  : 72|2@1+ (1.000000,0.000000) [1.000000|3.000000] "" Vector__XXX
 SG_ DR_Drehwinkelsensortausch_VR  : 74|2@1+ (1.000000,0.000000) [1.000000|3.000000] "" Vector__XXX
 SG_ DR_Drehwinkelsensortausch_HL  : 76|2@1+ (1.000000,0.000000) [1.000000|3.000000] "" Vector__XXX
 SG_ DR_Drehwinkelsensortausch_HR  : 78|2@1+ (1.000000,0.000000) [1.000000|3.000000] "" Vector__XXX
 SG_ DR_Drehwinkel_VL  : 80|12@1+ (0.088000,0.000000) [0.000000|359.920000] "" Vector__XXX
 SG_ DR_Drehwinkel_VR  : 92|12@1+ (0.088000,0.000000) [0.000000|359.920000] "" Vector__XXX
 SG_ DR_Drehwinkel_HL  : 104|12@1+ (0.088000,0.000000) [0.000000|359.920000] "" Vector__XXX
 SG_ DR_Drehwinkel_HR  : 116|12@1+ (0.088000,0.000000) [0.000000|359.920000] "" Vector__XXX

BO_ 1485 DCDC_03: 8 ICAS1_Gateway
 SG_ DCDC_03_CRC  : 0|8@1+ (1.000000,0.000000) [0.000000|255.000000] "" Motor_BEV
 SG_ DCDC_03_BZ  : 8|4@1+ (1.000000,0.000000) [0.000000|15.000000] "" Motor_BEV
 SG_ DC_Temperatur_Alarm  : 12|1@1+ (1.000000,0.000000) [0.000000|1.000000] "" Vector__XXX
 SG_ DC_Kl30c_Status  : 14|2@1+ (1.000000,0.000000) [0.000000|3.000000] "" Motor_BEV
 SG_ DC_Fehlerstatus  : 16|3@1+ (1.000000,0.000000) [0.000000|7.000000] "" Vector__XXX
 SG_ DC_Peakstrom_verfuegbar  : 19|1@1+ (1.000000,0.000000) [0.000000|1.000000] "" Vector__XXX
 SG_ DC_Abregelung_Temperatur  : 20|1@1+ (1.000000,0.000000) [0.000000|1.000000] "" Vector__XXX
 SG_ DC_IstModus_02  : 21|3@1+ (1.000000,0.000000) [0.000000|7.000000] "" Vector__XXX
 SG_ DC_Derating  : 24|3@1+ (1.000000,0.000000) [0.000000|7.000000] "" Vector__XXX
 SG_ DC_SollVolumenstrom  : 40|6@1+ (0.500000,0.000000) [0.000000|30.500000] "Unit_LiterPerMinut" Motor_BEV
 SG_ DC_Status_Spgfreiheit_HV  : 46|2@1+ (1.000000,0.000000) [0.000000|3.000000] "" Vector__XXX
 SG_ DC_Temperatur  : 56|8@1+ (1.000000,-40.000000) [-40.000000|213.000000] "Unit_DegreCelsi" Motor_BEV

BO_ 247 DCDC_04: 8 ICAS1_Gateway
 SG_ DCDC_04_CRC  : 0|8@1+ (1.000000,0.000000) [0.000000|255.000000] "" Vector__XXX
 SG_ DCDC_04_BZ  : 8|4@1+ (1.000000,0.000000) [0.000000|15.000000] "" Vector__XXX
 SG_ DC_Vorladung_Status  : 34|1@1+ (1.000000,0.000000) [0.000000|1.000000] "" Motor_BEV
 SG_ DC_Fehler_extern  : 35|1@1+ (1.000000,0.000000) [0.000000|1.000000] "" Motor_BEV
 SG_ DC_Fehler_intern  : 36|1@1+ (1.000000,0.000000) [0.000000|1.000000] "" Motor_BEV
 SG_ DC_Status_Spgfreiheit  : 37|2@1+ (1.000000,0.000000) [0.000000|3.000000] "" Motor_BEV
 SG_ DC_Status_EoHVL  : 39|2@1+ (1.000000,0.000000) [0.000000|3.000000] "" Motor_BEV
 SG_ DC_IstModus_02  : 41|3@1+ (1.000000,0.000000) [0.000000|7.000000] "" Motor_BEV
 SG_ DC_IstStrom_HV  : 44|10@1+ (0.100000,-51.100000) [-51.100000|51.000000] "Unit_Amper" Motor_BEV
 SG_ DC_IstLeistung_HV  : 54|10@1+ (10.000000,-4000.000000) [-4000.000000|6210.000000] "Unit_Watt" Motor_BEV

BO_ 2617027088 DEV_Airbag_ASM_01: 8 Airbag
 SG_ DEV_Airbag_ASM_01_Data  : 0|64@1+ (1.000000,0.000000) [0.000000|18446744073709551616.000000] "" Vector__XXX

BO_ 2617027072 DEV_Airbag_Resp_00: 8 Airbag
 SG_ DEV_Airbag_Resp_00_Data  : 0|64@1+ (1.000000,0.000000) [0.000000|18446744073709551616.000000] "" Vector__XXX

BO_ 2617027073 DEV_Airbag_Resp_01: 8 Airbag
 SG_ DEV_Airbag_Resp_01_Data  : 0|64@1+ (1.000000,0.000000) [0.000000|18446744073709551616.000000] "" Vector__XXX

BO_ 2617027074 DEV_Airbag_Resp_02: 8 Airbag
 SG_ DEV_Airbag_Resp_02_Data  : 0|64@1+ (1.000000,0.000000) [0.000000|18446744073709551616.000000] "" Vector__XXX

BO_ 2617027075 DEV_Airbag_Resp_03: 8 Airbag
 SG_ DEV_Airbag_Resp_03_Data  : 0|64@1+ (1.000000,0.000000) [0.000000|18446744073709551616.000000] "" Vector__XXX

BO_ 2617027076 DEV_Airbag_Resp_04: 8 Airbag
 SG_ DEV_Airbag_Resp_04_Data  : 0|64@1+ (1.000000,0.000000) [0.000000|18446744073709551616.000000] "" Vector__XXX

BO_ 2617027077 DEV_Airbag_Resp_05: 8 Airbag
 SG_ DEV_Airbag_Resp_05_Data  : 0|64@1+ (1.000000,0.000000) [0.000000|18446744073709551616.000000] "" Vector__XXX

BO_ 2617027078 DEV_Airbag_Resp_06: 8 Airbag
 SG_ DEV_Airbag_Resp_06_Data  : 0|64@1+ (1.000000,0.000000) [0.000000|18446744073709551616.000000] "" Vector__XXX

BO_ 2617027079 DEV_Airbag_Resp_07: 8 Airbag
 SG_ DEV_Airbag_Resp_07_Data  : 0|64@1+ (1.000000,0.000000) [0.000000|18446744073709551616.000000] "" Vector__XXX

BO_ 2617027080 DEV_Airbag_Resp_08: 8 Airbag
 SG_ DEV_Airbag_Resp_08_Data  : 0|64@1+ (1.000000,0.000000) [0.000000|18446744073709551616.000000] "" Vector__XXX

BO_ 2617027081 DEV_Airbag_Resp_09: 8 Airbag
 SG_ DEV_Airbag_Resp_09_Data  : 0|64@1+ (1.000000,0.000000) [0.000000|18446744073709551616.000000] "" Vector__XXX

BO_ 2617027082 DEV_Airbag_Resp_10: 8 Airbag
 SG_ DEV_Airbag_Resp_10_Data  : 0|64@1+ (1.000000,0.000000) [0.000000|18446744073709551616.000000] "" Vector__XXX

BO_ 2617027083 DEV_Airbag_Resp_11: 8 Airbag
 SG_ DEV_Airbag_Resp_11_Data  : 0|64@1+ (1.000000,0.000000) [0.000000|18446744073709551616.000000] "" Vector__XXX

BO_ 2617154048 DEV_Waehlhebel_Resp_00: 8 Schaltbetaetigung
 SG_ DEV_Waehlhebel_Resp_00_Data  : 0|64@1+ (1.000000,0.000000) [0.000000|18446744073709551616.000000] "" Vector__XXX

BO_ 2617154049 DEV_Waehlhebel_Resp_01: 8 Schaltbetaetigung
 SG_ DEV_Waehlhebel_Resp_01_Data  : 0|64@1+ (1.000000,0.000000) [0.000000|18446744073709551616.000000] "" Vector__XXX

BO_ 2617154050 DEV_Waehlhebel_Resp_02: 8 Schaltbetaetigung
 SG_ DEV_Waehlhebel_Resp_02_Data  : 0|64@1+ (1.000000,0.000000) [0.000000|18446744073709551616.000000] "" Vector__XXX

BO_ 2617154051 DEV_Waehlhebel_Resp_03: 8 Schaltbetaetigung
 SG_ DEV_Waehlhebel_Resp_03_Data  : 0|64@1+ (1.000000,0.000000) [0.000000|18446744073709551616.000000] "" Vector__XXX

BO_ 2617154052 DEV_Waehlhebel_Resp_04: 8 Schaltbetaetigung
 SG_ DEV_Waehlhebel_Resp_04_Data  : 0|64@1+ (1.000000,0.000000) [0.000000|18446744073709551616.000000] "" Vector__XXX

BO_ 2617154053 DEV_Waehlhebel_Resp_05: 8 Schaltbetaetigung
 SG_ DEV_Waehlhebel_Resp_05_Data  : 0|64@1+ (1.000000,0.000000) [0.000000|18446744073709551616.000000] "" Vector__XXX

BO_ 2549876269 Diag_Waehlhebel_Req: 8 Motor_BEV
 SG_ Diag_Waehlhebel_Req_Data  : 0|64@1+ (1.000000,0.000000) [0.000000|18446744073709551616.000000] "" Schaltbetaetigung

BO_ 2550007341 Diag_Waehlhebel_Resp: 8 Schaltbetaetigung
 SG_ Diag_Waehlhebel_Resp_Data  : 0|64@1+ (1.000000,0.000000) [0.000000|18446744073709551616.000000] "" Motor_BEV

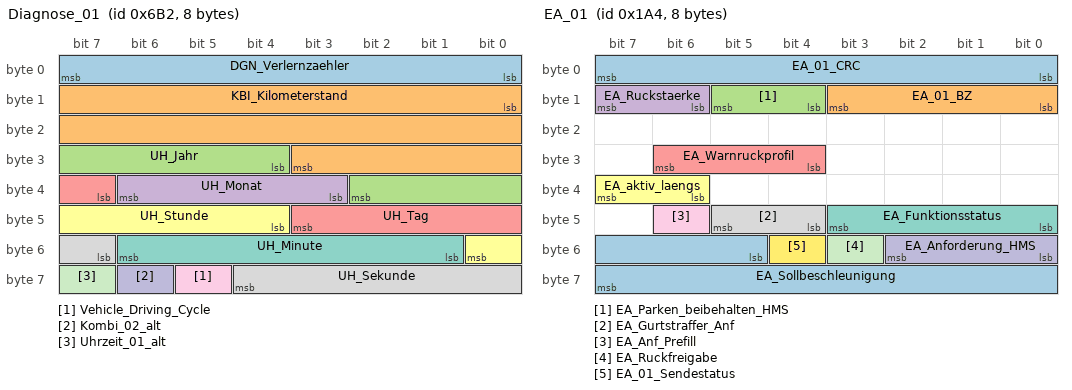
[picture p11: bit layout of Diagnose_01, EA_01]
BO_ 1714 Diagnose_01: 8 ICAS1_Gateway
 SG_ DGN_Verlernzaehler  : 0|8@1+ (1.000000,0.000000) [0.000000|254.000000] "" Airbag LE1 LE2 Motor_BEV
 SG_ KBI_Kilometerstand  : 8|20@1+ (1.000000,0.000000) [0.000000|1048573.000000] "Unit_KiloMeter" Airbag LE1 LE2 Motor_BEV
 SG_ UH_Jahr  : 28|7@1+ (1.000000,2000.000000) [2000.000000|2127.000000] "Unit_Year" Airbag LE1 LE2 Motor_BEV
 SG_ UH_Monat  : 35|4@1+ (1.000000,0.000000) [1.000000|12.000000] "Unit_Month" Airbag LE1 LE2 Motor_BEV
 SG_ UH_Tag  : 39|5@1+ (1.000000,0.000000) [1.000000|31.000000] "Unit_Day" Airbag LE1 LE2 Motor_BEV
 SG_ UH_Stunde  : 44|5@1+ (1.000000,0.000000) [0.000000|23.000000] "Unit_Hours" Airbag LE1 LE2 Motor_BEV
 SG_ UH_Minute  : 49|6@1+ (1.000000,0.000000) [0.000000|59.000000] "Unit_Minut" Airbag LE1 LE2 Motor_BEV
 SG_ UH_Sekunde  : 55|6@1+ (1.000000,0.000000) [0.000000|59.000000] "Unit_Secon" Airbag LE1 LE2 Motor_BEV
 SG_ Vehicle_Driving_Cycle  : 61|1@1+ (1.000000,0.000000) [0.000000|1.000000] "" Airbag
 SG_ Kombi_02_alt  : 62|1@1+ (1.000000,0.000000) [0.000000|1.000000] "" Vector__XXX
 SG_ Uhrzeit_01_alt  : 63|1@1+ (1.000000,0.000000) [0.000000|1.000000] "" Vector__XXX

BO_ 851 DiETa_01: 8 ICAS1_Gateway
 SG_ DiETas_01_CRC  : 0|8@1+ (1.000000,0.000000) [0.000000|255.000000] "" Airbag
 SG_ DiETas_01_BZ  : 8|4@1+ (1.000000,0.000000) [0.000000|15.000000] "" Airbag
 SG_ DiETa_Reserve_Byte2_4  : 12|1@1+ (1.000000,0.000000) [0.000000|1.000000] "" Vector__XXX
 SG_ DiETa_Status  : 13|2@1+ (1.000000,0.000000) [0.000000|3.000000] "" Airbag
 SG_ DiETa_ResponseError  : 15|1@1+ (1.000000,0.000000) [0.000000|1.000000] "" Vector__XXX
 SG_ DiETa_Car  : 16|2@1+ (1.000000,0.000000) [0.000000|3.000000] "" Vector__XXX
 SG_ DiETa_Klima  : 18|2@1+ (1.000000,0.000000) [0.000000|3.000000] "" Vector__XXX
 SG_ DiETa_Mode  : 20|2@1+ (1.000000,0.000000) [0.000000|3.000000] "" Vector__XXX
 SG_ DiETa_Parken  : 22|2@1+ (1.000000,0.000000) [0.000000|3.000000] "" Vector__XXX
 SG_ DiETa_FSH_Taste  : 24|2@1+ (1.000000,0.000000) [0.000000|3.000000] "" Vector__XXX
 SG_ DiETa_HSH_Taste  : 26|2@1+ (1.000000,0.000000) [0.000000|3.000000] "" Vector__XXX
 SG_ DiETa_Warnblink_Taste  : 28|2@1+ (1.000000,0.000000) [0.000000|3.000000] "" Vector__XXX
 SG_ DiETa_FAS_Stufe  : 30|2@1+ (1.000000,0.000000) [0.000000|3.000000] "" Vector__XXX
 SG_ DiETa_PAO_ON_Status  : 32|2@1+ (1.000000,0.000000) [0.000000|3.000000] "" Airbag
 SG_ DiETa_PAO_OFF_Status  : 34|2@1+ (1.000000,0.000000) [0.000000|3.000000] "" Airbag
 SG_ DiETa_Defrost_Taste  : 36|2@1+ (1.000000,0.000000) [0.000000|3.000000] "" Vector__XXX
 SG_ DiETa_Reserve_Byte5_6  : 38|2@1+ (1.000000,0.000000) [0.000000|3.000000] "" Vector__XXX
 SG_ DiETa_Lock_Unlock_Taste  : 40|3@1+ (1.000000,0.000000) [0.000000|7.000000] "" Vector__XXX
 SG_ DiETa_Mode_roh  : 43|1@1+ (1.000000,0.000000) [0.000000|1.000000] "" Vector__XXX
 SG_ DiETa_Reserve_Byte6_3  : 44|4@1+ (1.000000,0.000000) [0.000000|15.000000] "" Vector__XXX
 SG_ DiETa_Reserve_Byte7  : 48|8@1+ (1.000000,0.000000) [0.000000|255.000000] "" Vector__XXX
 SG_ DiETa_Reserve_Byte8  : 56|8@1+ (1.000000,0.000000) [0.000000|255.000000] "" Vector__XXX

BO_ 1520 Dimmung_01: 8 ICAS1_Gateway
 SG_ DI_KL_58xd  : 0|8@1+ (1.000000,0.000000) [0.000000|253.000000] "" Airbag Schaltbetaetigung
 SG_ DI_KL_58xs  : 8|7@1+ (1.000000,0.000000) [0.000000|100.000000] "Unit_PerCent" Airbag
 SG_ DI_Display_Nachtdesign  : 15|1@1+ (1.000000,0.000000) [0.000000|1.000000] "" Vector__XXX
 SG_ DI_KL_58xt  : 16|7@1+ (1.000000,0.000000) [0.000000|100.000000] "Unit_PerCent" Airbag Schaltbetaetigung
 SG_ DI_Fotosensor  : 24|16@1+ (1.000000,0.000000) [0.000000|65535.000000] "" Vector__XXX
 SG_ BCM1_Stellgroesse_Kl_58s  : 40|7@1+ (1.000000,0.000000) [0.000000|100.000000] "" Vector__XXX

BO_ 420 EA_01: 8 ICAS1_Gateway
 SG_ EA_01_CRC  : 0|8@1+ (1.000000,0.000000) [0.000000|255.000000] "" Motor_BEV
 SG_ EA_01_BZ  : 8|4@1+ (1.000000,0.000000) [0.000000|15.000000] "" Motor_BEV
 SG_ EA_Parken_beibehalten_HMS  : 12|2@1+ (1.000000,0.000000) [0.000000|3.000000] "" Vector__XXX
 SG_ EA_Ruckstaerke  : 14|2@1+ (1.000000,0.000000) [0.000000|3.000000] "" Vector__XXX
 SG_ EA_Warnruckprofil  : 28|3@1+ (1.000000,0.000000) [0.000000|7.000000] "" Vector__XXX
 SG_ EA_aktiv_laengs  : 38|2@1+ (1.000000,0.000000) [0.000000|3.000000] "" Motor_BEV
 SG_ EA_Funktionsstatus  : 40|4@1+ (1.000000,0.000000) [0.000000|15.000000] "" Motor_BEV
 SG_ EA_Gurtstraffer_Anf  : 44|2@1+ (1.000000,0.000000) [0.000000|3.000000] "" Airbag
 SG_ EA_Anf_Prefill  : 46|1@1+ (1.000000,0.000000) [0.000000|1.000000] "" Vector__XXX
 SG_ EA_Anforderung_HMS  : 48|3@1+ (1.000000,0.000000) [0.000000|7.000000] "" Vector__XXX
 SG_ EA_Ruckfreigabe  : 51|1@1+ (1.000000,0.000000) [0.000000|1.000000] "" Vector__XXX
 SG_ EA_01_Sendestatus  : 52|1@1+ (1.000000,0.000000) [0.000000|1.000000] "" Vector__XXX
 SG_ EA_Sollbeschleunigung  : 53|11@1+ (0.005000,-7.220000) [-7.220000|3.005000] "Unit_MeterPerSeconSquar" Motor_BEV

BO_ 374 EBKV_03: 8 ICAS1_Gateway
 SG_ EBKV_03_CRC  : 0|8@1+ (1.000000,0.000000) [0.000000|255.000000] "" Vector__XXX
 SG_ EBKV_03_BZ  : 8|4@1+ (1.000000,0.000000) [0.000000|15.000000] "" Vector__XXX
 SG_ EBKV_Activate_Fallback_ESP  : 12|1@1+ (1.000000,0.000000) [0.000000|1.000000] "" Vector__XXX
 SG_ EBKV_Restdruckabsenkung  : 13|3@1+ (1.000000,0.000000) [0.000000|7.000000] "" Vector__XXX
 SG_ EBKV_Status_02  : 16|4@1+ (1.000000,0.000000) [0.000000|15.000000] "" Vector__XXX
 SG_ EBKV_Diagnose  : 20|1@1+ (1.000000,0.000000) [0.000000|1.000000] "" Vector__XXX
 SG_ EBKV_Fahrer_bremst  : 21|1@1+ (1.000000,0.000000) [0.000000|1.000000] "" Motor_BEV
 SG_ EBKV_QBit_Fahrer_bremst  : 22|1@1+ (1.000000,0.000000) [0.000000|1.000000] "" Motor_BEV
 SG_ EBKV_Fahrer_bremst_deutlich  : 23|1@1+ (1.000000,0.000000) [0.000000|1.000000] "" Vector__XXX
 SG_ EBKV_OBD_Status  : 24|1@1+ (1.000000,0.000000) [0.000000|1.000000] "" Motor_BEV
 SG_ EBKV_VMM_Sek_Notstopp_Status  : 25|3@1+ (1.000000,0.000000) [0.000000|7.000000] "" Vector__XXX
 SG_ EBKV_Anforderung_HMS  : 28|3@1+ (1.000000,0.000000) [0.000000|7.000000] "" Vector__XXX
 SG_ SBS_Anforderung_GE  : 31|1@1+ (1.000000,0.000000) [0.000000|1.000000] "" Vector__XXX
 SG_ EPB_Status_ext  : 32|3@1+ (1.000000,0.000000) [0.000000|7.000000] "" Motor_BEV
 SG_ EBKV_Bremspedalweg  : 40|8@1+ (0.400000,-0.400000) [0.000000|101.200000] "Unit_PerCent" Motor_BEV
 SG_ EBKV_Kraftblending_Reserve  : 48|8@1+ (0.500000,0.000000) [0.000000|125.000000] "Unit_Bar" Vector__XXX
 SG_ EBKV_Aussteuerdruck  : 56|8@1+ (1.000000,0.000000) [0.000000|250.000000] "Unit_Bar" Vector__XXX

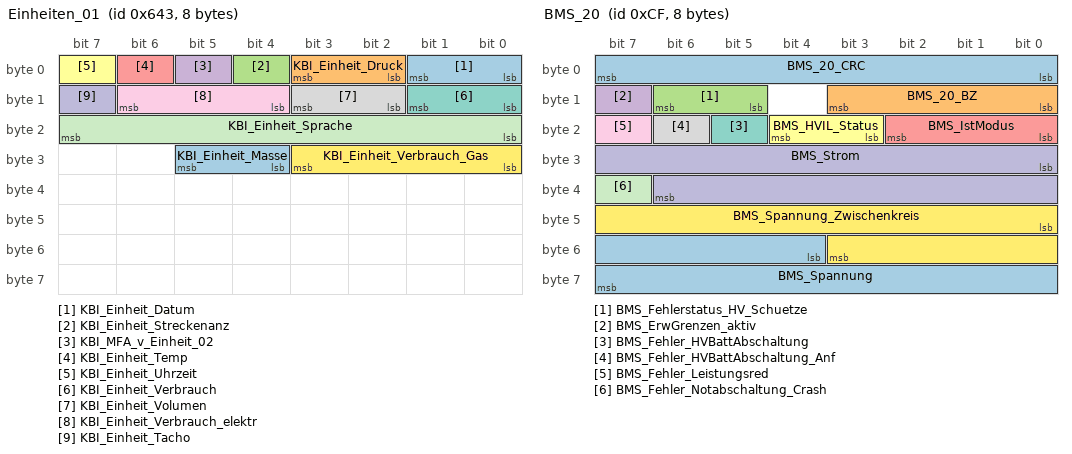
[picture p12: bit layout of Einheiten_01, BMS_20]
BO_ 1603 Einheiten_01: 8 ICAS1_KommunikationsServer
 SG_ KBI_Einheit_Datum  : 0|2@1+ (1.000000,0.000000) [0.000000|3.000000] "" Vector__XXX
 SG_ KBI_Einheit_Druck  : 2|2@1+ (1.000000,0.000000) [0.000000|3.000000] "" Vector__XXX
 SG_ KBI_Einheit_Streckenanz  : 4|1@1+ (1.000000,0.000000) [0.000000|1.000000] "" Vector__XXX
 SG_ KBI_MFA_v_Einheit_02  : 5|1@1+ (1.000000,0.000000) [0.000000|1.000000] "" Motor_BEV
 SG_ KBI_Einheit_Temp  : 6|1@1+ (1.000000,0.000000) [0.000000|1.000000] "" Vector__XXX
 SG_ KBI_Einheit_Uhrzeit  : 7|1@1+ (1.000000,0.000000) [0.000000|1.000000] "" Vector__XXX
 SG_ KBI_Einheit_Verbrauch  : 8|2@1+ (1.000000,0.000000) [0.000000|3.000000] "" Vector__XXX
 SG_ KBI_Einheit_Volumen  : 10|2@1+ (1.000000,0.000000) [0.000000|3.000000] "" Vector__XXX
 SG_ KBI_Einheit_Verbrauch_elektr  : 12|3@1+ (1.000000,0.000000) [0.000000|7.000000] "" Vector__XXX
 SG_ KBI_Einheit_Tacho  : 15|1@1+ (1.000000,0.000000) [0.000000|1.000000] "" Motor_BEV
 SG_ KBI_Einheit_Sprache  : 16|8@1+ (1.000000,0.000000) [0.000000|255.000000] "" Vector__XXX
 SG_ KBI_Einheit_Verbrauch_Gas  : 24|4@1+ (1.000000,0.000000) [0.000000|15.000000] "" Vector__XXX
 SG_ KBI_Einheit_Masse  : 28|2@1+ (1.000000,0.000000) [0.000000|3.000000] "" Vector__XXX

BU_:  Airbag BAP_Tester ICAS1_Gateway ICAS1_KommunikationsServer LE1 LE2 Motor_BEV Schaltbetaetigung

BO_ 207 BMS_20: 8 ICAS1_Gateway
 SG_ BMS_20_CRC  : 0|8@1+ (1.000000,0.000000) [0.000000|255.000000] "" Motor_BEV
 SG_ BMS_20_BZ  : 8|4@1+ (1.000000,0.000000) [0.000000|15.000000] "" Motor_BEV
 SG_ BMS_Fehlerstatus_HV_Schuetze  : 13|2@1+ (1.000000,0.000000) [0.000000|3.000000] "" Motor_BEV
 SG_ BMS_ErwGrenzen_aktiv  : 15|1@1+ (1.000000,0.000000) [0.000000|1.000000] "" Motor_BEV
 SG_ BMS_IstModus  : 16|3@1+ (1.000000,0.000000) [0.000000|7.000000] "" LE1 LE2 Motor_BEV
 SG_ BMS_HVIL_Status  : 19|2@1+ (1.000000,0.000000) [0.000000|3.000000] "" Motor_BEV
 SG_ BMS_Fehler_HVBattAbschaltung  : 21|1@1+ (1.000000,0.000000) [0.000000|1.000000] "" Motor_BEV
 SG_ BMS_Fehler_HVBattAbschaltung_Anf  : 22|1@1+ (1.000000,0.000000) [0.000000|1.000000] "" Motor_BEV
 SG_ BMS_Fehler_Leistungsred  : 23|1@1+ (1.000000,0.000000) [0.000000|1.000000] "" Motor_BEV
 SG_ BMS_Strom  : 24|15@1+ (0.100000,-1630.000000) [-1630.000000|1630.000000] "Unit_Amper" Motor_BEV
 SG_ BMS_Fehler_Notabschaltung_Crash  : 39|1@1+ (1.000000,0.000000) [0.000000|1.000000] "" Vector__XXX
 SG_ BMS_Spannung_Zwischenkreis  : 40|12@1+ (0.500000,-1000.000000) [-1000.000000|1000.000000] "Unit_Volt" Motor_BEV
 SG_ BMS_Spannung  : 52|12@1+ (0.250000,0.000000) [0.000000|1000.000000] "Unit_Volt" Motor_BEV

BO_ 2463978704 BMS_21: 8 ICAS1_Gateway
 SG_ BMS_Max_Entladestrom  : 12|13@1+ (0.200000,0.000000) [0.000000|1630.000000] "Unit_Amper" Motor_BEV
 SG_ BMS_Max_Ladestrom  : 25|13@1+ (0.200000,0.000000) [0.000000|1630.000000] "Unit_Amper" Motor_BEV
 SG_ BMS_Max_Entladeleistung  : 38|13@1+ (100.000000,0.000000) [0.000000|818000.000000] "Unit_Watt" Motor_BEV
 SG_ BMS_Max_Ladeleistung  : 51|13@1+ (100.000000,0.000000) [0.000000|818000.000000] "Unit_Watt" Motor_BEV

BO_ 2463978705 BMS_22: 8 ICAS1_Gateway
 SG_ BMS_Status_EoHVL_Heizer  : 15|2@1+ (1.000000,0.000000) [0.000000|3.000000] "" Motor_BEV
 SG_ BMS_Ladezustand  : 17|11@1+ (0.050000,0.000000) [0.000000|100.000000] "Unit_PerCent" Motor_BEV
 SG_ BMS_PerfInd_Entladen  : 28|10@1+ (0.200000,0.000000) [0.000000|200.000000] "Unit_PerCent" Motor_BEV
 SG_ BMS_PerfInd_Laden  : 38|10@1+ (0.200000,0.000000) [0.000000|200.000000] "Unit_PerCent" Motor_BEV
 SG_ BMS_Nutzbare_EntladeEnergie  : 48|16@1+ (5.000000,0.000000) [0.000000|327400.000000] "Unit_WattHour" Motor_BEV

BO_ 2589283664 BMS_24: 8 ICAS1_Gateway
 SG_ BMS_Balancing_Aktiv  : 14|2@1+ (1.000000,0.000000) [0.000000|3.000000] "" Vector__XXX
 SG_ BMS_Ladevorgang_aktiv  : 16|1@1+ (1.000000,0.000000) [0.000000|1.000000] "" Vector__XXX
 SG_ BMS_RIso_Ext  : 17|12@1+ (5.000000,0.000000) [0.000000|20465.000000] "Unit_KiloOhm" Motor_BEV
 SG_ BMS_Min_Ladezustand  : 29|11@1+ (0.050000,0.000000) [0.000000|100.000000] "Unit_PerCent" Motor_BEV
 SG_ BMS_Max_Energie  : 40|13@1+ (40.000000,0.000000) [0.000000|327400.000000] "Unit_WattHour" Motor_BEV
 SG_ BMS_Max_Ladezustand  : 53|11@1+ (0.050000,0.000000) [0.000000|100.000000] "Unit_PerCent" Motor_BEV

BO_ 2589283665 BMS_25: 8 ICAS1_Gateway
 SG_ BMS_BattHeizung_VerbautStatus  : 13|1@1+ (1.000000,0.000000) [0.000000|1.000000] "" Motor_BEV
 SG_ BMS_Fehler_NTKreis  : 14|1@1+ (1.000000,0.000000) [0.000000|1.000000] "" Vector__XXX
 SG_ BMS_Temperierung_Anf  : 15|3@1+ (1.000000,0.000000) [0.000000|7.000000] "" Motor_BEV
 SG_ BMS_Status_Ventil1  : 18|3@1+ (1.000000,0.000000) [0.000000|7.000000] "" Motor_BEV
 SG_ BMS_Status_Ventil2  : 21|3@1+ (1.000000,0.000000) [0.000000|7.000000] "" Motor_BEV
 SG_ BMS_Pumpe1_Ansteuerung  : 24|4@1+ (10.000000,0.000000) [0.000000|100.000000] "Unit_PerCent" Motor_BEV
 SG_ BMS_Pumpe2_Ansteuerung  : 28|4@1+ (10.000000,0.000000) [0.000000|100.000000] "Unit_PerCent" Motor_BEV
 SG_ BMS_VorlaufTemperatur  : 32|8@1+ (0.500000,-40.000000) [-40.000000|86.000000] "Unit_DegreCelsi" Motor_BEV
 SG_ BMS_Temperatur  : 40|8@1+ (0.500000,-40.000000) [-40.000000|86.500000] "Unit_DegreCelsi" Motor_BEV
 SG_ BMS_SollVorlauftemperatur  : 48|8@1+ (0.500000,-40.000000) [-40.000000|86.500000] "Unit_DegreCelsi" Motor_BEV
 SG_ BMS_RuecklaufTemperatur  : 56|8@1+ (0.500000,-40.000000) [-40.000000|86.000000] "Unit_DegreCelsi" Motor_BEV

BO_ 2589283760 BMS_26: 8 ICAS1_Gateway
 SG_ BMS_Max_Spannung  : 20|10@1+ (1.000000,0.000000) [0.000000|1000.000000] "Unit_Volt" Motor_BEV
 SG_ BMS_Min_Spannung  : 30|10@1+ (1.000000,0.000000) [0.000000|1000.000000] "Unit_Volt" Motor_BEV
 SG_ BMS_Dauer_Entladeleistung  : 40|12@1+ (200.000000,0.000000) [0.000000|818000.000000] "Unit_Watt" Motor_BEV
 SG_ BMS_Dauer_Ladeleistung  : 52|12@1+ (200.000000,0.000000) [0.000000|818000.000000] "Unit_Watt" Motor_BEV

BO_ 2463978646 Charisma_11: 24 ICAS1_Gateway
 SG_ CHA_Ziel_FahrPr_AGA  : 0|4@1+ (1.000000,0.000000) [0.000000|15.000000] "" Vector__XXX
 SG_ CHA_Ziel_FahrPr_ESP  : 4|4@1+ (1.000000,0.000000) [0.000000|15.000000] "" Motor_BEV
 SG_ CHA_Ziel_FahrPr_Freilauf  : 8|4@1+ (1.000000,0.000000) [0.000000|15.000000] "" Vector__XXX
 SG_ CHA_Fahrer_Umschaltung  : 14|1@1+ (1.000000,0.000000) [0.000000|1.000000] "" Motor_BEV
 SG_ CHA_Fahrer_Umschaltung_BMA  : 15|1@1+ (1.000000,0.000000) [0.000000|1.000000] "" Vector__XXX
 SG_ CHA_Ziel_FahrPr_MO  : 16|4@1+ (1.000000,0.000000) [0.000000|15.000000] "" Motor_BEV
 SG_ CHA_Ziel_FahrPr_GE  : 20|4@1+ (1.000000,0.000000) [0.000000|15.000000] "" Vector__XXX
 SG_ CHA_Ziel_FahrPr_ALR  : 24|4@1+ (1.000000,0.000000) [0.000000|15.000000] "" Motor_BEV
 SG_ CHA_Ziel_FahrPr_MO_BZS  : 28|4@1+ (1.000000,0.000000) [0.000000|15.000000] "" Vector__XXX
 SG_ CHA_Ziel_FahrPr_DR  : 32|4@1+ (1.000000,0.000000) [0.000000|15.000000] "" Vector__XXX
 SG_ CHA_Ziel_FahrPr_VAQ  : 36|4@1+ (1.000000,0.000000) [0.000000|15.000000] "" Vector__XXX
 SG_ CHA_Ziel_FahrPr_AFS  : 40|4@1+ (1.000000,0.000000) [0.000000|15.000000] "" Vector__XXX
 SG_ CHA_Ziel_FahrPr_PreCrash  : 44|4@1+ (1.000000,0.000000) [0.000000|15.000000] "" Airbag
 SG_ CHA_Ziel_FahrPr_EPS  : 48|4@1+ (1.000000,0.000000) [0.000000|15.000000] "" Vector__XXX
 SG_ CHA_Ziel_FahrPr_ACC  : 52|4@1+ (1.000000,0.000000) [0.000000|15.000000] "" Vector__XXX
 SG_ CHA_Ziel_FahrPr_SAK  : 56|4@1+ (1.000000,0.000000) [0.000000|15.000000] "" Vector__XXX
 SG_ CHA_Ziel_FahrPr_MO_StSt  : 60|4@1+ (1.000000,0.000000) [0.000000|15.000000] "" Vector__XXX
 SG_ CHA_Ziel_FahrPr_EBKV  : 64|4@1+ (1.000000,0.000000) [0.000000|15.000000] "" Vector__XXX
 SG_ CHA_Ziel_FahrPr_IL  : 68|4@1+ (1.000000,0.000000) [0.000000|15.000000] "" Vector__XXX
 SG_ CHA_Current_Mode  : 72|4@1+ (1.000000,0.000000) [0.000000|15.000000] "" Vector__XXX
 SG_ CHA_Ziel_FahrPr_QS  : 80|4@1+ (1.000000,0.000000) [0.000000|15.000000] "" Vector__XXX
 SG_ CHA_Ziel_FahrPr_SCU  : 84|4@1+ (1.000000,0.000000) [0.000000|15.000000] "" Vector__XXX
 SG_ CHA_Ziel_FahrPr_HAL  : 88|4@1+ (1.000000,0.000000) [0.000000|15.000000] "" Vector__XXX
 SG_ CHA_Ziel_FahrPr_NR  : 92|4@1+ (1.000000,0.000000) [0.000000|15.000000] "" Vector__XXX
 SG_ CHA_Ziel_FahrPr_AV  : 96|4@1+ (1.000000,0.000000) [0.000000|15.000000] "" Vector__XXX
 SG_ CHA_Ziel_FahrPr_MXB  : 100|4@1+ (1.000000,0.000000) [0.000000|15.000000] "" Vector__XXX
 SG_ CHA_Ziel_FahrPr_AFR  : 104|4@1+ (1.000000,0.000000) [0.000000|15.000000] "" Vector__XXX
 SG_ CHA_Ziel_FahrPr_HDC  : 108|4@1+ (1.000000,0.000000) [0.000000|15.000000] "" Vector__XXX
 SG_ CHA_Ziel_FahrPr_EAR  : 112|4@1+ (1.000000,0.000000) [0.000000|15.000000] "" Vector__XXX
 SG_ CHA_Ziel_FahrPr_AEB  : 116|4@1+ (1.000000,0.000000) [0.000000|15.000000] "" Vector__XXX
 SG_ CHA_Ziel_FahrPr_FCWO  : 120|4@1+ (1.000000,0.000000) [0.000000|15.000000] "" Vector__XXX
 SG_ CHA_Ziel_FahrPr_FCWP  : 124|4@1+ (1.000000,0.000000) [0.000000|15.000000] "" Vector__XXX
 SG_ CHA_Ziel_FahrPr_ToS_laengs  : 144|4@1+ (1.000000,0.000000) [0.000000|15.000000] "" Vector__XXX
 SG_ CHA_Ziel_FahrPr_ToS_quer  : 148|4@1+ (1.000000,0.000000) [0.000000|15.000000] "" Vector__XXX
 SG_ CHA_Ziel_FahrPr_mFDR  : 152|4@1+ (1.000000,0.000000) [0.000000|15.000000] "" Vector__XXX
 SG_ CHA_Ziel_FahrPr_Reku_ZwGas  : 156|4@1+ (1.000000,0.000000) [0.000000|15.000000] "" Vector__XXX
 SG_ CHA_Ziel_FahrPr_MO_Freilauf  : 160|4@1+ (1.000000,0.000000) [0.000000|15.000000] "" Vector__XXX
 SG_ CHA_Ziel_FahrPr_BMS  : 164|4@1+ (1.000000,0.000000) [0.000000|15.000000] "" Vector__XXX
 SG_ CHA_Current_Mode_BMA  : 168|4@1+ (1.000000,0.000000) [0.000000|15.000000] "" Vector__XXX
 SG_ CHA_Ziel_FahrPr_PDC  : 172|4@1+ (1.000000,0.000000) [0.000000|15.000000] "" Vector__XXX
 SG_ CHA_Ziel_FahrPr_HHC  : 176|4@1+ (1.000000,0.000000) [0.000000|15.000000] "" Vector__XXX
 SG_ CHA_Ziel_FahrPr_EDS  : 180|4@1+ (1.000000,0.000000) [0.000000|15.000000] "" Vector__XXX
 SG_ CHA_Ziel_FahrPr_PACC  : 184|4@1+ (1.000000,0.000000) [0.000000|15.000000] "" Vector__XXX
 SG_ CHA_Ziel_FahrPr_AGK  : 188|4@1+ (1.000000,0.000000) [0.000000|15.000000] "" Vector__XXX

BO_ 514 Daempfer_03: 32 ICAS1_Gateway
 SG_ DR_Aufbaubeschleunigung_HR  : 12|10@1+ (0.032700,-15.696000) [-15.696000|15.696000] "Unit_MeterPerSeconSquar" Motor_BEV
 SG_ DR_Aufbaubeschleunigung_VR  : 22|10@1+ (0.032700,-15.696000) [-15.696000|15.696000] "Unit_MeterPerSeconSquar" Motor_BEV
 SG_ DR_Aufbaubeschleunigung_VL  : 32|10@1+ (0.032700,-15.696000) [-15.696000|15.696000] "Unit_MeterPerSeconSquar" Motor_BEV
 SG_ DR_Aufbaubeschleunigung_HL  : 42|10@1+ (0.032700,-15.696000) [-15.696000|15.696000] "Unit_MeterPerSeconSquar" Motor_BEV
 SG_ DR_Funktionsstatus  : 52|2@1+ (1.000000,0.000000) [0.000000|3.000000] "" Vector__XXX
 SG_ DR_Drehwinkelsensortausch_VL  : 72|2@1+ (1.000000,0.000000) [1.000000|3.000000] "" Vector__XXX
 SG_ DR_Drehwinkelsensortausch_VR  : 74|2@1+ (1.000000,0.000000) [1.000000|3.000000] "" Vector__XXX
 SG_ DR_Drehwinkelsensortausch_HL  : 76|2@1+ (1.000000,0.000000) [1.000000|3.000000] "" Vector__XXX
 SG_ DR_Drehwinkelsensortausch_HR  : 78|2@1+ (1.000000,0.000000) [1.000000|3.000000] "" Vector__XXX
 SG_ DR_Drehwinkel_VL  : 80|12@1+ (0.088000,0.000000) [0.000000|359.920000] "" Vector__XXX
 SG_ DR_Drehwinkel_VR  : 92|12@1+ (0.088000,0.000000) [0.000000|359.920000] "" Vector__XXX
 SG_ DR_Drehwinkel_HL  : 104|12@1+ (0.088000,0.000000) [0.000000|359.920000] "" Vector__XXX
 SG_ DR_Drehwinkel_HR  : 116|12@1+ (0.088000,0.000000) [0.000000|359.920000] "" Vector__XXX

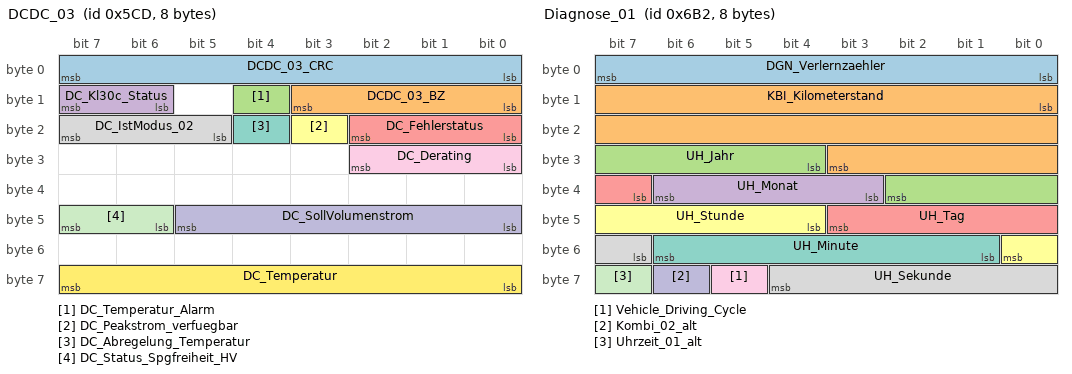
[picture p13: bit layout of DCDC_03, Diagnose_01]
BO_ 1485 DCDC_03: 8 ICAS1_Gateway
 SG_ DCDC_03_CRC  : 0|8@1+ (1.000000,0.000000) [0.000000|255.000000] "" Motor_BEV
 SG_ DCDC_03_BZ  : 8|4@1+ (1.000000,0.000000) [0.000000|15.000000] "" Motor_BEV
 SG_ DC_Temperatur_Alarm  : 12|1@1+ (1.000000,0.000000) [0.000000|1.000000] "" Vector__XXX
 SG_ DC_Kl30c_Status  : 14|2@1+ (1.000000,0.000000) [0.000000|3.000000] "" Motor_BEV
 SG_ DC_Fehlerstatus  : 16|3@1+ (1.000000,0.000000) [0.000000|7.000000] "" Vector__XXX
 SG_ DC_Peakstrom_verfuegbar  : 19|1@1+ (1.000000,0.000000) [0.000000|1.000000] "" Vector__XXX
 SG_ DC_Abregelung_Temperatur  : 20|1@1+ (1.000000,0.000000) [0.000000|1.000000] "" Vector__XXX
 SG_ DC_IstModus_02  : 21|3@1+ (1.000000,0.000000) [0.000000|7.000000] "" Vector__XXX
 SG_ DC_Derating  : 24|3@1+ (1.000000,0.000000) [0.000000|7.000000] "" Vector__XXX
 SG_ DC_SollVolumenstrom  : 40|6@1+ (0.500000,0.000000) [0.000000|30.500000] "Unit_LiterPerMinut" Motor_BEV
 SG_ DC_Status_Spgfreiheit_HV  : 46|2@1+ (1.000000,0.000000) [0.000000|3.000000] "" Vector__XXX
 SG_ DC_Temperatur  : 56|8@1+ (1.000000,-40.000000) [-40.000000|213.000000] "Unit_DegreCelsi" Motor_BEV

BO_ 247 DCDC_04: 8 ICAS1_Gateway
 SG_ DCDC_04_CRC  : 0|8@1+ (1.000000,0.000000) [0.000000|255.000000] "" Vector__XXX
 SG_ DCDC_04_BZ  : 8|4@1+ (1.000000,0.000000) [0.000000|15.000000] "" Vector__XXX
 SG_ DC_Vorladung_Status  : 34|1@1+ (1.000000,0.000000) [0.000000|1.000000] "" Motor_BEV
 SG_ DC_Fehler_extern  : 35|1@1+ (1.000000,0.000000) [0.000000|1.000000] "" Motor_BEV
 SG_ DC_Fehler_intern  : 36|1@1+ (1.000000,0.000000) [0.000000|1.000000] "" Motor_BEV
 SG_ DC_Status_Spgfreiheit  : 37|2@1+ (1.000000,0.000000) [0.000000|3.000000] "" Motor_BEV
 SG_ DC_Status_EoHVL  : 39|2@1+ (1.000000,0.000000) [0.000000|3.000000] "" Motor_BEV
 SG_ DC_IstModus_02  : 41|3@1+ (1.000000,0.000000) [0.000000|7.000000] "" Motor_BEV
 SG_ DC_IstStrom_HV  : 44|10@1+ (0.100000,-51.100000) [-51.100000|51.000000] "Unit_Amper" Motor_BEV
 SG_ DC_IstLeistung_HV  : 54|10@1+ (10.000000,-4000.000000) [-4000.000000|6210.000000] "Unit_Watt" Motor_BEV

BO_ 2617027088 DEV_Airbag_ASM_01: 8 Airbag
 SG_ DEV_Airbag_ASM_01_Data  : 0|64@1+ (1.000000,0.000000) [0.000000|18446744073709551616.000000] "" Vector__XXX

BO_ 2617027072 DEV_Airbag_Resp_00: 8 Airbag
 SG_ DEV_Airbag_Resp_00_Data  : 0|64@1+ (1.000000,0.000000) [0.000000|18446744073709551616.000000] "" Vector__XXX

BO_ 2617027073 DEV_Airbag_Resp_01: 8 Airbag
 SG_ DEV_Airbag_Resp_01_Data  : 0|64@1+ (1.000000,0.000000) [0.000000|18446744073709551616.000000] "" Vector__XXX

BO_ 2617027074 DEV_Airbag_Resp_02: 8 Airbag
 SG_ DEV_Airbag_Resp_02_Data  : 0|64@1+ (1.000000,0.000000) [0.000000|18446744073709551616.000000] "" Vector__XXX

BO_ 2617027075 DEV_Airbag_Resp_03: 8 Airbag
 SG_ DEV_Airbag_Resp_03_Data  : 0|64@1+ (1.000000,0.000000) [0.000000|18446744073709551616.000000] "" Vector__XXX

BO_ 2617027076 DEV_Airbag_Resp_04: 8 Airbag
 SG_ DEV_Airbag_Resp_04_Data  : 0|64@1+ (1.000000,0.000000) [0.000000|18446744073709551616.000000] "" Vector__XXX

BO_ 2617027077 DEV_Airbag_Resp_05: 8 Airbag
 SG_ DEV_Airbag_Resp_05_Data  : 0|64@1+ (1.000000,0.000000) [0.000000|18446744073709551616.000000] "" Vector__XXX

BO_ 2617027078 DEV_Airbag_Resp_06: 8 Airbag
 SG_ DEV_Airbag_Resp_06_Data  : 0|64@1+ (1.000000,0.000000) [0.000000|18446744073709551616.000000] "" Vector__XXX

BO_ 2617027079 DEV_Airbag_Resp_07: 8 Airbag
 SG_ DEV_Airbag_Resp_07_Data  : 0|64@1+ (1.000000,0.000000) [0.000000|18446744073709551616.000000] "" Vector__XXX

BO_ 2617027080 DEV_Airbag_Resp_08: 8 Airbag
 SG_ DEV_Airbag_Resp_08_Data  : 0|64@1+ (1.000000,0.000000) [0.000000|18446744073709551616.000000] "" Vector__XXX

BO_ 2617027081 DEV_Airbag_Resp_09: 8 Airbag
 SG_ DEV_Airbag_Resp_09_Data  : 0|64@1+ (1.000000,0.000000) [0.000000|18446744073709551616.000000] "" Vector__XXX

BO_ 2617027082 DEV_Airbag_Resp_10: 8 Airbag
 SG_ DEV_Airbag_Resp_10_Data  : 0|64@1+ (1.000000,0.000000) [0.000000|18446744073709551616.000000] "" Vector__XXX

BO_ 2617027083 DEV_Airbag_Resp_11: 8 Airbag
 SG_ DEV_Airbag_Resp_11_Data  : 0|64@1+ (1.000000,0.000000) [0.000000|18446744073709551616.000000] "" Vector__XXX

BO_ 2617154048 DEV_Waehlhebel_Resp_00: 8 Schaltbetaetigung
 SG_ DEV_Waehlhebel_Resp_00_Data  : 0|64@1+ (1.000000,0.000000) [0.000000|18446744073709551616.000000] "" Vector__XXX

BO_ 2617154049 DEV_Waehlhebel_Resp_01: 8 Schaltbetaetigung
 SG_ DEV_Waehlhebel_Resp_01_Data  : 0|64@1+ (1.000000,0.000000) [0.000000|18446744073709551616.000000] "" Vector__XXX

BO_ 2617154050 DEV_Waehlhebel_Resp_02: 8 Schaltbetaetigung
 SG_ DEV_Waehlhebel_Resp_02_Data  : 0|64@1+ (1.000000,0.000000) [0.000000|18446744073709551616.000000] "" Vector__XXX

BO_ 2617154051 DEV_Waehlhebel_Resp_03: 8 Schaltbetaetigung
 SG_ DEV_Waehlhebel_Resp_03_Data  : 0|64@1+ (1.000000,0.000000) [0.000000|18446744073709551616.000000] "" Vector__XXX

BO_ 2617154052 DEV_Waehlhebel_Resp_04: 8 Schaltbetaetigung
 SG_ DEV_Waehlhebel_Resp_04_Data  : 0|64@1+ (1.000000,0.000000) [0.000000|18446744073709551616.000000] "" Vector__XXX

BO_ 2617154053 DEV_Waehlhebel_Resp_05: 8 Schaltbetaetigung
 SG_ DEV_Waehlhebel_Resp_05_Data  : 0|64@1+ (1.000000,0.000000) [0.000000|18446744073709551616.000000] "" Vector__XXX

BO_ 2549876269 Diag_Waehlhebel_Req: 8 Motor_BEV
 SG_ Diag_Waehlhebel_Req_Data  : 0|64@1+ (1.000000,0.000000) [0.000000|18446744073709551616.000000] "" Schaltbetaetigung

BO_ 2550007341 Diag_Waehlhebel_Resp: 8 Schaltbetaetigung
 SG_ Diag_Waehlhebel_Resp_Data  : 0|64@1+ (1.000000,0.000000) [0.000000|18446744073709551616.000000] "" Motor_BEV

BO_ 1714 Diagnose_01: 8 ICAS1_Gateway
 SG_ DGN_Verlernzaehler  : 0|8@1+ (1.000000,0.000000) [0.000000|254.000000] "" Airbag LE1 LE2 Motor_BEV
 SG_ KBI_Kilometerstand  : 8|20@1+ (1.000000,0.000000) [0.000000|1048573.000000] "Unit_KiloMeter" Airbag LE1 LE2 Motor_BEV
 SG_ UH_Jahr  : 28|7@1+ (1.000000,2000.000000) [2000.000000|2127.000000] "Unit_Year" Airbag LE1 LE2 Motor_BEV
 SG_ UH_Monat  : 35|4@1+ (1.000000,0.000000) [1.000000|12.000000] "Unit_Month" Airbag LE1 LE2 Motor_BEV
 SG_ UH_Tag  : 39|5@1+ (1.000000,0.000000) [1.000000|31.000000] "Unit_Day" Airbag LE1 LE2 Motor_BEV
 SG_ UH_Stunde  : 44|5@1+ (1.000000,0.000000) [0.000000|23.000000] "Unit_Hours" Airbag LE1 LE2 Motor_BEV
 SG_ UH_Minute  : 49|6@1+ (1.000000,0.000000) [0.000000|59.000000] "Unit_Minut" Airbag LE1 LE2 Motor_BEV
 SG_ UH_Sekunde  : 55|6@1+ (1.000000,0.000000) [0.000000|59.000000] "Unit_Secon" Airbag LE1 LE2 Motor_BEV
 SG_ Vehicle_Driving_Cycle  : 61|1@1+ (1.000000,0.000000) [0.000000|1.000000] "" Airbag
 SG_ Kombi_02_alt  : 62|1@1+ (1.000000,0.000000) [0.000000|1.000000] "" Vector__XXX
 SG_ Uhrzeit_01_alt  : 63|1@1+ (1.000000,0.000000) [0.000000|1.000000] "" Vector__XXX

BO_ 851 DiETa_01: 8 ICAS1_Gateway
 SG_ DiETas_01_CRC  : 0|8@1+ (1.000000,0.000000) [0.000000|255.000000] "" Airbag
 SG_ DiETas_01_BZ  : 8|4@1+ (1.000000,0.000000) [0.000000|15.000000] "" Airbag
 SG_ DiETa_Reserve_Byte2_4  : 12|1@1+ (1.000000,0.000000) [0.000000|1.000000] "" Vector__XXX
 SG_ DiETa_Status  : 13|2@1+ (1.000000,0.000000) [0.000000|3.000000] "" Airbag
 SG_ DiETa_ResponseError  : 15|1@1+ (1.000000,0.000000) [0.000000|1.000000] "" Vector__XXX
 SG_ DiETa_Car  : 16|2@1+ (1.000000,0.000000) [0.000000|3.000000] "" Vector__XXX
 SG_ DiETa_Klima  : 18|2@1+ (1.000000,0.000000) [0.000000|3.000000] "" Vector__XXX
 SG_ DiETa_Mode  : 20|2@1+ (1.000000,0.000000) [0.000000|3.000000] "" Vector__XXX
 SG_ DiETa_Parken  : 22|2@1+ (1.000000,0.000000) [0.000000|3.000000] "" Vector__XXX
 SG_ DiETa_FSH_Taste  : 24|2@1+ (1.000000,0.000000) [0.000000|3.000000] "" Vector__XXX
 SG_ DiETa_HSH_Taste  : 26|2@1+ (1.000000,0.000000) [0.000000|3.000000] "" Vector__XXX
 SG_ DiETa_Warnblink_Taste  : 28|2@1+ (1.000000,0.000000) [0.000000|3.000000] "" Vector__XXX
 SG_ DiETa_FAS_Stufe  : 30|2@1+ (1.000000,0.000000) [0.000000|3.000000] "" Vector__XXX
 SG_ DiETa_PAO_ON_Status  : 32|2@1+ (1.000000,0.000000) [0.000000|3.000000] "" Airbag
 SG_ DiETa_PAO_OFF_Status  : 34|2@1+ (1.000000,0.000000) [0.000000|3.000000] "" Airbag
 SG_ DiETa_Defrost_Taste  : 36|2@1+ (1.000000,0.000000) [0.000000|3.000000] "" Vector__XXX
 SG_ DiETa_Reserve_Byte5_6  : 38|2@1+ (1.000000,0.000000) [0.000000|3.000000] "" Vector__XXX
 SG_ DiETa_Lock_Unlock_Taste  : 40|3@1+ (1.000000,0.000000) [0.000000|7.000000] "" Vector__XXX
 SG_ DiETa_Mode_roh  : 43|1@1+ (1.000000,0.000000) [0.000000|1.000000] "" Vector__XXX
 SG_ DiETa_Reserve_Byte6_3  : 44|4@1+ (1.000000,0.000000) [0.000000|15.000000] "" Vector__XXX
 SG_ DiETa_Reserve_Byte7  : 48|8@1+ (1.000000,0.000000) [0.000000|255.000000] "" Vector__XXX
 SG_ DiETa_Reserve_Byte8  : 56|8@1+ (1.000000,0.000000) [0.000000|255.000000] "" Vector__XXX

BO_ 1520 Dimmung_01: 8 ICAS1_Gateway
 SG_ DI_KL_58xd  : 0|8@1+ (1.000000,0.000000) [0.000000|253.000000] "" Airbag Schaltbetaetigung
 SG_ DI_KL_58xs  : 8|7@1+ (1.000000,0.000000) [0.000000|100.000000] "Unit_PerCent" Airbag
 SG_ DI_Display_Nachtdesign  : 15|1@1+ (1.000000,0.000000) [0.000000|1.000000] "" Vector__XXX
 SG_ DI_KL_58xt  : 16|7@1+ (1.000000,0.000000) [0.000000|100.000000] "Unit_PerCent" Airbag Schaltbetaetigung
 SG_ DI_Fotosensor  : 24|16@1+ (1.000000,0.000000) [0.000000|65535.000000] "" Vector__XXX
 SG_ BCM1_Stellgroesse_Kl_58s  : 40|7@1+ (1.000000,0.000000) [0.000000|100.000000] "" Vector__XXX

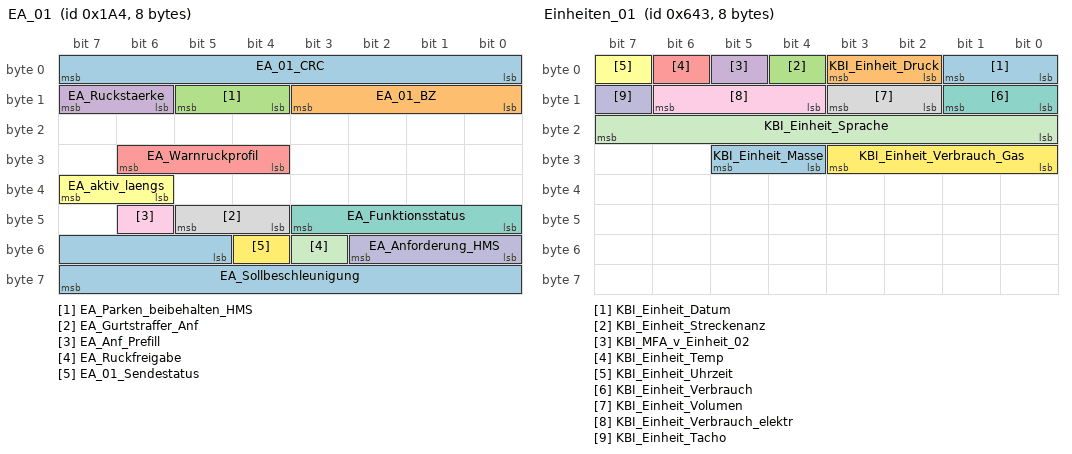
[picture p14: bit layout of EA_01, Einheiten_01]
BO_ 420 EA_01: 8 ICAS1_Gateway
 SG_ EA_01_CRC  : 0|8@1+ (1.000000,0.000000) [0.000000|255.000000] "" Motor_BEV
 SG_ EA_01_BZ  : 8|4@1+ (1.000000,0.000000) [0.000000|15.000000] "" Motor_BEV
 SG_ EA_Parken_beibehalten_HMS  : 12|2@1+ (1.000000,0.000000) [0.000000|3.000000] "" Vector__XXX
 SG_ EA_Ruckstaerke  : 14|2@1+ (1.000000,0.000000) [0.000000|3.000000] "" Vector__XXX
 SG_ EA_Warnruckprofil  : 28|3@1+ (1.000000,0.000000) [0.000000|7.000000] "" Vector__XXX
 SG_ EA_aktiv_laengs  : 38|2@1+ (1.000000,0.000000) [0.000000|3.000000] "" Motor_BEV
 SG_ EA_Funktionsstatus  : 40|4@1+ (1.000000,0.000000) [0.000000|15.000000] "" Motor_BEV
 SG_ EA_Gurtstraffer_Anf  : 44|2@1+ (1.000000,0.000000) [0.000000|3.000000] "" Airbag
 SG_ EA_Anf_Prefill  : 46|1@1+ (1.000000,0.000000) [0.000000|1.000000] "" Vector__XXX
 SG_ EA_Anforderung_HMS  : 48|3@1+ (1.000000,0.000000) [0.000000|7.000000] "" Vector__XXX
 SG_ EA_Ruckfreigabe  : 51|1@1+ (1.000000,0.000000) [0.000000|1.000000] "" Vector__XXX
 SG_ EA_01_Sendestatus  : 52|1@1+ (1.000000,0.000000) [0.000000|1.000000] "" Vector__XXX
 SG_ EA_Sollbeschleunigung  : 53|11@1+ (0.005000,-7.220000) [-7.220000|3.005000] "Unit_MeterPerSeconSquar" Motor_BEV

BO_ 374 EBKV_03: 8 ICAS1_Gateway
 SG_ EBKV_03_CRC  : 0|8@1+ (1.000000,0.000000) [0.000000|255.000000] "" Vector__XXX
 SG_ EBKV_03_BZ  : 8|4@1+ (1.000000,0.000000) [0.000000|15.000000] "" Vector__XXX
 SG_ EBKV_Activate_Fallback_ESP  : 12|1@1+ (1.000000,0.000000) [0.000000|1.000000] "" Vector__XXX
 SG_ EBKV_Restdruckabsenkung  : 13|3@1+ (1.000000,0.000000) [0.000000|7.000000] "" Vector__XXX
 SG_ EBKV_Status_02  : 16|4@1+ (1.000000,0.000000) [0.000000|15.000000] "" Vector__XXX
 SG_ EBKV_Diagnose  : 20|1@1+ (1.000000,0.000000) [0.000000|1.000000] "" Vector__XXX
 SG_ EBKV_Fahrer_bremst  : 21|1@1+ (1.000000,0.000000) [0.000000|1.000000] "" Motor_BEV
 SG_ EBKV_QBit_Fahrer_bremst  : 22|1@1+ (1.000000,0.000000) [0.000000|1.000000] "" Motor_BEV
 SG_ EBKV_Fahrer_bremst_deutlich  : 23|1@1+ (1.000000,0.000000) [0.000000|1.000000] "" Vector__XXX
 SG_ EBKV_OBD_Status  : 24|1@1+ (1.000000,0.000000) [0.000000|1.000000] "" Motor_BEV
 SG_ EBKV_VMM_Sek_Notstopp_Status  : 25|3@1+ (1.000000,0.000000) [0.000000|7.000000] "" Vector__XXX
 SG_ EBKV_Anforderung_HMS  : 28|3@1+ (1.000000,0.000000) [0.000000|7.000000] "" Vector__XXX
 SG_ SBS_Anforderung_GE  : 31|1@1+ (1.000000,0.000000) [0.000000|1.000000] "" Vector__XXX
 SG_ EPB_Status_ext  : 32|3@1+ (1.000000,0.000000) [0.000000|7.000000] "" Motor_BEV
 SG_ EBKV_Bremspedalweg  : 40|8@1+ (0.400000,-0.400000) [0.000000|101.200000] "Unit_PerCent" Motor_BEV
 SG_ EBKV_Kraftblending_Reserve  : 48|8@1+ (0.500000,0.000000) [0.000000|125.000000] "Unit_Bar" Vector__XXX
 SG_ EBKV_Aussteuerdruck  : 56|8@1+ (1.000000,0.000000) [0.000000|250.000000] "Unit_Bar" Vector__XXX

BO_ 1603 Einheiten_01: 8 ICAS1_KommunikationsServer
 SG_ KBI_Einheit_Datum  : 0|2@1+ (1.000000,0.000000) [0.000000|3.000000] "" Vector__XXX
 SG_ KBI_Einheit_Druck  : 2|2@1+ (1.000000,0.000000) [0.000000|3.000000] "" Vector__XXX
 SG_ KBI_Einheit_Streckenanz  : 4|1@1+ (1.000000,0.000000) [0.000000|1.000000] "" Vector__XXX
 SG_ KBI_MFA_v_Einheit_02  : 5|1@1+ (1.000000,0.000000) [0.000000|1.000000] "" Motor_BEV
 SG_ KBI_Einheit_Temp  : 6|1@1+ (1.000000,0.000000) [0.000000|1.000000] "" Vector__XXX
 SG_ KBI_Einheit_Uhrzeit  : 7|1@1+ (1.000000,0.000000) [0.000000|1.000000] "" Vector__XXX
 SG_ KBI_Einheit_Verbrauch  : 8|2@1+ (1.000000,0.000000) [0.000000|3.000000] "" Vector__XXX
 SG_ KBI_Einheit_Volumen  : 10|2@1+ (1.000000,0.000000) [0.000000|3.000000] "" Vector__XXX
 SG_ KBI_Einheit_Verbrauch_elektr  : 12|3@1+ (1.000000,0.000000) [0.000000|7.000000] "" Vector__XXX
 SG_ KBI_Einheit_Tacho  : 15|1@1+ (1.000000,0.000000) [0.000000|1.000000] "" Motor_BEV
 SG_ KBI_Einheit_Sprache  : 16|8@1+ (1.000000,0.000000) [0.000000|255.000000] "" Vector__XXX
 SG_ KBI_Einheit_Verbrauch_Gas  : 24|4@1+ (1.000000,0.000000) [0.000000|15.000000] "" Vector__XXX
 SG_ KBI_Einheit_Masse  : 28|2@1+ (1.000000,0.000000) [0.000000|3.000000] "" Vector__XXX

BU_:  Airbag BAP_Tester ICAS1_Gateway ICAS1_KommunikationsServer LE1 LE2 Motor_BEV Schaltbetaetigung

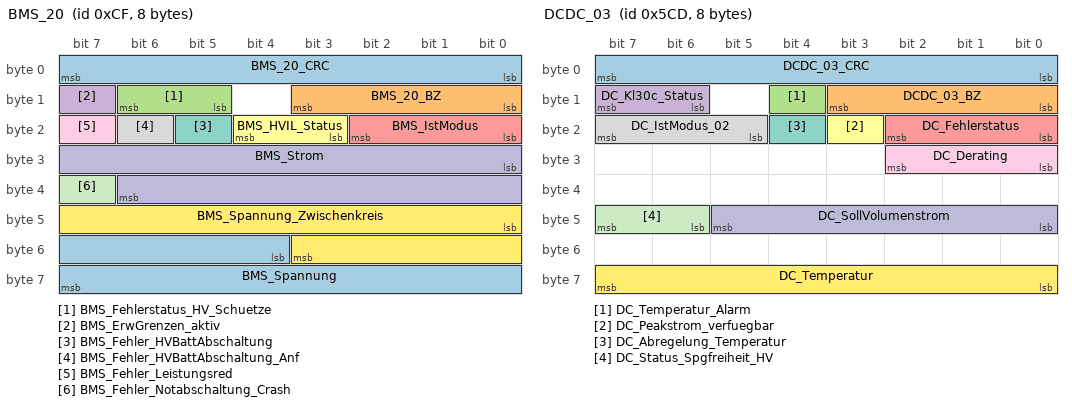
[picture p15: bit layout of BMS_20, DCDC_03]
BO_ 207 BMS_20: 8 ICAS1_Gateway
 SG_ BMS_20_CRC  : 0|8@1+ (1.000000,0.000000) [0.000000|255.000000] "" Motor_BEV
 SG_ BMS_20_BZ  : 8|4@1+ (1.000000,0.000000) [0.000000|15.000000] "" Motor_BEV
 SG_ BMS_Fehlerstatus_HV_Schuetze  : 13|2@1+ (1.000000,0.000000) [0.000000|3.000000] "" Motor_BEV
 SG_ BMS_ErwGrenzen_aktiv  : 15|1@1+ (1.000000,0.000000) [0.000000|1.000000] "" Motor_BEV
 SG_ BMS_IstModus  : 16|3@1+ (1.000000,0.000000) [0.000000|7.000000] "" LE1 LE2 Motor_BEV
 SG_ BMS_HVIL_Status  : 19|2@1+ (1.000000,0.000000) [0.000000|3.000000] "" Motor_BEV
 SG_ BMS_Fehler_HVBattAbschaltung  : 21|1@1+ (1.000000,0.000000) [0.000000|1.000000] "" Motor_BEV
 SG_ BMS_Fehler_HVBattAbschaltung_Anf  : 22|1@1+ (1.000000,0.000000) [0.000000|1.000000] "" Motor_BEV
 SG_ BMS_Fehler_Leistungsred  : 23|1@1+ (1.000000,0.000000) [0.000000|1.000000] "" Motor_BEV
 SG_ BMS_Strom  : 24|15@1+ (0.100000,-1630.000000) [-1630.000000|1630.000000] "Unit_Amper" Motor_BEV
 SG_ BMS_Fehler_Notabschaltung_Crash  : 39|1@1+ (1.000000,0.000000) [0.000000|1.000000] "" Vector__XXX
 SG_ BMS_Spannung_Zwischenkreis  : 40|12@1+ (0.500000,-1000.000000) [-1000.000000|1000.000000] "Unit_Volt" Motor_BEV
 SG_ BMS_Spannung  : 52|12@1+ (0.250000,0.000000) [0.000000|1000.000000] "Unit_Volt" Motor_BEV

BO_ 2463978704 BMS_21: 8 ICAS1_Gateway
 SG_ BMS_Max_Entladestrom  : 12|13@1+ (0.200000,0.000000) [0.000000|1630.000000] "Unit_Amper" Motor_BEV
 SG_ BMS_Max_Ladestrom  : 25|13@1+ (0.200000,0.000000) [0.000000|1630.000000] "Unit_Amper" Motor_BEV
 SG_ BMS_Max_Entladeleistung  : 38|13@1+ (100.000000,0.000000) [0.000000|818000.000000] "Unit_Watt" Motor_BEV
 SG_ BMS_Max_Ladeleistung  : 51|13@1+ (100.000000,0.000000) [0.000000|818000.000000] "Unit_Watt" Motor_BEV

BO_ 2463978705 BMS_22: 8 ICAS1_Gateway
 SG_ BMS_Status_EoHVL_Heizer  : 15|2@1+ (1.000000,0.000000) [0.000000|3.000000] "" Motor_BEV
 SG_ BMS_Ladezustand  : 17|11@1+ (0.050000,0.000000) [0.000000|100.000000] "Unit_PerCent" Motor_BEV
 SG_ BMS_PerfInd_Entladen  : 28|10@1+ (0.200000,0.000000) [0.000000|200.000000] "Unit_PerCent" Motor_BEV
 SG_ BMS_PerfInd_Laden  : 38|10@1+ (0.200000,0.000000) [0.000000|200.000000] "Unit_PerCent" Motor_BEV
 SG_ BMS_Nutzbare_EntladeEnergie  : 48|16@1+ (5.000000,0.000000) [0.000000|327400.000000] "Unit_WattHour" Motor_BEV

BO_ 2589283664 BMS_24: 8 ICAS1_Gateway
 SG_ BMS_Balancing_Aktiv  : 14|2@1+ (1.000000,0.000000) [0.000000|3.000000] "" Vector__XXX
 SG_ BMS_Ladevorgang_aktiv  : 16|1@1+ (1.000000,0.000000) [0.000000|1.000000] "" Vector__XXX
 SG_ BMS_RIso_Ext  : 17|12@1+ (5.000000,0.000000) [0.000000|20465.000000] "Unit_KiloOhm" Motor_BEV
 SG_ BMS_Min_Ladezustand  : 29|11@1+ (0.050000,0.000000) [0.000000|100.000000] "Unit_PerCent" Motor_BEV
 SG_ BMS_Max_Energie  : 40|13@1+ (40.000000,0.000000) [0.000000|327400.000000] "Unit_WattHour" Motor_BEV
 SG_ BMS_Max_Ladezustand  : 53|11@1+ (0.050000,0.000000) [0.000000|100.000000] "Unit_PerCent" Motor_BEV

BO_ 2589283665 BMS_25: 8 ICAS1_Gateway
 SG_ BMS_BattHeizung_VerbautStatus  : 13|1@1+ (1.000000,0.000000) [0.000000|1.000000] "" Motor_BEV
 SG_ BMS_Fehler_NTKreis  : 14|1@1+ (1.000000,0.000000) [0.000000|1.000000] "" Vector__XXX
 SG_ BMS_Temperierung_Anf  : 15|3@1+ (1.000000,0.000000) [0.000000|7.000000] "" Motor_BEV
 SG_ BMS_Status_Ventil1  : 18|3@1+ (1.000000,0.000000) [0.000000|7.000000] "" Motor_BEV
 SG_ BMS_Status_Ventil2  : 21|3@1+ (1.000000,0.000000) [0.000000|7.000000] "" Motor_BEV
 SG_ BMS_Pumpe1_Ansteuerung  : 24|4@1+ (10.000000,0.000000) [0.000000|100.000000] "Unit_PerCent" Motor_BEV
 SG_ BMS_Pumpe2_Ansteuerung  : 28|4@1+ (10.000000,0.000000) [0.000000|100.000000] "Unit_PerCent" Motor_BEV
 SG_ BMS_VorlaufTemperatur  : 32|8@1+ (0.500000,-40.000000) [-40.000000|86.000000] "Unit_DegreCelsi" Motor_BEV
 SG_ BMS_Temperatur  : 40|8@1+ (0.500000,-40.000000) [-40.000000|86.500000] "Unit_DegreCelsi" Motor_BEV
 SG_ BMS_SollVorlauftemperatur  : 48|8@1+ (0.500000,-40.000000) [-40.000000|86.500000] "Unit_DegreCelsi" Motor_BEV
 SG_ BMS_RuecklaufTemperatur  : 56|8@1+ (0.500000,-40.000000) [-40.000000|86.000000] "Unit_DegreCelsi" Motor_BEV

BO_ 2589283760 BMS_26: 8 ICAS1_Gateway
 SG_ BMS_Max_Spannung  : 20|10@1+ (1.000000,0.000000) [0.000000|1000.000000] "Unit_Volt" Motor_BEV
 SG_ BMS_Min_Spannung  : 30|10@1+ (1.000000,0.000000) [0.000000|1000.000000] "Unit_Volt" Motor_BEV
 SG_ BMS_Dauer_Entladeleistung  : 40|12@1+ (200.000000,0.000000) [0.000000|818000.000000] "Unit_Watt" Motor_BEV
 SG_ BMS_Dauer_Ladeleistung  : 52|12@1+ (200.000000,0.000000) [0.000000|818000.000000] "Unit_Watt" Motor_BEV

BO_ 2463978646 Charisma_11: 24 ICAS1_Gateway
 SG_ CHA_Ziel_FahrPr_AGA  : 0|4@1+ (1.000000,0.000000) [0.000000|15.000000] "" Vector__XXX
 SG_ CHA_Ziel_FahrPr_ESP  : 4|4@1+ (1.000000,0.000000) [0.000000|15.000000] "" Motor_BEV
 SG_ CHA_Ziel_FahrPr_Freilauf  : 8|4@1+ (1.000000,0.000000) [0.000000|15.000000] "" Vector__XXX
 SG_ CHA_Fahrer_Umschaltung  : 14|1@1+ (1.000000,0.000000) [0.000000|1.000000] "" Motor_BEV
 SG_ CHA_Fahrer_Umschaltung_BMA  : 15|1@1+ (1.000000,0.000000) [0.000000|1.000000] "" Vector__XXX
 SG_ CHA_Ziel_FahrPr_MO  : 16|4@1+ (1.000000,0.000000) [0.000000|15.000000] "" Motor_BEV
 SG_ CHA_Ziel_FahrPr_GE  : 20|4@1+ (1.000000,0.000000) [0.000000|15.000000] "" Vector__XXX
 SG_ CHA_Ziel_FahrPr_ALR  : 24|4@1+ (1.000000,0.000000) [0.000000|15.000000] "" Motor_BEV
 SG_ CHA_Ziel_FahrPr_MO_BZS  : 28|4@1+ (1.000000,0.000000) [0.000000|15.000000] "" Vector__XXX
 SG_ CHA_Ziel_FahrPr_DR  : 32|4@1+ (1.000000,0.000000) [0.000000|15.000000] "" Vector__XXX
 SG_ CHA_Ziel_FahrPr_VAQ  : 36|4@1+ (1.000000,0.000000) [0.000000|15.000000] "" Vector__XXX
 SG_ CHA_Ziel_FahrPr_AFS  : 40|4@1+ (1.000000,0.000000) [0.000000|15.000000] "" Vector__XXX
 SG_ CHA_Ziel_FahrPr_PreCrash  : 44|4@1+ (1.000000,0.000000) [0.000000|15.000000] "" Airbag
 SG_ CHA_Ziel_FahrPr_EPS  : 48|4@1+ (1.000000,0.000000) [0.000000|15.000000] "" Vector__XXX
 SG_ CHA_Ziel_FahrPr_ACC  : 52|4@1+ (1.000000,0.000000) [0.000000|15.000000] "" Vector__XXX
 SG_ CHA_Ziel_FahrPr_SAK  : 56|4@1+ (1.000000,0.000000) [0.000000|15.000000] "" Vector__XXX
 SG_ CHA_Ziel_FahrPr_MO_StSt  : 60|4@1+ (1.000000,0.000000) [0.000000|15.000000] "" Vector__XXX
 SG_ CHA_Ziel_FahrPr_EBKV  : 64|4@1+ (1.000000,0.000000) [0.000000|15.000000] "" Vector__XXX
 SG_ CHA_Ziel_FahrPr_IL  : 68|4@1+ (1.000000,0.000000) [0.000000|15.000000] "" Vector__XXX
 SG_ CHA_Current_Mode  : 72|4@1+ (1.000000,0.000000) [0.000000|15.000000] "" Vector__XXX
 SG_ CHA_Ziel_FahrPr_QS  : 80|4@1+ (1.000000,0.000000) [0.000000|15.000000] "" Vector__XXX
 SG_ CHA_Ziel_FahrPr_SCU  : 84|4@1+ (1.000000,0.000000) [0.000000|15.000000] "" Vector__XXX
 SG_ CHA_Ziel_FahrPr_HAL  : 88|4@1+ (1.000000,0.000000) [0.000000|15.000000] "" Vector__XXX
 SG_ CHA_Ziel_FahrPr_NR  : 92|4@1+ (1.000000,0.000000) [0.000000|15.000000] "" Vector__XXX
 SG_ CHA_Ziel_FahrPr_AV  : 96|4@1+ (1.000000,0.000000) [0.000000|15.000000] "" Vector__XXX
 SG_ CHA_Ziel_FahrPr_MXB  : 100|4@1+ (1.000000,0.000000) [0.000000|15.000000] "" Vector__XXX
 SG_ CHA_Ziel_FahrPr_AFR  : 104|4@1+ (1.000000,0.000000) [0.000000|15.000000] "" Vector__XXX
 SG_ CHA_Ziel_FahrPr_HDC  : 108|4@1+ (1.000000,0.000000) [0.000000|15.000000] "" Vector__XXX
 SG_ CHA_Ziel_FahrPr_EAR  : 112|4@1+ (1.000000,0.000000) [0.000000|15.000000] "" Vector__XXX
 SG_ CHA_Ziel_FahrPr_AEB  : 116|4@1+ (1.000000,0.000000) [0.000000|15.000000] "" Vector__XXX
 SG_ CHA_Ziel_FahrPr_FCWO  : 120|4@1+ (1.000000,0.000000) [0.000000|15.000000] "" Vector__XXX
 SG_ CHA_Ziel_FahrPr_FCWP  : 124|4@1+ (1.000000,0.000000) [0.000000|15.000000] "" Vector__XXX
 SG_ CHA_Ziel_FahrPr_ToS_laengs  : 144|4@1+ (1.000000,0.000000) [0.000000|15.000000] "" Vector__XXX
 SG_ CHA_Ziel_FahrPr_ToS_quer  : 148|4@1+ (1.000000,0.000000) [0.000000|15.000000] "" Vector__XXX
 SG_ CHA_Ziel_FahrPr_mFDR  : 152|4@1+ (1.000000,0.000000) [0.000000|15.000000] "" Vector__XXX
 SG_ CHA_Ziel_FahrPr_Reku_ZwGas  : 156|4@1+ (1.000000,0.000000) [0.000000|15.000000] "" Vector__XXX
 SG_ CHA_Ziel_FahrPr_MO_Freilauf  : 160|4@1+ (1.000000,0.000000) [0.000000|15.000000] "" Vector__XXX
 SG_ CHA_Ziel_FahrPr_BMS  : 164|4@1+ (1.000000,0.000000) [0.000000|15.000000] "" Vector__XXX
 SG_ CHA_Current_Mode_BMA  : 168|4@1+ (1.000000,0.000000) [0.000000|15.000000] "" Vector__XXX
 SG_ CHA_Ziel_FahrPr_PDC  : 172|4@1+ (1.000000,0.000000) [0.000000|15.000000] "" Vector__XXX
 SG_ CHA_Ziel_FahrPr_HHC  : 176|4@1+ (1.000000,0.000000) [0.000000|15.000000] "" Vector__XXX
 SG_ CHA_Ziel_FahrPr_EDS  : 180|4@1+ (1.000000,0.000000) [0.000000|15.000000] "" Vector__XXX
 SG_ CHA_Ziel_FahrPr_PACC  : 184|4@1+ (1.000000,0.000000) [0.000000|15.000000] "" Vector__XXX
 SG_ CHA_Ziel_FahrPr_AGK  : 188|4@1+ (1.000000,0.000000) [0.000000|15.000000] "" Vector__XXX

BO_ 514 Daempfer_03: 32 ICAS1_Gateway
 SG_ DR_Aufbaubeschleunigung_HR  : 12|10@1+ (0.032700,-15.696000) [-15.696000|15.696000] "Unit_MeterPerSeconSquar" Motor_BEV
 SG_ DR_Aufbaubeschleunigung_VR  : 22|10@1+ (0.032700,-15.696000) [-15.696000|15.696000] "Unit_MeterPerSeconSquar" Motor_BEV
 SG_ DR_Aufbaubeschleunigung_VL  : 32|10@1+ (0.032700,-15.696000) [-15.696000|15.696000] "Unit_MeterPerSeconSquar" Motor_BEV
 SG_ DR_Aufbaubeschleunigung_HL  : 42|10@1+ (0.032700,-15.696000) [-15.696000|15.696000] "Unit_MeterPerSeconSquar" Motor_BEV
 SG_ DR_Funktionsstatus  : 52|2@1+ (1.000000,0.000000) [0.000000|3.000000] "" Vector__XXX
 SG_ DR_Drehwinkelsensortausch_VL  : 72|2@1+ (1.000000,0.000000) [1.000000|3.000000] "" Vector__XXX
 SG_ DR_Drehwinkelsensortausch_VR  : 74|2@1+ (1.000000,0.000000) [1.000000|3.000000] "" Vector__XXX
 SG_ DR_Drehwinkelsensortausch_HL  : 76|2@1+ (1.000000,0.000000) [1.000000|3.000000] "" Vector__XXX
 SG_ DR_Drehwinkelsensortausch_HR  : 78|2@1+ (1.000000,0.000000) [1.000000|3.000000] "" Vector__XXX
 SG_ DR_Drehwinkel_VL  : 80|12@1+ (0.088000,0.000000) [0.000000|359.920000] "" Vector__XXX
 SG_ DR_Drehwinkel_VR  : 92|12@1+ (0.088000,0.000000) [0.000000|359.920000] "" Vector__XXX
 SG_ DR_Drehwinkel_HL  : 104|12@1+ (0.088000,0.000000) [0.000000|359.920000] "" Vector__XXX
 SG_ DR_Drehwinkel_HR  : 116|12@1+ (0.088000,0.000000) [0.000000|359.920000] "" Vector__XXX

BO_ 1485 DCDC_03: 8 ICAS1_Gateway
 SG_ DCDC_03_CRC  : 0|8@1+ (1.000000,0.000000) [0.000000|255.000000] "" Motor_BEV
 SG_ DCDC_03_BZ  : 8|4@1+ (1.000000,0.000000) [0.000000|15.000000] "" Motor_BEV
 SG_ DC_Temperatur_Alarm  : 12|1@1+ (1.000000,0.000000) [0.000000|1.000000] "" Vector__XXX
 SG_ DC_Kl30c_Status  : 14|2@1+ (1.000000,0.000000) [0.000000|3.000000] "" Motor_BEV
 SG_ DC_Fehlerstatus  : 16|3@1+ (1.000000,0.000000) [0.000000|7.000000] "" Vector__XXX
 SG_ DC_Peakstrom_verfuegbar  : 19|1@1+ (1.000000,0.000000) [0.000000|1.000000] "" Vector__XXX
 SG_ DC_Abregelung_Temperatur  : 20|1@1+ (1.000000,0.000000) [0.000000|1.000000] "" Vector__XXX
 SG_ DC_IstModus_02  : 21|3@1+ (1.000000,0.000000) [0.000000|7.000000] "" Vector__XXX
 SG_ DC_Derating  : 24|3@1+ (1.000000,0.000000) [0.000000|7.000000] "" Vector__XXX
 SG_ DC_SollVolumenstrom  : 40|6@1+ (0.500000,0.000000) [0.000000|30.500000] "Unit_LiterPerMinut" Motor_BEV
 SG_ DC_Status_Spgfreiheit_HV  : 46|2@1+ (1.000000,0.000000) [0.000000|3.000000] "" Vector__XXX
 SG_ DC_Temperatur  : 56|8@1+ (1.000000,-40.000000) [-40.000000|213.000000] "Unit_DegreCelsi" Motor_BEV

BO_ 247 DCDC_04: 8 ICAS1_Gateway
 SG_ DCDC_04_CRC  : 0|8@1+ (1.000000,0.000000) [0.000000|255.000000] "" Vector__XXX
 SG_ DCDC_04_BZ  : 8|4@1+ (1.000000,0.000000) [0.000000|15.000000] "" Vector__XXX
 SG_ DC_Vorladung_Status  : 34|1@1+ (1.000000,0.000000) [0.000000|1.000000] "" Motor_BEV
 SG_ DC_Fehler_extern  : 35|1@1+ (1.000000,0.000000) [0.000000|1.000000] "" Motor_BEV
 SG_ DC_Fehler_intern  : 36|1@1+ (1.000000,0.000000) [0.000000|1.000000] "" Motor_BEV
 SG_ DC_Status_Spgfreiheit  : 37|2@1+ (1.000000,0.000000) [0.000000|3.000000] "" Motor_BEV
 SG_ DC_Status_EoHVL  : 39|2@1+ (1.000000,0.000000) [0.000000|3.000000] "" Motor_BEV
 SG_ DC_IstModus_02  : 41|3@1+ (1.000000,0.000000) [0.000000|7.000000] "" Motor_BEV
 SG_ DC_IstStrom_HV  : 44|10@1+ (0.100000,-51.100000) [-51.100000|51.000000] "Unit_Amper" Motor_BEV
 SG_ DC_IstLeistung_HV  : 54|10@1+ (10.000000,-4000.000000) [-4000.000000|6210.000000] "Unit_Watt" Motor_BEV

BO_ 2617027088 DEV_Airbag_ASM_01: 8 Airbag
 SG_ DEV_Airbag_ASM_01_Data  : 0|64@1+ (1.000000,0.000000) [0.000000|18446744073709551616.000000] "" Vector__XXX

BO_ 2617027072 DEV_Airbag_Resp_00: 8 Airbag
 SG_ DEV_Airbag_Resp_00_Data  : 0|64@1+ (1.000000,0.000000) [0.000000|18446744073709551616.000000] "" Vector__XXX

BO_ 2617027073 DEV_Airbag_Resp_01: 8 Airbag
 SG_ DEV_Airbag_Resp_01_Data  : 0|64@1+ (1.000000,0.000000) [0.000000|18446744073709551616.000000] "" Vector__XXX

BO_ 2617027074 DEV_Airbag_Resp_02: 8 Airbag
 SG_ DEV_Airbag_Resp_02_Data  : 0|64@1+ (1.000000,0.000000) [0.000000|18446744073709551616.000000] "" Vector__XXX

BO_ 2617027075 DEV_Airbag_Resp_03: 8 Airbag
 SG_ DEV_Airbag_Resp_03_Data  : 0|64@1+ (1.000000,0.000000) [0.000000|18446744073709551616.000000] "" Vector__XXX

BO_ 2617027076 DEV_Airbag_Resp_04: 8 Airbag
 SG_ DEV_Airbag_Resp_04_Data  : 0|64@1+ (1.000000,0.000000) [0.000000|18446744073709551616.000000] "" Vector__XXX

BO_ 2617027077 DEV_Airbag_Resp_05: 8 Airbag
 SG_ DEV_Airbag_Resp_05_Data  : 0|64@1+ (1.000000,0.000000) [0.000000|18446744073709551616.000000] "" Vector__XXX

BO_ 2617027078 DEV_Airbag_Resp_06: 8 Airbag
 SG_ DEV_Airbag_Resp_06_Data  : 0|64@1+ (1.000000,0.000000) [0.000000|18446744073709551616.000000] "" Vector__XXX

BO_ 2617027079 DEV_Airbag_Resp_07: 8 Airbag
 SG_ DEV_Airbag_Resp_07_Data  : 0|64@1+ (1.000000,0.000000) [0.000000|18446744073709551616.000000] "" Vector__XXX

BO_ 2617027080 DEV_Airbag_Resp_08: 8 Airbag
 SG_ DEV_Airbag_Resp_08_Data  : 0|64@1+ (1.000000,0.000000) [0.000000|18446744073709551616.000000] "" Vector__XXX

BO_ 2617027081 DEV_Airbag_Resp_09: 8 Airbag
 SG_ DEV_Airbag_Resp_09_Data  : 0|64@1+ (1.000000,0.000000) [0.000000|18446744073709551616.000000] "" Vector__XXX

BO_ 2617027082 DEV_Airbag_Resp_10: 8 Airbag
 SG_ DEV_Airbag_Resp_10_Data  : 0|64@1+ (1.000000,0.000000) [0.000000|18446744073709551616.000000] "" Vector__XXX

BO_ 2617027083 DEV_Airbag_Resp_11: 8 Airbag
 SG_ DEV_Airbag_Resp_11_Data  : 0|64@1+ (1.000000,0.000000) [0.000000|18446744073709551616.000000] "" Vector__XXX

BO_ 2617154048 DEV_Waehlhebel_Resp_00: 8 Schaltbetaetigung
 SG_ DEV_Waehlhebel_Resp_00_Data  : 0|64@1+ (1.000000,0.000000) [0.000000|18446744073709551616.000000] "" Vector__XXX

BO_ 2617154049 DEV_Waehlhebel_Resp_01: 8 Schaltbetaetigung
 SG_ DEV_Waehlhebel_Resp_01_Data  : 0|64@1+ (1.000000,0.000000) [0.000000|18446744073709551616.000000] "" Vector__XXX

BO_ 2617154050 DEV_Waehlhebel_Resp_02: 8 Schaltbetaetigung
 SG_ DEV_Waehlhebel_Resp_02_Data  : 0|64@1+ (1.000000,0.000000) [0.000000|18446744073709551616.000000] "" Vector__XXX

BO_ 2617154051 DEV_Waehlhebel_Resp_03: 8 Schaltbetaetigung
 SG_ DEV_Waehlhebel_Resp_03_Data  : 0|64@1+ (1.000000,0.000000) [0.000000|18446744073709551616.000000] "" Vector__XXX

BO_ 2617154052 DEV_Waehlhebel_Resp_04: 8 Schaltbetaetigung
 SG_ DEV_Waehlhebel_Resp_04_Data  : 0|64@1+ (1.000000,0.000000) [0.000000|18446744073709551616.000000] "" Vector__XXX

BO_ 2617154053 DEV_Waehlhebel_Resp_05: 8 Schaltbetaetigung
 SG_ DEV_Waehlhebel_Resp_05_Data  : 0|64@1+ (1.000000,0.000000) [0.000000|18446744073709551616.000000] "" Vector__XXX

BO_ 2549876269 Diag_Waehlhebel_Req: 8 Motor_BEV
 SG_ Diag_Waehlhebel_Req_Data  : 0|64@1+ (1.000000,0.000000) [0.000000|18446744073709551616.000000] "" Schaltbetaetigung

BO_ 2550007341 Diag_Waehlhebel_Resp: 8 Schaltbetaetigung
 SG_ Diag_Waehlhebel_Resp_Data  : 0|64@1+ (1.000000,0.000000) [0.000000|18446744073709551616.000000] "" Motor_BEV

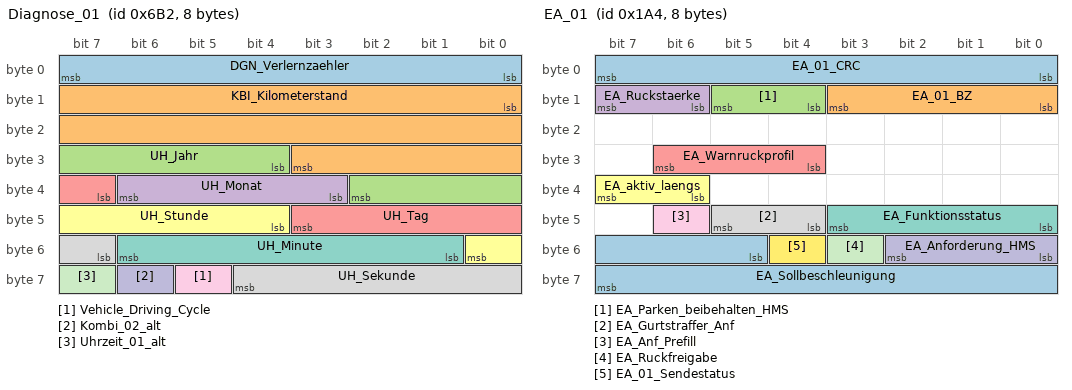
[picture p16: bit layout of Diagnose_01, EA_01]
BO_ 1714 Diagnose_01: 8 ICAS1_Gateway
 SG_ DGN_Verlernzaehler  : 0|8@1+ (1.000000,0.000000) [0.000000|254.000000] "" Airbag LE1 LE2 Motor_BEV
 SG_ KBI_Kilometerstand  : 8|20@1+ (1.000000,0.000000) [0.000000|1048573.000000] "Unit_KiloMeter" Airbag LE1 LE2 Motor_BEV
 SG_ UH_Jahr  : 28|7@1+ (1.000000,2000.000000) [2000.000000|2127.000000] "Unit_Year" Airbag LE1 LE2 Motor_BEV
 SG_ UH_Monat  : 35|4@1+ (1.000000,0.000000) [1.000000|12.000000] "Unit_Month" Airbag LE1 LE2 Motor_BEV
 SG_ UH_Tag  : 39|5@1+ (1.000000,0.000000) [1.000000|31.000000] "Unit_Day" Airbag LE1 LE2 Motor_BEV
 SG_ UH_Stunde  : 44|5@1+ (1.000000,0.000000) [0.000000|23.000000] "Unit_Hours" Airbag LE1 LE2 Motor_BEV
 SG_ UH_Minute  : 49|6@1+ (1.000000,0.000000) [0.000000|59.000000] "Unit_Minut" Airbag LE1 LE2 Motor_BEV
 SG_ UH_Sekunde  : 55|6@1+ (1.000000,0.000000) [0.000000|59.000000] "Unit_Secon" Airbag LE1 LE2 Motor_BEV
 SG_ Vehicle_Driving_Cycle  : 61|1@1+ (1.000000,0.000000) [0.000000|1.000000] "" Airbag
 SG_ Kombi_02_alt  : 62|1@1+ (1.000000,0.000000) [0.000000|1.000000] "" Vector__XXX
 SG_ Uhrzeit_01_alt  : 63|1@1+ (1.000000,0.000000) [0.000000|1.000000] "" Vector__XXX

BO_ 851 DiETa_01: 8 ICAS1_Gateway
 SG_ DiETas_01_CRC  : 0|8@1+ (1.000000,0.000000) [0.000000|255.000000] "" Airbag
 SG_ DiETas_01_BZ  : 8|4@1+ (1.000000,0.000000) [0.000000|15.000000] "" Airbag
 SG_ DiETa_Reserve_Byte2_4  : 12|1@1+ (1.000000,0.000000) [0.000000|1.000000] "" Vector__XXX
 SG_ DiETa_Status  : 13|2@1+ (1.000000,0.000000) [0.000000|3.000000] "" Airbag
 SG_ DiETa_ResponseError  : 15|1@1+ (1.000000,0.000000) [0.000000|1.000000] "" Vector__XXX
 SG_ DiETa_Car  : 16|2@1+ (1.000000,0.000000) [0.000000|3.000000] "" Vector__XXX
 SG_ DiETa_Klima  : 18|2@1+ (1.000000,0.000000) [0.000000|3.000000] "" Vector__XXX
 SG_ DiETa_Mode  : 20|2@1+ (1.000000,0.000000) [0.000000|3.000000] "" Vector__XXX
 SG_ DiETa_Parken  : 22|2@1+ (1.000000,0.000000) [0.000000|3.000000] "" Vector__XXX
 SG_ DiETa_FSH_Taste  : 24|2@1+ (1.000000,0.000000) [0.000000|3.000000] "" Vector__XXX
 SG_ DiETa_HSH_Taste  : 26|2@1+ (1.000000,0.000000) [0.000000|3.000000] "" Vector__XXX
 SG_ DiETa_Warnblink_Taste  : 28|2@1+ (1.000000,0.000000) [0.000000|3.000000] "" Vector__XXX
 SG_ DiETa_FAS_Stufe  : 30|2@1+ (1.000000,0.000000) [0.000000|3.000000] "" Vector__XXX
 SG_ DiETa_PAO_ON_Status  : 32|2@1+ (1.000000,0.000000) [0.000000|3.000000] "" Airbag
 SG_ DiETa_PAO_OFF_Status  : 34|2@1+ (1.000000,0.000000) [0.000000|3.000000] "" Airbag
 SG_ DiETa_Defrost_Taste  : 36|2@1+ (1.000000,0.000000) [0.000000|3.000000] "" Vector__XXX
 SG_ DiETa_Reserve_Byte5_6  : 38|2@1+ (1.000000,0.000000) [0.000000|3.000000] "" Vector__XXX
 SG_ DiETa_Lock_Unlock_Taste  : 40|3@1+ (1.000000,0.000000) [0.000000|7.000000] "" Vector__XXX
 SG_ DiETa_Mode_roh  : 43|1@1+ (1.000000,0.000000) [0.000000|1.000000] "" Vector__XXX
 SG_ DiETa_Reserve_Byte6_3  : 44|4@1+ (1.000000,0.000000) [0.000000|15.000000] "" Vector__XXX
 SG_ DiETa_Reserve_Byte7  : 48|8@1+ (1.000000,0.000000) [0.000000|255.000000] "" Vector__XXX
 SG_ DiETa_Reserve_Byte8  : 56|8@1+ (1.000000,0.000000) [0.000000|255.000000] "" Vector__XXX

BO_ 1520 Dimmung_01: 8 ICAS1_Gateway
 SG_ DI_KL_58xd  : 0|8@1+ (1.000000,0.000000) [0.000000|253.000000] "" Airbag Schaltbetaetigung
 SG_ DI_KL_58xs  : 8|7@1+ (1.000000,0.000000) [0.000000|100.000000] "Unit_PerCent" Airbag
 SG_ DI_Display_Nachtdesign  : 15|1@1+ (1.000000,0.000000) [0.000000|1.000000] "" Vector__XXX
 SG_ DI_KL_58xt  : 16|7@1+ (1.000000,0.000000) [0.000000|100.000000] "Unit_PerCent" Airbag Schaltbetaetigung
 SG_ DI_Fotosensor  : 24|16@1+ (1.000000,0.000000) [0.000000|65535.000000] "" Vector__XXX
 SG_ BCM1_Stellgroesse_Kl_58s  : 40|7@1+ (1.000000,0.000000) [0.000000|100.000000] "" Vector__XXX

BO_ 420 EA_01: 8 ICAS1_Gateway
 SG_ EA_01_CRC  : 0|8@1+ (1.000000,0.000000) [0.000000|255.000000] "" Motor_BEV
 SG_ EA_01_BZ  : 8|4@1+ (1.000000,0.000000) [0.000000|15.000000] "" Motor_BEV
 SG_ EA_Parken_beibehalten_HMS  : 12|2@1+ (1.000000,0.000000) [0.000000|3.000000] "" Vector__XXX
 SG_ EA_Ruckstaerke  : 14|2@1+ (1.000000,0.000000) [0.000000|3.000000] "" Vector__XXX
 SG_ EA_Warnruckprofil  : 28|3@1+ (1.000000,0.000000) [0.000000|7.000000] "" Vector__XXX
 SG_ EA_aktiv_laengs  : 38|2@1+ (1.000000,0.000000) [0.000000|3.000000] "" Motor_BEV
 SG_ EA_Funktionsstatus  : 40|4@1+ (1.000000,0.000000) [0.000000|15.000000] "" Motor_BEV
 SG_ EA_Gurtstraffer_Anf  : 44|2@1+ (1.000000,0.000000) [0.000000|3.000000] "" Airbag
 SG_ EA_Anf_Prefill  : 46|1@1+ (1.000000,0.000000) [0.000000|1.000000] "" Vector__XXX
 SG_ EA_Anforderung_HMS  : 48|3@1+ (1.000000,0.000000) [0.000000|7.000000] "" Vector__XXX
 SG_ EA_Ruckfreigabe  : 51|1@1+ (1.000000,0.000000) [0.000000|1.000000] "" Vector__XXX
 SG_ EA_01_Sendestatus  : 52|1@1+ (1.000000,0.000000) [0.000000|1.000000] "" Vector__XXX
 SG_ EA_Sollbeschleunigung  : 53|11@1+ (0.005000,-7.220000) [-7.220000|3.005000] "Unit_MeterPerSeconSquar" Motor_BEV

BO_ 374 EBKV_03: 8 ICAS1_Gateway
 SG_ EBKV_03_CRC  : 0|8@1+ (1.000000,0.000000) [0.000000|255.000000] "" Vector__XXX
 SG_ EBKV_03_BZ  : 8|4@1+ (1.000000,0.000000) [0.000000|15.000000] "" Vector__XXX
 SG_ EBKV_Activate_Fallback_ESP  : 12|1@1+ (1.000000,0.000000) [0.000000|1.000000] "" Vector__XXX
 SG_ EBKV_Restdruckabsenkung  : 13|3@1+ (1.000000,0.000000) [0.000000|7.000000] "" Vector__XXX
 SG_ EBKV_Status_02  : 16|4@1+ (1.000000,0.000000) [0.000000|15.000000] "" Vector__XXX
 SG_ EBKV_Diagnose  : 20|1@1+ (1.000000,0.000000) [0.000000|1.000000] "" Vector__XXX
 SG_ EBKV_Fahrer_bremst  : 21|1@1+ (1.000000,0.000000) [0.000000|1.000000] "" Motor_BEV
 SG_ EBKV_QBit_Fahrer_bremst  : 22|1@1+ (1.000000,0.000000) [0.000000|1.000000] "" Motor_BEV
 SG_ EBKV_Fahrer_bremst_deutlich  : 23|1@1+ (1.000000,0.000000) [0.000000|1.000000] "" Vector__XXX
 SG_ EBKV_OBD_Status  : 24|1@1+ (1.000000,0.000000) [0.000000|1.000000] "" Motor_BEV
 SG_ EBKV_VMM_Sek_Notstopp_Status  : 25|3@1+ (1.000000,0.000000) [0.000000|7.000000] "" Vector__XXX
 SG_ EBKV_Anforderung_HMS  : 28|3@1+ (1.000000,0.000000) [0.000000|7.000000] "" Vector__XXX
 SG_ SBS_Anforderung_GE  : 31|1@1+ (1.000000,0.000000) [0.000000|1.000000] "" Vector__XXX
 SG_ EPB_Status_ext  : 32|3@1+ (1.000000,0.000000) [0.000000|7.000000] "" Motor_BEV
 SG_ EBKV_Bremspedalweg  : 40|8@1+ (0.400000,-0.400000) [0.000000|101.200000] "Unit_PerCent" Motor_BEV
 SG_ EBKV_Kraftblending_Reserve  : 48|8@1+ (0.500000,0.000000) [0.000000|125.000000] "Unit_Bar" Vector__XXX
 SG_ EBKV_Aussteuerdruck  : 56|8@1+ (1.000000,0.000000) [0.000000|250.000000] "Unit_Bar" Vector__XXX

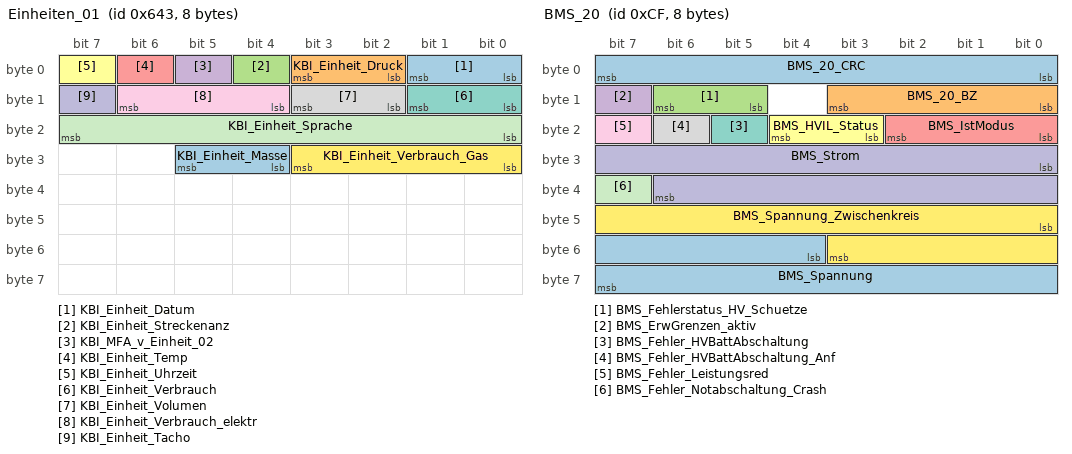
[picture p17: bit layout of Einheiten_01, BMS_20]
BO_ 1603 Einheiten_01: 8 ICAS1_KommunikationsServer
 SG_ KBI_Einheit_Datum  : 0|2@1+ (1.000000,0.000000) [0.000000|3.000000] "" Vector__XXX
 SG_ KBI_Einheit_Druck  : 2|2@1+ (1.000000,0.000000) [0.000000|3.000000] "" Vector__XXX
 SG_ KBI_Einheit_Streckenanz  : 4|1@1+ (1.000000,0.000000) [0.000000|1.000000] "" Vector__XXX
 SG_ KBI_MFA_v_Einheit_02  : 5|1@1+ (1.000000,0.000000) [0.000000|1.000000] "" Motor_BEV
 SG_ KBI_Einheit_Temp  : 6|1@1+ (1.000000,0.000000) [0.000000|1.000000] "" Vector__XXX
 SG_ KBI_Einheit_Uhrzeit  : 7|1@1+ (1.000000,0.000000) [0.000000|1.000000] "" Vector__XXX
 SG_ KBI_Einheit_Verbrauch  : 8|2@1+ (1.000000,0.000000) [0.000000|3.000000] "" Vector__XXX
 SG_ KBI_Einheit_Volumen  : 10|2@1+ (1.000000,0.000000) [0.000000|3.000000] "" Vector__XXX
 SG_ KBI_Einheit_Verbrauch_elektr  : 12|3@1+ (1.000000,0.000000) [0.000000|7.000000] "" Vector__XXX
 SG_ KBI_Einheit_Tacho  : 15|1@1+ (1.000000,0.000000) [0.000000|1.000000] "" Motor_BEV
 SG_ KBI_Einheit_Sprache  : 16|8@1+ (1.000000,0.000000) [0.000000|255.000000] "" Vector__XXX
 SG_ KBI_Einheit_Verbrauch_Gas  : 24|4@1+ (1.000000,0.000000) [0.000000|15.000000] "" Vector__XXX
 SG_ KBI_Einheit_Masse  : 28|2@1+ (1.000000,0.000000) [0.000000|3.000000] "" Vector__XXX

BU_:  Airbag BAP_Tester ICAS1_Gateway ICAS1_KommunikationsServer LE1 LE2 Motor_BEV Schaltbetaetigung

BO_ 207 BMS_20: 8 ICAS1_Gateway
 SG_ BMS_20_CRC  : 0|8@1+ (1.000000,0.000000) [0.000000|255.000000] "" Motor_BEV
 SG_ BMS_20_BZ  : 8|4@1+ (1.000000,0.000000) [0.000000|15.000000] "" Motor_BEV
 SG_ BMS_Fehlerstatus_HV_Schuetze  : 13|2@1+ (1.000000,0.000000) [0.000000|3.000000] "" Motor_BEV
 SG_ BMS_ErwGrenzen_aktiv  : 15|1@1+ (1.000000,0.000000) [0.000000|1.000000] "" Motor_BEV
 SG_ BMS_IstModus  : 16|3@1+ (1.000000,0.000000) [0.000000|7.000000] "" LE1 LE2 Motor_BEV
 SG_ BMS_HVIL_Status  : 19|2@1+ (1.000000,0.000000) [0.000000|3.000000] "" Motor_BEV
 SG_ BMS_Fehler_HVBattAbschaltung  : 21|1@1+ (1.000000,0.000000) [0.000000|1.000000] "" Motor_BEV
 SG_ BMS_Fehler_HVBattAbschaltung_Anf  : 22|1@1+ (1.000000,0.000000) [0.000000|1.000000] "" Motor_BEV
 SG_ BMS_Fehler_Leistungsred  : 23|1@1+ (1.000000,0.000000) [0.000000|1.000000] "" Motor_BEV
 SG_ BMS_Strom  : 24|15@1+ (0.100000,-1630.000000) [-1630.000000|1630.000000] "Unit_Amper" Motor_BEV
 SG_ BMS_Fehler_Notabschaltung_Crash  : 39|1@1+ (1.000000,0.000000) [0.000000|1.000000] "" Vector__XXX
 SG_ BMS_Spannung_Zwischenkreis  : 40|12@1+ (0.500000,-1000.000000) [-1000.000000|1000.000000] "Unit_Volt" Motor_BEV
 SG_ BMS_Spannung  : 52|12@1+ (0.250000,0.000000) [0.000000|1000.000000] "Unit_Volt" Motor_BEV

BO_ 2463978704 BMS_21: 8 ICAS1_Gateway
 SG_ BMS_Max_Entladestrom  : 12|13@1+ (0.200000,0.000000) [0.000000|1630.000000] "Unit_Amper" Motor_BEV
 SG_ BMS_Max_Ladestrom  : 25|13@1+ (0.200000,0.000000) [0.000000|1630.000000] "Unit_Amper" Motor_BEV
 SG_ BMS_Max_Entladeleistung  : 38|13@1+ (100.000000,0.000000) [0.000000|818000.000000] "Unit_Watt" Motor_BEV
 SG_ BMS_Max_Ladeleistung  : 51|13@1+ (100.000000,0.000000) [0.000000|818000.000000] "Unit_Watt" Motor_BEV

BO_ 2463978705 BMS_22: 8 ICAS1_Gateway
 SG_ BMS_Status_EoHVL_Heizer  : 15|2@1+ (1.000000,0.000000) [0.000000|3.000000] "" Motor_BEV
 SG_ BMS_Ladezustand  : 17|11@1+ (0.050000,0.000000) [0.000000|100.000000] "Unit_PerCent" Motor_BEV
 SG_ BMS_PerfInd_Entladen  : 28|10@1+ (0.200000,0.000000) [0.000000|200.000000] "Unit_PerCent" Motor_BEV
 SG_ BMS_PerfInd_Laden  : 38|10@1+ (0.200000,0.000000) [0.000000|200.000000] "Unit_PerCent" Motor_BEV
 SG_ BMS_Nutzbare_EntladeEnergie  : 48|16@1+ (5.000000,0.000000) [0.000000|327400.000000] "Unit_WattHour" Motor_BEV

BO_ 2589283664 BMS_24: 8 ICAS1_Gateway
 SG_ BMS_Balancing_Aktiv  : 14|2@1+ (1.000000,0.000000) [0.000000|3.000000] "" Vector__XXX
 SG_ BMS_Ladevorgang_aktiv  : 16|1@1+ (1.000000,0.000000) [0.000000|1.000000] "" Vector__XXX
 SG_ BMS_RIso_Ext  : 17|12@1+ (5.000000,0.000000) [0.000000|20465.000000] "Unit_KiloOhm" Motor_BEV
 SG_ BMS_Min_Ladezustand  : 29|11@1+ (0.050000,0.000000) [0.000000|100.000000] "Unit_PerCent" Motor_BEV
 SG_ BMS_Max_Energie  : 40|13@1+ (40.000000,0.000000) [0.000000|327400.000000] "Unit_WattHour" Motor_BEV
 SG_ BMS_Max_Ladezustand  : 53|11@1+ (0.050000,0.000000) [0.000000|100.000000] "Unit_PerCent" Motor_BEV

BO_ 2589283665 BMS_25: 8 ICAS1_Gateway
 SG_ BMS_BattHeizung_VerbautStatus  : 13|1@1+ (1.000000,0.000000) [0.000000|1.000000] "" Motor_BEV
 SG_ BMS_Fehler_NTKreis  : 14|1@1+ (1.000000,0.000000) [0.000000|1.000000] "" Vector__XXX
 SG_ BMS_Temperierung_Anf  : 15|3@1+ (1.000000,0.000000) [0.000000|7.000000] "" Motor_BEV
 SG_ BMS_Status_Ventil1  : 18|3@1+ (1.000000,0.000000) [0.000000|7.000000] "" Motor_BEV
 SG_ BMS_Status_Ventil2  : 21|3@1+ (1.000000,0.000000) [0.000000|7.000000] "" Motor_BEV
 SG_ BMS_Pumpe1_Ansteuerung  : 24|4@1+ (10.000000,0.000000) [0.000000|100.000000] "Unit_PerCent" Motor_BEV
 SG_ BMS_Pumpe2_Ansteuerung  : 28|4@1+ (10.000000,0.000000) [0.000000|100.000000] "Unit_PerCent" Motor_BEV
 SG_ BMS_VorlaufTemperatur  : 32|8@1+ (0.500000,-40.000000) [-40.000000|86.000000] "Unit_DegreCelsi" Motor_BEV
 SG_ BMS_Temperatur  : 40|8@1+ (0.500000,-40.000000) [-40.000000|86.500000] "Unit_DegreCelsi" Motor_BEV
 SG_ BMS_SollVorlauftemperatur  : 48|8@1+ (0.500000,-40.000000) [-40.000000|86.500000] "Unit_DegreCelsi" Motor_BEV
 SG_ BMS_RuecklaufTemperatur  : 56|8@1+ (0.500000,-40.000000) [-40.000000|86.000000] "Unit_DegreCelsi" Motor_BEV

BO_ 2589283760 BMS_26: 8 ICAS1_Gateway
 SG_ BMS_Max_Spannung  : 20|10@1+ (1.000000,0.000000) [0.000000|1000.000000] "Unit_Volt" Motor_BEV
 SG_ BMS_Min_Spannung  : 30|10@1+ (1.000000,0.000000) [0.000000|1000.000000] "Unit_Volt" Motor_BEV
 SG_ BMS_Dauer_Entladeleistung  : 40|12@1+ (200.000000,0.000000) [0.000000|818000.000000] "Unit_Watt" Motor_BEV
 SG_ BMS_Dauer_Ladeleistung  : 52|12@1+ (200.000000,0.000000) [0.000000|818000.000000] "Unit_Watt" Motor_BEV

BO_ 2463978646 Charisma_11: 24 ICAS1_Gateway
 SG_ CHA_Ziel_FahrPr_AGA  : 0|4@1+ (1.000000,0.000000) [0.000000|15.000000] "" Vector__XXX
 SG_ CHA_Ziel_FahrPr_ESP  : 4|4@1+ (1.000000,0.000000) [0.000000|15.000000] "" Motor_BEV
 SG_ CHA_Ziel_FahrPr_Freilauf  : 8|4@1+ (1.000000,0.000000) [0.000000|15.000000] "" Vector__XXX
 SG_ CHA_Fahrer_Umschaltung  : 14|1@1+ (1.000000,0.000000) [0.000000|1.000000] "" Motor_BEV
 SG_ CHA_Fahrer_Umschaltung_BMA  : 15|1@1+ (1.000000,0.000000) [0.000000|1.000000] "" Vector__XXX
 SG_ CHA_Ziel_FahrPr_MO  : 16|4@1+ (1.000000,0.000000) [0.000000|15.000000] "" Motor_BEV
 SG_ CHA_Ziel_FahrPr_GE  : 20|4@1+ (1.000000,0.000000) [0.000000|15.000000] "" Vector__XXX
 SG_ CHA_Ziel_FahrPr_ALR  : 24|4@1+ (1.000000,0.000000) [0.000000|15.000000] "" Motor_BEV
 SG_ CHA_Ziel_FahrPr_MO_BZS  : 28|4@1+ (1.000000,0.000000) [0.000000|15.000000] "" Vector__XXX
 SG_ CHA_Ziel_FahrPr_DR  : 32|4@1+ (1.000000,0.000000) [0.000000|15.000000] "" Vector__XXX
 SG_ CHA_Ziel_FahrPr_VAQ  : 36|4@1+ (1.000000,0.000000) [0.000000|15.000000] "" Vector__XXX
 SG_ CHA_Ziel_FahrPr_AFS  : 40|4@1+ (1.000000,0.000000) [0.000000|15.000000] "" Vector__XXX
 SG_ CHA_Ziel_FahrPr_PreCrash  : 44|4@1+ (1.000000,0.000000) [0.000000|15.000000] "" Airbag
 SG_ CHA_Ziel_FahrPr_EPS  : 48|4@1+ (1.000000,0.000000) [0.000000|15.000000] "" Vector__XXX
 SG_ CHA_Ziel_FahrPr_ACC  : 52|4@1+ (1.000000,0.000000) [0.000000|15.000000] "" Vector__XXX
 SG_ CHA_Ziel_FahrPr_SAK  : 56|4@1+ (1.000000,0.000000) [0.000000|15.000000] "" Vector__XXX
 SG_ CHA_Ziel_FahrPr_MO_StSt  : 60|4@1+ (1.000000,0.000000) [0.000000|15.000000] "" Vector__XXX
 SG_ CHA_Ziel_FahrPr_EBKV  : 64|4@1+ (1.000000,0.000000) [0.000000|15.000000] "" Vector__XXX
 SG_ CHA_Ziel_FahrPr_IL  : 68|4@1+ (1.000000,0.000000) [0.000000|15.000000] "" Vector__XXX
 SG_ CHA_Current_Mode  : 72|4@1+ (1.000000,0.000000) [0.000000|15.000000] "" Vector__XXX
 SG_ CHA_Ziel_FahrPr_QS  : 80|4@1+ (1.000000,0.000000) [0.000000|15.000000] "" Vector__XXX
 SG_ CHA_Ziel_FahrPr_SCU  : 84|4@1+ (1.000000,0.000000) [0.000000|15.000000] "" Vector__XXX
 SG_ CHA_Ziel_FahrPr_HAL  : 88|4@1+ (1.000000,0.000000) [0.000000|15.000000] "" Vector__XXX
 SG_ CHA_Ziel_FahrPr_NR  : 92|4@1+ (1.000000,0.000000) [0.000000|15.000000] "" Vector__XXX
 SG_ CHA_Ziel_FahrPr_AV  : 96|4@1+ (1.000000,0.000000) [0.000000|15.000000] "" Vector__XXX
 SG_ CHA_Ziel_FahrPr_MXB  : 100|4@1+ (1.000000,0.000000) [0.000000|15.000000] "" Vector__XXX
 SG_ CHA_Ziel_FahrPr_AFR  : 104|4@1+ (1.000000,0.000000) [0.000000|15.000000] "" Vector__XXX
 SG_ CHA_Ziel_FahrPr_HDC  : 108|4@1+ (1.000000,0.000000) [0.000000|15.000000] "" Vector__XXX
 SG_ CHA_Ziel_FahrPr_EAR  : 112|4@1+ (1.000000,0.000000) [0.000000|15.000000] "" Vector__XXX
 SG_ CHA_Ziel_FahrPr_AEB  : 116|4@1+ (1.000000,0.000000) [0.000000|15.000000] "" Vector__XXX
 SG_ CHA_Ziel_FahrPr_FCWO  : 120|4@1+ (1.000000,0.000000) [0.000000|15.000000] "" Vector__XXX
 SG_ CHA_Ziel_FahrPr_FCWP  : 124|4@1+ (1.000000,0.000000) [0.000000|15.000000] "" Vector__XXX
 SG_ CHA_Ziel_FahrPr_ToS_laengs  : 144|4@1+ (1.000000,0.000000) [0.000000|15.000000] "" Vector__XXX
 SG_ CHA_Ziel_FahrPr_ToS_quer  : 148|4@1+ (1.000000,0.000000) [0.000000|15.000000] "" Vector__XXX
 SG_ CHA_Ziel_FahrPr_mFDR  : 152|4@1+ (1.000000,0.000000) [0.000000|15.000000] "" Vector__XXX
 SG_ CHA_Ziel_FahrPr_Reku_ZwGas  : 156|4@1+ (1.000000,0.000000) [0.000000|15.000000] "" Vector__XXX
 SG_ CHA_Ziel_FahrPr_MO_Freilauf  : 160|4@1+ (1.000000,0.000000) [0.000000|15.000000] "" Vector__XXX
 SG_ CHA_Ziel_FahrPr_BMS  : 164|4@1+ (1.000000,0.000000) [0.000000|15.000000] "" Vector__XXX
 SG_ CHA_Current_Mode_BMA  : 168|4@1+ (1.000000,0.000000) [0.000000|15.000000] "" Vector__XXX
 SG_ CHA_Ziel_FahrPr_PDC  : 172|4@1+ (1.000000,0.000000) [0.000000|15.000000] "" Vector__XXX
 SG_ CHA_Ziel_FahrPr_HHC  : 176|4@1+ (1.000000,0.000000) [0.000000|15.000000] "" Vector__XXX
 SG_ CHA_Ziel_FahrPr_EDS  : 180|4@1+ (1.000000,0.000000) [0.000000|15.000000] "" Vector__XXX
 SG_ CHA_Ziel_FahrPr_PACC  : 184|4@1+ (1.000000,0.000000) [0.000000|15.000000] "" Vector__XXX
 SG_ CHA_Ziel_FahrPr_AGK  : 188|4@1+ (1.000000,0.000000) [0.000000|15.000000] "" Vector__XXX

BO_ 514 Daempfer_03: 32 ICAS1_Gateway
 SG_ DR_Aufbaubeschleunigung_HR  : 12|10@1+ (0.032700,-15.696000) [-15.696000|15.696000] "Unit_MeterPerSeconSquar" Motor_BEV
 SG_ DR_Aufbaubeschleunigung_VR  : 22|10@1+ (0.032700,-15.696000) [-15.696000|15.696000] "Unit_MeterPerSeconSquar" Motor_BEV
 SG_ DR_Aufbaubeschleunigung_VL  : 32|10@1+ (0.032700,-15.696000) [-15.696000|15.696000] "Unit_MeterPerSeconSquar" Motor_BEV
 SG_ DR_Aufbaubeschleunigung_HL  : 42|10@1+ (0.032700,-15.696000) [-15.696000|15.696000] "Unit_MeterPerSeconSquar" Motor_BEV
 SG_ DR_Funktionsstatus  : 52|2@1+ (1.000000,0.000000) [0.000000|3.000000] "" Vector__XXX
 SG_ DR_Drehwinkelsensortausch_VL  : 72|2@1+ (1.000000,0.000000) [1.000000|3.000000] "" Vector__XXX
 SG_ DR_Drehwinkelsensortausch_VR  : 74|2@1+ (1.000000,0.000000) [1.000000|3.000000] "" Vector__XXX
 SG_ DR_Drehwinkelsensortausch_HL  : 76|2@1+ (1.000000,0.000000) [1.000000|3.000000] "" Vector__XXX
 SG_ DR_Drehwinkelsensortausch_HR  : 78|2@1+ (1.000000,0.000000) [1.000000|3.000000] "" Vector__XXX
 SG_ DR_Drehwinkel_VL  : 80|12@1+ (0.088000,0.000000) [0.000000|359.920000] "" Vector__XXX
 SG_ DR_Drehwinkel_VR  : 92|12@1+ (0.088000,0.000000) [0.000000|359.920000] "" Vector__XXX
 SG_ DR_Drehwinkel_HL  : 104|12@1+ (0.088000,0.000000) [0.000000|359.920000] "" Vector__XXX
 SG_ DR_Drehwinkel_HR  : 116|12@1+ (0.088000,0.000000) [0.000000|359.920000] "" Vector__XXX

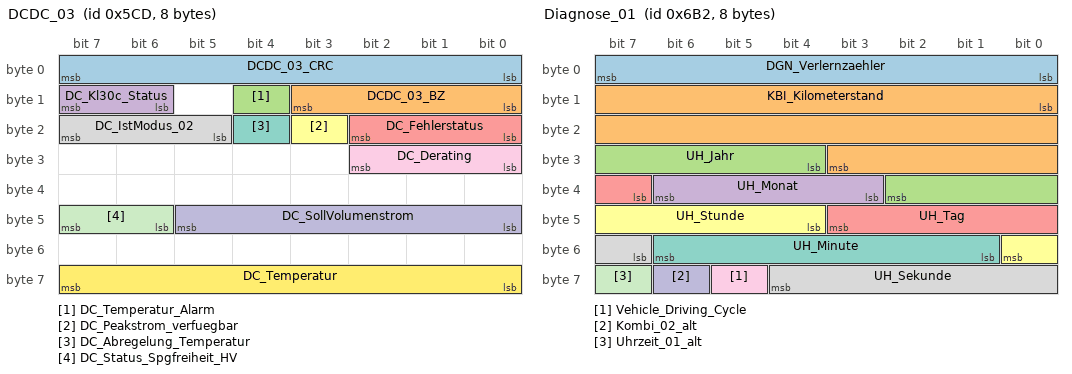
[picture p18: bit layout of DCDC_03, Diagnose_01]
BO_ 1485 DCDC_03: 8 ICAS1_Gateway
 SG_ DCDC_03_CRC  : 0|8@1+ (1.000000,0.000000) [0.000000|255.000000] "" Motor_BEV
 SG_ DCDC_03_BZ  : 8|4@1+ (1.000000,0.000000) [0.000000|15.000000] "" Motor_BEV
 SG_ DC_Temperatur_Alarm  : 12|1@1+ (1.000000,0.000000) [0.000000|1.000000] "" Vector__XXX
 SG_ DC_Kl30c_Status  : 14|2@1+ (1.000000,0.000000) [0.000000|3.000000] "" Motor_BEV
 SG_ DC_Fehlerstatus  : 16|3@1+ (1.000000,0.000000) [0.000000|7.000000] "" Vector__XXX
 SG_ DC_Peakstrom_verfuegbar  : 19|1@1+ (1.000000,0.000000) [0.000000|1.000000] "" Vector__XXX
 SG_ DC_Abregelung_Temperatur  : 20|1@1+ (1.000000,0.000000) [0.000000|1.000000] "" Vector__XXX
 SG_ DC_IstModus_02  : 21|3@1+ (1.000000,0.000000) [0.000000|7.000000] "" Vector__XXX
 SG_ DC_Derating  : 24|3@1+ (1.000000,0.000000) [0.000000|7.000000] "" Vector__XXX
 SG_ DC_SollVolumenstrom  : 40|6@1+ (0.500000,0.000000) [0.000000|30.500000] "Unit_LiterPerMinut" Motor_BEV
 SG_ DC_Status_Spgfreiheit_HV  : 46|2@1+ (1.000000,0.000000) [0.000000|3.000000] "" Vector__XXX
 SG_ DC_Temperatur  : 56|8@1+ (1.000000,-40.000000) [-40.000000|213.000000] "Unit_DegreCelsi" Motor_BEV

BO_ 247 DCDC_04: 8 ICAS1_Gateway
 SG_ DCDC_04_CRC  : 0|8@1+ (1.000000,0.000000) [0.000000|255.000000] "" Vector__XXX
 SG_ DCDC_04_BZ  : 8|4@1+ (1.000000,0.000000) [0.000000|15.000000] "" Vector__XXX
 SG_ DC_Vorladung_Status  : 34|1@1+ (1.000000,0.000000) [0.000000|1.000000] "" Motor_BEV
 SG_ DC_Fehler_extern  : 35|1@1+ (1.000000,0.000000) [0.000000|1.000000] "" Motor_BEV
 SG_ DC_Fehler_intern  : 36|1@1+ (1.000000,0.000000) [0.000000|1.000000] "" Motor_BEV
 SG_ DC_Status_Spgfreiheit  : 37|2@1+ (1.000000,0.000000) [0.000000|3.000000] "" Motor_BEV
 SG_ DC_Status_EoHVL  : 39|2@1+ (1.000000,0.000000) [0.000000|3.000000] "" Motor_BEV
 SG_ DC_IstModus_02  : 41|3@1+ (1.000000,0.000000) [0.000000|7.000000] "" Motor_BEV
 SG_ DC_IstStrom_HV  : 44|10@1+ (0.100000,-51.100000) [-51.100000|51.000000] "Unit_Amper" Motor_BEV
 SG_ DC_IstLeistung_HV  : 54|10@1+ (10.000000,-4000.000000) [-4000.000000|6210.000000] "Unit_Watt" Motor_BEV

BO_ 2617027088 DEV_Airbag_ASM_01: 8 Airbag
 SG_ DEV_Airbag_ASM_01_Data  : 0|64@1+ (1.000000,0.000000) [0.000000|18446744073709551616.000000] "" Vector__XXX

BO_ 2617027072 DEV_Airbag_Resp_00: 8 Airbag
 SG_ DEV_Airbag_Resp_00_Data  : 0|64@1+ (1.000000,0.000000) [0.000000|18446744073709551616.000000] "" Vector__XXX

BO_ 2617027073 DEV_Airbag_Resp_01: 8 Airbag
 SG_ DEV_Airbag_Resp_01_Data  : 0|64@1+ (1.000000,0.000000) [0.000000|18446744073709551616.000000] "" Vector__XXX

BO_ 2617027074 DEV_Airbag_Resp_02: 8 Airbag
 SG_ DEV_Airbag_Resp_02_Data  : 0|64@1+ (1.000000,0.000000) [0.000000|18446744073709551616.000000] "" Vector__XXX

BO_ 2617027075 DEV_Airbag_Resp_03: 8 Airbag
 SG_ DEV_Airbag_Resp_03_Data  : 0|64@1+ (1.000000,0.000000) [0.000000|18446744073709551616.000000] "" Vector__XXX

BO_ 2617027076 DEV_Airbag_Resp_04: 8 Airbag
 SG_ DEV_Airbag_Resp_04_Data  : 0|64@1+ (1.000000,0.000000) [0.000000|18446744073709551616.000000] "" Vector__XXX

BO_ 2617027077 DEV_Airbag_Resp_05: 8 Airbag
 SG_ DEV_Airbag_Resp_05_Data  : 0|64@1+ (1.000000,0.000000) [0.000000|18446744073709551616.000000] "" Vector__XXX

BO_ 2617027078 DEV_Airbag_Resp_06: 8 Airbag
 SG_ DEV_Airbag_Resp_06_Data  : 0|64@1+ (1.000000,0.000000) [0.000000|18446744073709551616.000000] "" Vector__XXX

BO_ 2617027079 DEV_Airbag_Resp_07: 8 Airbag
 SG_ DEV_Airbag_Resp_07_Data  : 0|64@1+ (1.000000,0.000000) [0.000000|18446744073709551616.000000] "" Vector__XXX

BO_ 2617027080 DEV_Airbag_Resp_08: 8 Airbag
 SG_ DEV_Airbag_Resp_08_Data  : 0|64@1+ (1.000000,0.000000) [0.000000|18446744073709551616.000000] "" Vector__XXX

BO_ 2617027081 DEV_Airbag_Resp_09: 8 Airbag
 SG_ DEV_Airbag_Resp_09_Data  : 0|64@1+ (1.000000,0.000000) [0.000000|18446744073709551616.000000] "" Vector__XXX

BO_ 2617027082 DEV_Airbag_Resp_10: 8 Airbag
 SG_ DEV_Airbag_Resp_10_Data  : 0|64@1+ (1.000000,0.000000) [0.000000|18446744073709551616.000000] "" Vector__XXX

BO_ 2617027083 DEV_Airbag_Resp_11: 8 Airbag
 SG_ DEV_Airbag_Resp_11_Data  : 0|64@1+ (1.000000,0.000000) [0.000000|18446744073709551616.000000] "" Vector__XXX

BO_ 2617154048 DEV_Waehlhebel_Resp_00: 8 Schaltbetaetigung
 SG_ DEV_Waehlhebel_Resp_00_Data  : 0|64@1+ (1.000000,0.000000) [0.000000|18446744073709551616.000000] "" Vector__XXX

BO_ 2617154049 DEV_Waehlhebel_Resp_01: 8 Schaltbetaetigung
 SG_ DEV_Waehlhebel_Resp_01_Data  : 0|64@1+ (1.000000,0.000000) [0.000000|18446744073709551616.000000] "" Vector__XXX

BO_ 2617154050 DEV_Waehlhebel_Resp_02: 8 Schaltbetaetigung
 SG_ DEV_Waehlhebel_Resp_02_Data  : 0|64@1+ (1.000000,0.000000) [0.000000|18446744073709551616.000000] "" Vector__XXX

BO_ 2617154051 DEV_Waehlhebel_Resp_03: 8 Schaltbetaetigung
 SG_ DEV_Waehlhebel_Resp_03_Data  : 0|64@1+ (1.000000,0.000000) [0.000000|18446744073709551616.000000] "" Vector__XXX

BO_ 2617154052 DEV_Waehlhebel_Resp_04: 8 Schaltbetaetigung
 SG_ DEV_Waehlhebel_Resp_04_Data  : 0|64@1+ (1.000000,0.000000) [0.000000|18446744073709551616.000000] "" Vector__XXX

BO_ 2617154053 DEV_Waehlhebel_Resp_05: 8 Schaltbetaetigung
 SG_ DEV_Waehlhebel_Resp_05_Data  : 0|64@1+ (1.000000,0.000000) [0.000000|18446744073709551616.000000] "" Vector__XXX

BO_ 2549876269 Diag_Waehlhebel_Req: 8 Motor_BEV
 SG_ Diag_Waehlhebel_Req_Data  : 0|64@1+ (1.000000,0.000000) [0.000000|18446744073709551616.000000] "" Schaltbetaetigung

BO_ 2550007341 Diag_Waehlhebel_Resp: 8 Schaltbetaetigung
 SG_ Diag_Waehlhebel_Resp_Data  : 0|64@1+ (1.000000,0.000000) [0.000000|18446744073709551616.000000] "" Motor_BEV

BO_ 1714 Diagnose_01: 8 ICAS1_Gateway
 SG_ DGN_Verlernzaehler  : 0|8@1+ (1.000000,0.000000) [0.000000|254.000000] "" Airbag LE1 LE2 Motor_BEV
 SG_ KBI_Kilometerstand  : 8|20@1+ (1.000000,0.000000) [0.000000|1048573.000000] "Unit_KiloMeter" Airbag LE1 LE2 Motor_BEV
 SG_ UH_Jahr  : 28|7@1+ (1.000000,2000.000000) [2000.000000|2127.000000] "Unit_Year" Airbag LE1 LE2 Motor_BEV
 SG_ UH_Monat  : 35|4@1+ (1.000000,0.000000) [1.000000|12.000000] "Unit_Month" Airbag LE1 LE2 Motor_BEV
 SG_ UH_Tag  : 39|5@1+ (1.000000,0.000000) [1.000000|31.000000] "Unit_Day" Airbag LE1 LE2 Motor_BEV
 SG_ UH_Stunde  : 44|5@1+ (1.000000,0.000000) [0.000000|23.000000] "Unit_Hours" Airbag LE1 LE2 Motor_BEV
 SG_ UH_Minute  : 49|6@1+ (1.000000,0.000000) [0.000000|59.000000] "Unit_Minut" Airbag LE1 LE2 Motor_BEV
 SG_ UH_Sekunde  : 55|6@1+ (1.000000,0.000000) [0.000000|59.000000] "Unit_Secon" Airbag LE1 LE2 Motor_BEV
 SG_ Vehicle_Driving_Cycle  : 61|1@1+ (1.000000,0.000000) [0.000000|1.000000] "" Airbag
 SG_ Kombi_02_alt  : 62|1@1+ (1.000000,0.000000) [0.000000|1.000000] "" Vector__XXX
 SG_ Uhrzeit_01_alt  : 63|1@1+ (1.000000,0.000000) [0.000000|1.000000] "" Vector__XXX

BO_ 851 DiETa_01: 8 ICAS1_Gateway
 SG_ DiETas_01_CRC  : 0|8@1+ (1.000000,0.000000) [0.000000|255.000000] "" Airbag
 SG_ DiETas_01_BZ  : 8|4@1+ (1.000000,0.000000) [0.000000|15.000000] "" Airbag
 SG_ DiETa_Reserve_Byte2_4  : 12|1@1+ (1.000000,0.000000) [0.000000|1.000000] "" Vector__XXX
 SG_ DiETa_Status  : 13|2@1+ (1.000000,0.000000) [0.000000|3.000000] "" Airbag
 SG_ DiETa_ResponseError  : 15|1@1+ (1.000000,0.000000) [0.000000|1.000000] "" Vector__XXX
 SG_ DiETa_Car  : 16|2@1+ (1.000000,0.000000) [0.000000|3.000000] "" Vector__XXX
 SG_ DiETa_Klima  : 18|2@1+ (1.000000,0.000000) [0.000000|3.000000] "" Vector__XXX
 SG_ DiETa_Mode  : 20|2@1+ (1.000000,0.000000) [0.000000|3.000000] "" Vector__XXX
 SG_ DiETa_Parken  : 22|2@1+ (1.000000,0.000000) [0.000000|3.000000] "" Vector__XXX
 SG_ DiETa_FSH_Taste  : 24|2@1+ (1.000000,0.000000) [0.000000|3.000000] "" Vector__XXX
 SG_ DiETa_HSH_Taste  : 26|2@1+ (1.000000,0.000000) [0.000000|3.000000] "" Vector__XXX
 SG_ DiETa_Warnblink_Taste  : 28|2@1+ (1.000000,0.000000) [0.000000|3.000000] "" Vector__XXX
 SG_ DiETa_FAS_Stufe  : 30|2@1+ (1.000000,0.000000) [0.000000|3.000000] "" Vector__XXX
 SG_ DiETa_PAO_ON_Status  : 32|2@1+ (1.000000,0.000000) [0.000000|3.000000] "" Airbag
 SG_ DiETa_PAO_OFF_Status  : 34|2@1+ (1.000000,0.000000) [0.000000|3.000000] "" Airbag
 SG_ DiETa_Defrost_Taste  : 36|2@1+ (1.000000,0.000000) [0.000000|3.000000] "" Vector__XXX
 SG_ DiETa_Reserve_Byte5_6  : 38|2@1+ (1.000000,0.000000) [0.000000|3.000000] "" Vector__XXX
 SG_ DiETa_Lock_Unlock_Taste  : 40|3@1+ (1.000000,0.000000) [0.000000|7.000000] "" Vector__XXX
 SG_ DiETa_Mode_roh  : 43|1@1+ (1.000000,0.000000) [0.000000|1.000000] "" Vector__XXX
 SG_ DiETa_Reserve_Byte6_3  : 44|4@1+ (1.000000,0.000000) [0.000000|15.000000] "" Vector__XXX
 SG_ DiETa_Reserve_Byte7  : 48|8@1+ (1.000000,0.000000) [0.000000|255.000000] "" Vector__XXX
 SG_ DiETa_Reserve_Byte8  : 56|8@1+ (1.000000,0.000000) [0.000000|255.000000] "" Vector__XXX

BO_ 1520 Dimmung_01: 8 ICAS1_Gateway
 SG_ DI_KL_58xd  : 0|8@1+ (1.000000,0.000000) [0.000000|253.000000] "" Airbag Schaltbetaetigung
 SG_ DI_KL_58xs  : 8|7@1+ (1.000000,0.000000) [0.000000|100.000000] "Unit_PerCent" Airbag
 SG_ DI_Display_Nachtdesign  : 15|1@1+ (1.000000,0.000000) [0.000000|1.000000] "" Vector__XXX
 SG_ DI_KL_58xt  : 16|7@1+ (1.000000,0.000000) [0.000000|100.000000] "Unit_PerCent" Airbag Schaltbetaetigung
 SG_ DI_Fotosensor  : 24|16@1+ (1.000000,0.000000) [0.000000|65535.000000] "" Vector__XXX
 SG_ BCM1_Stellgroesse_Kl_58s  : 40|7@1+ (1.000000,0.000000) [0.000000|100.000000] "" Vector__XXX

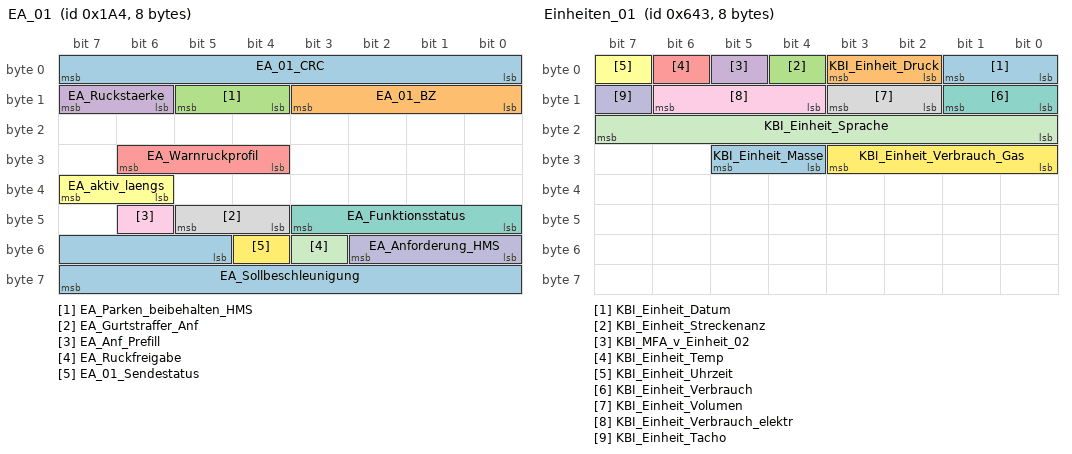
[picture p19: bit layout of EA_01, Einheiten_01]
BO_ 420 EA_01: 8 ICAS1_Gateway
 SG_ EA_01_CRC  : 0|8@1+ (1.000000,0.000000) [0.000000|255.000000] "" Motor_BEV
 SG_ EA_01_BZ  : 8|4@1+ (1.000000,0.000000) [0.000000|15.000000] "" Motor_BEV
 SG_ EA_Parken_beibehalten_HMS  : 12|2@1+ (1.000000,0.000000) [0.000000|3.000000] "" Vector__XXX
 SG_ EA_Ruckstaerke  : 14|2@1+ (1.000000,0.000000) [0.000000|3.000000] "" Vector__XXX
 SG_ EA_Warnruckprofil  : 28|3@1+ (1.000000,0.000000) [0.000000|7.000000] "" Vector__XXX
 SG_ EA_aktiv_laengs  : 38|2@1+ (1.000000,0.000000) [0.000000|3.000000] "" Motor_BEV
 SG_ EA_Funktionsstatus  : 40|4@1+ (1.000000,0.000000) [0.000000|15.000000] "" Motor_BEV
 SG_ EA_Gurtstraffer_Anf  : 44|2@1+ (1.000000,0.000000) [0.000000|3.000000] "" Airbag
 SG_ EA_Anf_Prefill  : 46|1@1+ (1.000000,0.000000) [0.000000|1.000000] "" Vector__XXX
 SG_ EA_Anforderung_HMS  : 48|3@1+ (1.000000,0.000000) [0.000000|7.000000] "" Vector__XXX
 SG_ EA_Ruckfreigabe  : 51|1@1+ (1.000000,0.000000) [0.000000|1.000000] "" Vector__XXX
 SG_ EA_01_Sendestatus  : 52|1@1+ (1.000000,0.000000) [0.000000|1.000000] "" Vector__XXX
 SG_ EA_Sollbeschleunigung  : 53|11@1+ (0.005000,-7.220000) [-7.220000|3.005000] "Unit_MeterPerSeconSquar" Motor_BEV

BO_ 374 EBKV_03: 8 ICAS1_Gateway
 SG_ EBKV_03_CRC  : 0|8@1+ (1.000000,0.000000) [0.000000|255.000000] "" Vector__XXX
 SG_ EBKV_03_BZ  : 8|4@1+ (1.000000,0.000000) [0.000000|15.000000] "" Vector__XXX
 SG_ EBKV_Activate_Fallback_ESP  : 12|1@1+ (1.000000,0.000000) [0.000000|1.000000] "" Vector__XXX
 SG_ EBKV_Restdruckabsenkung  : 13|3@1+ (1.000000,0.000000) [0.000000|7.000000] "" Vector__XXX
 SG_ EBKV_Status_02  : 16|4@1+ (1.000000,0.000000) [0.000000|15.000000] "" Vector__XXX
 SG_ EBKV_Diagnose  : 20|1@1+ (1.000000,0.000000) [0.000000|1.000000] "" Vector__XXX
 SG_ EBKV_Fahrer_bremst  : 21|1@1+ (1.000000,0.000000) [0.000000|1.000000] "" Motor_BEV
 SG_ EBKV_QBit_Fahrer_bremst  : 22|1@1+ (1.000000,0.000000) [0.000000|1.000000] "" Motor_BEV
 SG_ EBKV_Fahrer_bremst_deutlich  : 23|1@1+ (1.000000,0.000000) [0.000000|1.000000] "" Vector__XXX
 SG_ EBKV_OBD_Status  : 24|1@1+ (1.000000,0.000000) [0.000000|1.000000] "" Motor_BEV
 SG_ EBKV_VMM_Sek_Notstopp_Status  : 25|3@1+ (1.000000,0.000000) [0.000000|7.000000] "" Vector__XXX
 SG_ EBKV_Anforderung_HMS  : 28|3@1+ (1.000000,0.000000) [0.000000|7.000000] "" Vector__XXX
 SG_ SBS_Anforderung_GE  : 31|1@1+ (1.000000,0.000000) [0.000000|1.000000] "" Vector__XXX
 SG_ EPB_Status_ext  : 32|3@1+ (1.000000,0.000000) [0.000000|7.000000] "" Motor_BEV
 SG_ EBKV_Bremspedalweg  : 40|8@1+ (0.400000,-0.400000) [0.000000|101.200000] "Unit_PerCent" Motor_BEV
 SG_ EBKV_Kraftblending_Reserve  : 48|8@1+ (0.500000,0.000000) [0.000000|125.000000] "Unit_Bar" Vector__XXX
 SG_ EBKV_Aussteuerdruck  : 56|8@1+ (1.000000,0.000000) [0.000000|250.000000] "Unit_Bar" Vector__XXX

BO_ 1603 Einheiten_01: 8 ICAS1_KommunikationsServer
 SG_ KBI_Einheit_Datum  : 0|2@1+ (1.000000,0.000000) [0.000000|3.000000] "" Vector__XXX
 SG_ KBI_Einheit_Druck  : 2|2@1+ (1.000000,0.000000) [0.000000|3.000000] "" Vector__XXX
 SG_ KBI_Einheit_Streckenanz  : 4|1@1+ (1.000000,0.000000) [0.000000|1.000000] "" Vector__XXX
 SG_ KBI_MFA_v_Einheit_02  : 5|1@1+ (1.000000,0.000000) [0.000000|1.000000] "" Motor_BEV
 SG_ KBI_Einheit_Temp  : 6|1@1+ (1.000000,0.000000) [0.000000|1.000000] "" Vector__XXX
 SG_ KBI_Einheit_Uhrzeit  : 7|1@1+ (1.000000,0.000000) [0.000000|1.000000] "" Vector__XXX
 SG_ KBI_Einheit_Verbrauch  : 8|2@1+ (1.000000,0.000000) [0.000000|3.000000] "" Vector__XXX
 SG_ KBI_Einheit_Volumen  : 10|2@1+ (1.000000,0.000000) [0.000000|3.000000] "" Vector__XXX
 SG_ KBI_Einheit_Verbrauch_elektr  : 12|3@1+ (1.000000,0.000000) [0.000000|7.000000] "" Vector__XXX
 SG_ KBI_Einheit_Tacho  : 15|1@1+ (1.000000,0.000000) [0.000000|1.000000] "" Motor_BEV
 SG_ KBI_Einheit_Sprache  : 16|8@1+ (1.000000,0.000000) [0.000000|255.000000] "" Vector__XXX
 SG_ KBI_Einheit_Verbrauch_Gas  : 24|4@1+ (1.000000,0.000000) [0.000000|15.000000] "" Vector__XXX
 SG_ KBI_Einheit_Masse  : 28|2@1+ (1.000000,0.000000) [0.000000|3.000000] "" Vector__XXX
